VERSION "FM29 IBUS1 + IBUS2, V390.1 20230120, generated by sunnypilot/webhud/tools/gen_ibus.py"

NS_ :

BS_:

BU_: ADAS AMP FloatingButtons GW ICC MFSS PWC_L PWC_R RAC Rotator

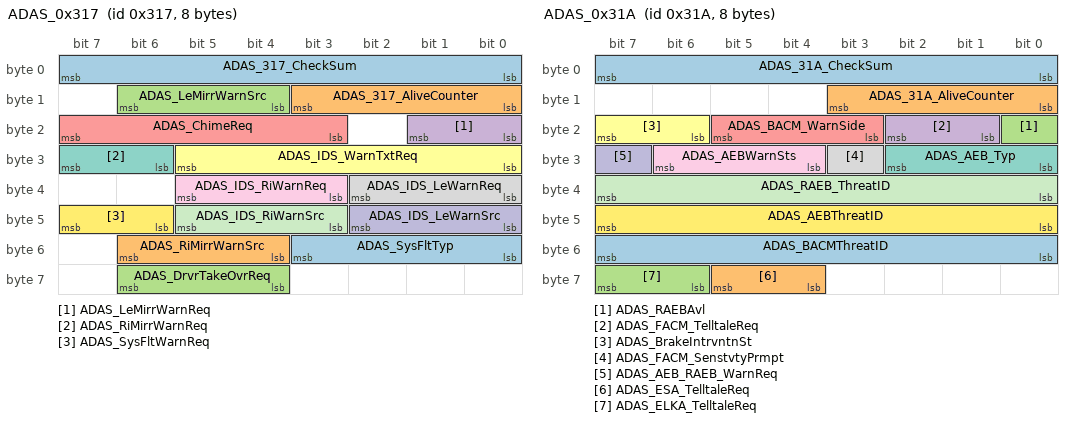
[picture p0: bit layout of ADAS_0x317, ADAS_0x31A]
BO_ 791 ADAS_0x317: 8 ADAS
 SG_ ADAS_317_CheckSum : 7|8@0+ (1,0) [0|255] "" ICC
 SG_ ADAS_317_AliveCounter : 11|4@0+ (1,0) [0|14] "" ICC
 SG_ ADAS_LeMirrWarnSrc : 14|3@0+ (1,0) [0|7] "" ICC
 SG_ ADAS_LeMirrWarnReq : 17|2@0+ (1,0) [0|3] "" ICC
 SG_ ADAS_ChimeReq : 23|5@0+ (1,0) [0|15] "" ICC
 SG_ ADAS_IDS_WarnTxtReq : 29|6@0+ (1,0) [0|63] "" ICC
 SG_ ADAS_RiMirrWarnReq : 31|2@0+ (1,0) [0|3] "" ICC
 SG_ ADAS_IDS_LeWarnReq : 34|3@0+ (1,0) [0|7] "" ICC
 SG_ ADAS_IDS_RiWarnReq : 37|3@0+ (1,0) [0|7] "" ICC
 SG_ ADAS_IDS_LeWarnSrc : 42|3@0+ (1,0) [0|7] "" ICC
 SG_ ADAS_IDS_RiWarnSrc : 45|3@0+ (1,0) [0|7] "" ICC
 SG_ ADAS_SysFltWarnReq : 47|2@0+ (1,0) [0|3] "" ICC
 SG_ ADAS_SysFltTyp : 51|4@0+ (1,0) [0|15] "" ICC
 SG_ ADAS_RiMirrWarnSrc : 54|3@0+ (1,0) [0|7] "" ICC
 SG_ ADAS_DrvrTakeOvrReq : 62|3@0+ (1,0) [0|7] "" ICC

BO_ 794 ADAS_0x31A: 8 ADAS
 SG_ ADAS_31A_CheckSum : 7|8@0+ (1,0) [0|255] "" ICC
 SG_ ADAS_31A_AliveCounter : 11|4@0+ (1,0) [0|14] "" ICC
 SG_ ADAS_RAEBAvl : 16|1@0+ (1,0) [0|1] "" ICC
 SG_ ADAS_FACM_TelltaleReq : 18|2@0+ (1,0) [0|3] "" ICC
 SG_ ADAS_BACM_WarnSide : 21|3@0+ (1,0) [0|7] "" ICC
 SG_ ADAS_BrakeIntrvntnSt : 23|2@0+ (1,0) [0|3] "" ICC
 SG_ ADAS_AEB_Typ : 26|3@0+ (1,0) [0|7] "" ICC
 SG_ ADAS_FACM_SenstvtyPrmpt : 27|1@0+ (1,0) [0|1] "" ICC
 SG_ ADAS_AEBWarnSts : 30|3@0+ (1,0) [0|7] "" ICC
 SG_ ADAS_AEB_RAEB_WarnReq : 31|1@0+ (1,0) [0|1] "" ICC
 SG_ ADAS_RAEB_ThreatID : 39|8@0+ (1,0) [0|255] "" ICC
 SG_ ADAS_AEBThreatID : 47|8@0+ (1,0) [0|255] "" ICC
 SG_ ADAS_BACMThreatID : 55|8@0+ (1,0) [0|255] "" ICC
 SG_ ADAS_ESA_TelltaleReq : 61|2@0+ (1,0) [0|3] "" ICC
 SG_ ADAS_ELKA_TelltaleReq : 63|2@0+ (1,0) [0|3] "" ICC

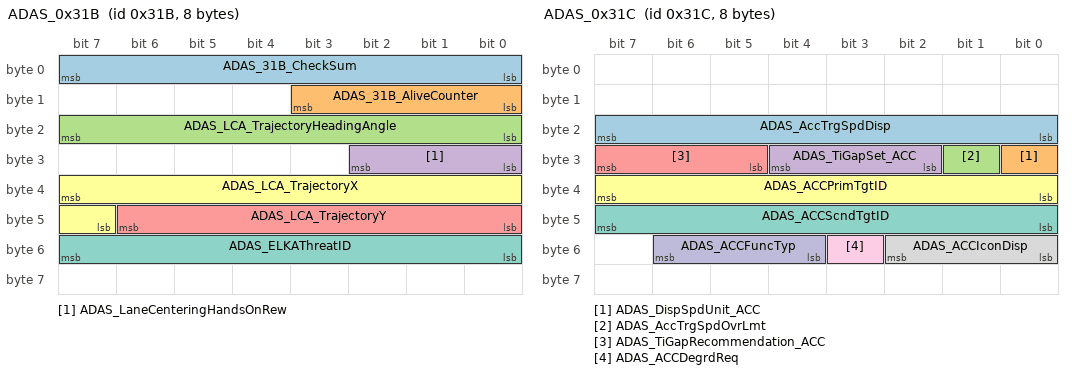
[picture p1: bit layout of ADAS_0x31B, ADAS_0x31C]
BO_ 795 ADAS_0x31B: 8 ADAS
 SG_ ADAS_31B_CheckSum : 7|8@0+ (1,0) [0|255] "" ICC
 SG_ ADAS_31B_AliveCounter : 11|4@0+ (1,0) [0|14] "" ICC
 SG_ ADAS_LCA_TrajectoryHeadingAngle : 23|8@0+ (1,-127) [-127|128] "" ICC
 SG_ ADAS_LaneCenteringHandsOnRew : 26|3@0+ (1,0) [0|7] "" ICC
 SG_ ADAS_LCA_TrajectoryY : 46|7@0+ (0.25,-63) [-63|-31.25] "" ICC
 SG_ ADAS_LCA_TrajectoryX : 39|9@0+ (1,0) [0|511] "" ICC
 SG_ ADAS_ELKAThreatID : 55|8@0+ (1,0) [0|255] "" ICC

BO_ 796 ADAS_0x31C: 8 ADAS
 SG_ ADAS_AccTrgSpdDisp : 23|8@0+ (1,0) [0|255] "" ICC
 SG_ ADAS_DispSpdUnit_ACC : 24|1@0+ (1,0) [0|1] "" ICC
 SG_ ADAS_AccTrgSpdOvrLmt : 25|1@0+ (1,0) [0|1] "" ICC
 SG_ ADAS_TiGapSet_ACC : 28|3@0+ (1,0) [0|7] "" ICC
 SG_ ADAS_TiGapRecommendation_ACC : 31|3@0+ (1,0) [0|7] "" ICC
 SG_ ADAS_ACCPrimTgtID : 39|8@0+ (1,0) [0|255] "" ICC
 SG_ ADAS_ACCScndTgtID : 47|8@0+ (1,0) [0|255] "" ICC
 SG_ ADAS_ACCIconDisp : 50|3@0+ (1,0) [0|7] "" ICC
 SG_ ADAS_ACCDegrdReq : 51|1@0+ (1,0) [0|1] "" ICC
 SG_ ADAS_ACCFuncTyp : 54|3@0+ (1,0) [0|7] "" ICC

BO_ 800 ICC_0x320: 8 ICC
 SG_ ICC_VehFlameoutTi : 7|16@0+ (1,0) [0|65535] "min" ICC
 SG_ ICC_VehFlameoutTiVld : 17|2@0+ (1,0) [0|3] "" ICC

BO_ 801 BCM_0x321: 8 GW
 SG_ BCM_AP_FL_LeFrntWinPosnInfo : 23|8@0+ (0.5,0) [0|100] "%" ICC
 SG_ BCM_AP_FL_RiFrntWinPosnInfo : 31|8@0+ (0.5,0) [0|100] "%" ICC
 SG_ BCM_AP_FL_LeReWinPosnInfo : 39|8@0+ (0.5,0) [0|100] "%" ICC
 SG_ BCM_AP_FL_RiReWinPosnInfo : 47|8@0+ (0.5,0) [0|100] "%" ICC
 SG_ BCM_ValueLightFrnt_RLS : 55|8@0+ (50,0) [0|12700] "w/m2" ICC
 SG_ BCM_LightReqReason_RLS : 60|5@0+ (1,0) [0|31] "" ICC

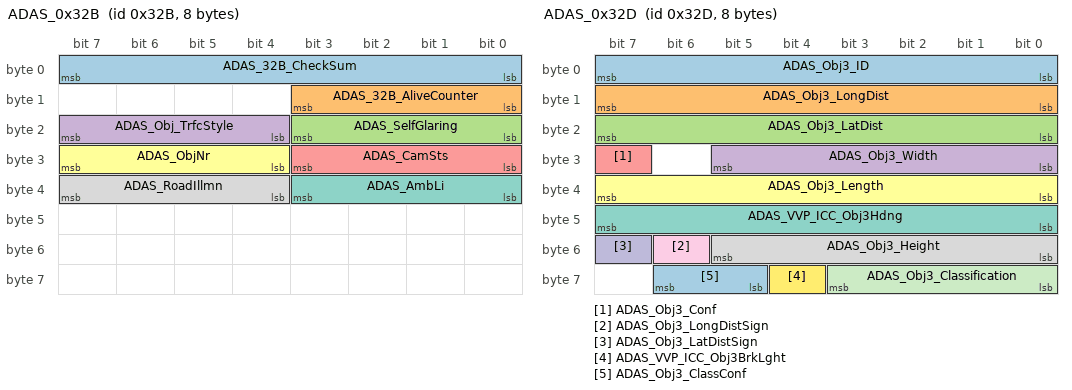
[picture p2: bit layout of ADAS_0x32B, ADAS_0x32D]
BO_ 811 ADAS_0x32B: 8 ADAS
 SG_ ADAS_32B_CheckSum : 7|8@0+ (1,0) [0|255] "" ICC
 SG_ ADAS_32B_AliveCounter : 11|4@0+ (1,0) [0|14] "" ICC
 SG_ ADAS_SelfGlaring : 19|4@0+ (1,0) [0|15] "" ICC
 SG_ ADAS_Obj_TrfcStyle : 23|4@0+ (1,0) [0|15] "" ICC
 SG_ ADAS_CamSts : 27|4@0+ (1,0) [0|15] "" ICC
 SG_ ADAS_ObjNr : 31|4@0+ (1,0) [0|15] "" ICC
 SG_ ADAS_AmbLi : 35|4@0+ (1,0) [0|15] "" ICC
 SG_ ADAS_RoadIllmn : 39|4@0+ (1,0) [0|15] "" ICC

BO_ 813 ADAS_0x32D: 8 ADAS
 SG_ ADAS_Obj3_ID : 7|8@0+ (1,0) [0|255] "" ICC
 SG_ ADAS_Obj3_LongDist : 15|8@0+ (0.2,0) [0|51] "m" ICC
 SG_ ADAS_Obj3_LatDist : 23|8@0+ (0.2,0) [0|51] "m" ICC
 SG_ ADAS_Obj3_Width : 29|6@0+ (0.1,0) [0|6.3] "m" ICC
 SG_ ADAS_Obj3_Conf : 31|1@0+ (1,0) [0|1] "" ICC
 SG_ ADAS_Obj3_Length : 39|8@0+ (0.2,0) [0|50] "m" ICC
 SG_ ADAS_VVP_ICC_Obj3Hdng : 47|8@0+ (1.5,0) [0|360] "deg" ICC
 SG_ ADAS_Obj3_Height : 53|6@0+ (0.1,0) [0|6.3] "m" ICC
 SG_ ADAS_Obj3_LongDistSign : 54|1@0+ (1,0) [0|1] "" ICC
 SG_ ADAS_Obj3_LatDistSign : 55|1@0+ (1,0) [0|1] "" ICC
 SG_ ADAS_Obj3_Classification : 59|4@0+ (1,0) [0|15] "" ICC
 SG_ ADAS_VVP_ICC_Obj3BrkLght : 60|1@0+ (1,0) [0|1] "" ICC
 SG_ ADAS_Obj3_ClassConf : 62|2@0+ (1,0) [0|3] "" ICC

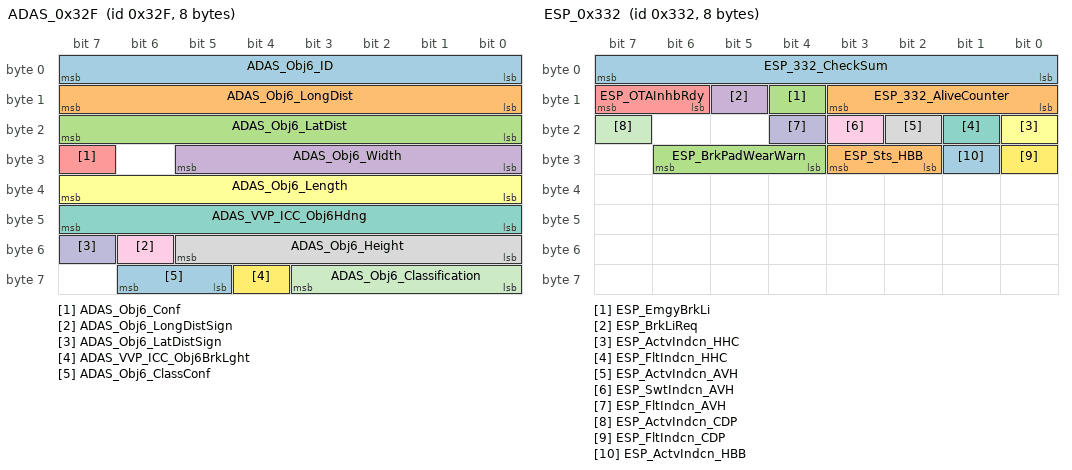
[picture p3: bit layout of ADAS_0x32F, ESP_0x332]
BO_ 815 ADAS_0x32F: 8 ADAS
 SG_ ADAS_Obj6_ID : 7|8@0+ (1,0) [0|255] "" ICC
 SG_ ADAS_Obj6_LongDist : 15|8@0+ (0.2,0) [0|51] "m" ICC
 SG_ ADAS_Obj6_LatDist : 23|8@0+ (0.2,0) [0|51] "m" ICC
 SG_ ADAS_Obj6_Width : 29|6@0+ (0.1,0) [0|6.3] "m" ICC
 SG_ ADAS_Obj6_Conf : 31|1@0+ (1,0) [0|1] "" ICC
 SG_ ADAS_Obj6_Length : 39|8@0+ (0.2,0) [0|50] "m" ICC
 SG_ ADAS_VVP_ICC_Obj6Hdng : 47|8@0+ (1.5,0) [0|360] "deg" ICC
 SG_ ADAS_Obj6_Height : 53|6@0+ (0.1,0) [0|6.3] "m" ICC
 SG_ ADAS_Obj6_LongDistSign : 54|1@0+ (1,0) [0|1] "" ICC
 SG_ ADAS_Obj6_LatDistSign : 55|1@0+ (1,0) [0|1] "" ICC
 SG_ ADAS_Obj6_Classification : 59|4@0+ (1,0) [0|15] "" ICC
 SG_ ADAS_VVP_ICC_Obj6BrkLght : 60|1@0+ (1,0) [0|1] "" ICC
 SG_ ADAS_Obj6_ClassConf : 62|2@0+ (1,0) [0|3] "" ICC

BO_ 818 ESP_0x332: 8 GW
 SG_ ESP_332_CheckSum : 7|8@0+ (1,0) [0|255] "" ICC
 SG_ ESP_332_AliveCounter : 11|4@0+ (1,0) [0|14] "" ICC
 SG_ ESP_EmgyBrkLi : 12|1@0+ (1,0) [0|1] "" ICC
 SG_ ESP_BrkLiReq : 13|1@0+ (1,0) [0|1] "" ICC
 SG_ ESP_OTAInhbRdy : 15|2@0+ (1,0) [0|3] "" ICC
 SG_ ESP_ActvIndcn_HHC : 16|1@0+ (1,0) [0|1] "" ICC
 SG_ ESP_FltIndcn_HHC : 17|1@0+ (1,0) [0|1] "" ICC
 SG_ ESP_ActvIndcn_AVH : 18|1@0+ (1,0) [0|1] "" ICC
 SG_ ESP_SwtIndcn_AVH : 19|1@0+ (1,0) [0|1] "" ICC
 SG_ ESP_FltIndcn_AVH : 20|1@0+ (1,0) [0|1] "" ICC
 SG_ ESP_ActvIndcn_CDP : 23|1@0+ (1,0) [0|1] "" ICC
 SG_ ESP_FltIndcn_CDP : 24|1@0+ (1,0) [0|1] "" ICC
 SG_ ESP_ActvIndcn_HBB : 25|1@0+ (1,0) [0|1] "" ICC
 SG_ ESP_Sts_HBB : 27|2@0+ (1,0) [0|3] "" ICC
 SG_ ESP_BrkPadWearWarn : 30|3@0+ (1,0) [0|7] "" ICC

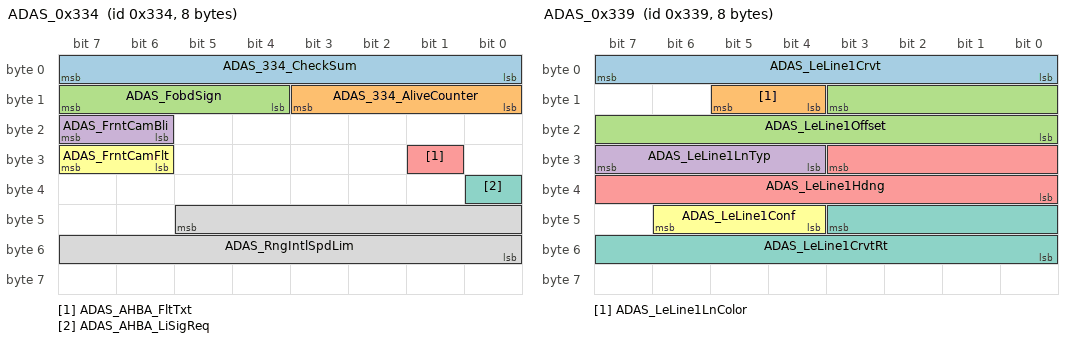
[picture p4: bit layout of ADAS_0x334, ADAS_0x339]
BO_ 820 ADAS_0x334: 8 ADAS
 SG_ ADAS_334_CheckSum : 7|8@0+ (1,0) [0|255] "" ICC
 SG_ ADAS_334_AliveCounter : 11|4@0+ (1,0) [0|14] "" ICC
 SG_ ADAS_FobdSign : 15|4@0+ (1,0) [0|15] "" ICC
 SG_ ADAS_FrntCamBli : 23|2@0+ (1,0) [0|3] "" ICC
 SG_ ADAS_AHBA_FltTxt : 25|1@0+ (1,0) [0|1] "" ICC
 SG_ ADAS_FrntCamFlt : 31|2@0+ (1,0) [0|3] "" ICC
 SG_ ADAS_AHBA_LiSigReq : 32|1@0+ (1,0) [0|1] "" ICC
 SG_ ADAS_RngIntlSpdLim : 45|14@0+ (10,0) [0|100000] "m" ICC

BO_ 825 ADAS_0x339: 8 ADAS
 SG_ ADAS_LeLine1Crvt : 7|8@0+ (50,-3150) [-3150|3200] "m" ICC
 SG_ ADAS_LeLine1LnColor : 13|2@0+ (1,0) [0|3] "" ICC
 SG_ ADAS_LeLine1Offset : 11|12@0+ (0.0125,0) [0|50] "m" ICC
 SG_ ADAS_LeLine1LnTyp : 31|4@0+ (1,0) [0|15] "" ICC
 SG_ ADAS_LeLine1Hdng : 27|12@0+ (0.05,0) [0|180] "deg" ICC
 SG_ ADAS_LeLine1Conf : 46|3@0+ (1,0) [0|7] "" ICC
 SG_ ADAS_LeLine1CrvtRt : 43|12@0+ (0.05,0) [0|180] "xx" ICC

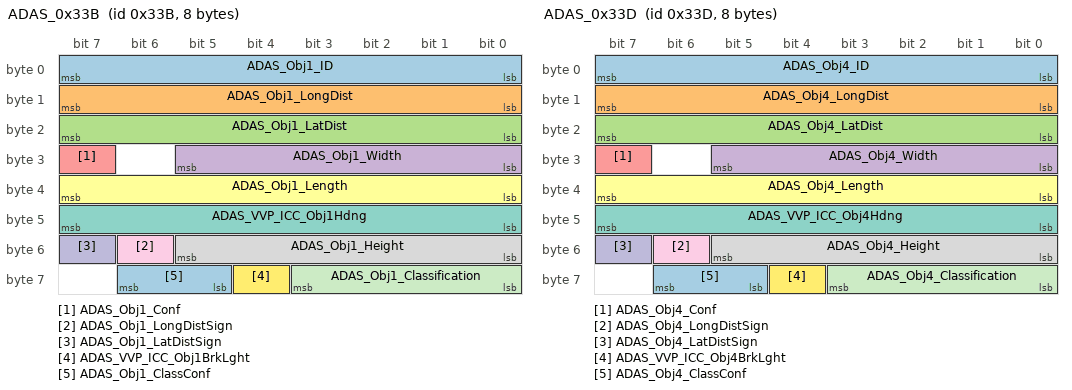
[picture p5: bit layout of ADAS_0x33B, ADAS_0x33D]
BO_ 827 ADAS_0x33B: 8 ADAS
 SG_ ADAS_Obj1_ID : 7|8@0+ (1,0) [0|255] "" ICC
 SG_ ADAS_Obj1_LongDist : 15|8@0+ (0.2,0) [0|51] "m" ICC
 SG_ ADAS_Obj1_LatDist : 23|8@0+ (0.2,0) [0|51] "m" ICC
 SG_ ADAS_Obj1_Width : 29|6@0+ (0.1,0) [0|6.3] "m" ICC
 SG_ ADAS_Obj1_Conf : 31|1@0+ (1,0) [0|1] "" ICC
 SG_ ADAS_Obj1_Length : 39|8@0+ (0.2,0) [0|50] "m" ICC
 SG_ ADAS_VVP_ICC_Obj1Hdng : 47|8@0+ (1.5,0) [0|360] "deg" ICC
 SG_ ADAS_Obj1_Height : 53|6@0+ (0.1,0) [0|6.3] "m" ICC
 SG_ ADAS_Obj1_LongDistSign : 54|1@0+ (1,0) [0|1] "" ICC
 SG_ ADAS_Obj1_LatDistSign : 55|1@0+ (1,0) [0|1] "" ICC
 SG_ ADAS_Obj1_Classification : 59|4@0+ (1,0) [0|15] "" ICC
 SG_ ADAS_VVP_ICC_Obj1BrkLght : 60|1@0+ (1,0) [0|1] "" ICC
 SG_ ADAS_Obj1_ClassConf : 62|2@0+ (1,0) [0|3] "" ICC

BO_ 829 ADAS_0x33D: 8 ADAS
 SG_ ADAS_Obj4_ID : 7|8@0+ (1,0) [0|255] "" ICC
 SG_ ADAS_Obj4_LongDist : 15|8@0+ (0.2,0) [0|51] "m" ICC
 SG_ ADAS_Obj4_LatDist : 23|8@0+ (0.2,0) [0|51] "m" ICC
 SG_ ADAS_Obj4_Width : 29|6@0+ (0.1,0) [0|6.3] "m" ICC
 SG_ ADAS_Obj4_Conf : 31|1@0+ (1,0) [0|1] "" ICC
 SG_ ADAS_Obj4_Length : 39|8@0+ (0.2,0) [0|50] "m" ICC
 SG_ ADAS_VVP_ICC_Obj4Hdng : 47|8@0+ (1.5,0) [0|360] "deg" ICC
 SG_ ADAS_Obj4_Height : 53|6@0+ (0.1,0) [0|6.3] "m" ICC
 SG_ ADAS_Obj4_LongDistSign : 54|1@0+ (1,0) [0|1] "" ICC
 SG_ ADAS_Obj4_LatDistSign : 55|1@0+ (1,0) [0|1] "" ICC
 SG_ ADAS_Obj4_Classification : 59|4@0+ (1,0) [0|15] "" ICC
 SG_ ADAS_VVP_ICC_Obj4BrkLght : 60|1@0+ (1,0) [0|1] "" ICC
 SG_ ADAS_Obj4_ClassConf : 62|2@0+ (1,0) [0|3] "" ICC

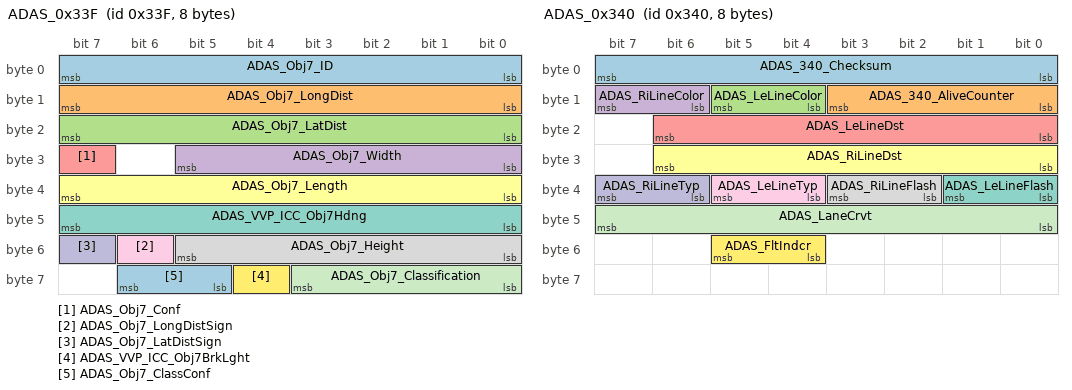
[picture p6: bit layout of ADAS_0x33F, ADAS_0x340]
BO_ 831 ADAS_0x33F: 8 ADAS
 SG_ ADAS_Obj7_ID : 7|8@0+ (1,0) [0|255] "" ICC
 SG_ ADAS_Obj7_LongDist : 15|8@0+ (0.2,0) [0|51] "m" ICC
 SG_ ADAS_Obj7_LatDist : 23|8@0+ (0.2,0) [0|51] "m" ICC
 SG_ ADAS_Obj7_Width : 29|6@0+ (0.1,0) [0|6.3] "m" ICC
 SG_ ADAS_Obj7_Conf : 31|1@0+ (1,0) [0|1] "" ICC
 SG_ ADAS_Obj7_Length : 39|8@0+ (0.2,0) [0|50] "m" ICC
 SG_ ADAS_VVP_ICC_Obj7Hdng : 47|8@0+ (1.5,0) [0|360] "deg" ICC
 SG_ ADAS_Obj7_Height : 53|6@0+ (0.1,0) [0|6.3] "m" ICC
 SG_ ADAS_Obj7_LongDistSign : 54|1@0+ (1,0) [0|1] "" ICC
 SG_ ADAS_Obj7_LatDistSign : 55|1@0+ (1,0) [0|1] "" ICC
 SG_ ADAS_Obj7_Classification : 59|4@0+ (1,0) [0|15] "" ICC
 SG_ ADAS_VVP_ICC_Obj7BrkLght : 60|1@0+ (1,0) [0|1] "" ICC
 SG_ ADAS_Obj7_ClassConf : 62|2@0+ (1,0) [0|3] "" ICC

BO_ 832 ADAS_0x340: 8 ADAS
 SG_ ADAS_340_Checksum : 7|8@0+ (1,0) [0|255] "" ICC
 SG_ ADAS_340_AliveCounter : 11|4@0+ (1,0) [0|14] "" ICC
 SG_ ADAS_LeLineColor : 13|2@0+ (1,0) [0|3] "" ICC
 SG_ ADAS_RiLineColor : 15|2@0+ (1,0) [0|3] "" ICC
 SG_ ADAS_LeLineDst : 22|7@0+ (0.1,-6.2) [-6.2|6.2] "m" ICC
 SG_ ADAS_RiLineDst : 30|7@0+ (0.1,-6.2) [-6.2|6.2] "m" ICC
 SG_ ADAS_LeLineFlash : 33|2@0+ (1,0) [0|3] "" ICC
 SG_ ADAS_RiLineFlash : 35|2@0+ (1,0) [0|3] "" ICC
 SG_ ADAS_LeLineTyp : 37|2@0+ (1,0) [0|3] "" ICC
 SG_ ADAS_RiLineTyp : 39|2@0+ (1,0) [0|3] "" ICC
 SG_ ADAS_LaneCrvt : 47|8@0+ (50,-3150) [-3150|3200] "m" ICC
 SG_ ADAS_FltIndcr : 53|2@0+ (1,0) [0|3] "" ICC

BO_ 834 ADAS_0x342: 8 ADAS
 SG_ ADAS_342_Checksum : 7|8@0+ (1,0) [0|255] "" ICC
 SG_ ADAS_342_AliveCounter : 11|4@0+ (1,0) [0|14] "" ICC
 SG_ ADAS_LatCtrl_LeTurnLampReq : 13|2@0+ (1,0) [0|3] "" ICC
 SG_ ADAS_LatCtrl_RiTurnLampReq : 15|2@0+ (1,0) [0|3] "" ICC
 SG_ ADAS_LatCtrl_HapticReq : 17|2@0+ (1,0) [0|3] "" ICC
 SG_ ADAS_LatCtrl_HzrdLampReq : 19|2@0+ (1,0) [0|3] "" ICC
 SG_ ADAS_VehMovDir : 21|2@0+ (1,0) [0|3] "" ICC
 SG_ ADAS_HOD_HandsOnWarnReq : 23|2@0+ (1,0) [0|1] "" ICC
 SG_ ADAS_DoorLockReq : 25|2@0+ (1,0) [0|3] "" ICC
 SG_ ADAS_AVASReq : 27|2@0+ (1,0) [0|3] "" ICC
 SG_ ADAS_RAPAvl : 28|1@0+ (1,0) [0|1] "" ICC
 SG_ ADAS_TPReplayAvl : 29|1@0+ (1,0) [0|1] "" ICC
 SG_ ADAS_TPReplaySuc : 30|1@0+ (1,0) [0|1] "" ICC
 SG_ ADAS_Sts_RAP : 34|3@0+ (1,0) [0|7] "" ICC
 SG_ ADAS_Sts_TP : 37|3@0+ (1,0) [0|7] "" ICC
 SG_ ADAS_ExtLightReq : 38|1@0+ (1,0) [0|1] "" ICC
 SG_ ADAS_HODSts : 42|3@0+ (1,0) [0|7] "" ICC

BO_ 836 ICC_0x344: 8 ICC
 SG_ ICC_NavMsgText1 : 7|64@0+ (1,0) [0|1.84467e+19] "" ICC

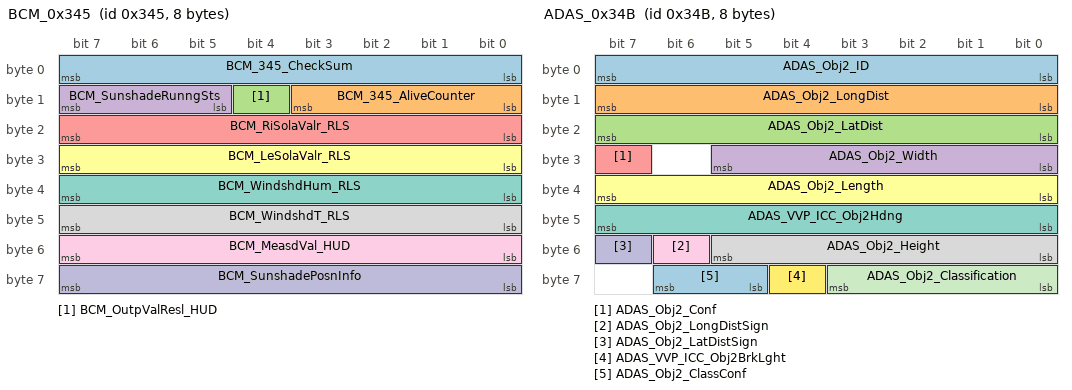
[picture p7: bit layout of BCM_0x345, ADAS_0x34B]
BO_ 837 BCM_0x345: 8 GW
 SG_ BCM_345_CheckSum : 7|8@0+ (1,0) [0|255] "" ICC
 SG_ BCM_345_AliveCounter : 11|4@0+ (1,0) [0|14] "" ICC
 SG_ BCM_OutpValResl_HUD : 12|1@0+ (1,0) [0|1] "" ICC
 SG_ BCM_SunshadeRunngSts : 15|3@0+ (1,0) [0|7] "" ICC
 SG_ BCM_RiSolaValr_RLS : 23|8@0+ (4.01575,0) [0|1024.02] "W/m2" ICC
 SG_ BCM_LeSolaValr_RLS : 31|8@0+ (4.01575,0) [0|1024.02] "W/m2" ICC
 SG_ BCM_WindshdHum_RLS : 39|8@0+ (0.5,0) [0|127.5] "%" ICC
 SG_ BCM_WindshdT_RLS : 47|8@0+ (0.5,-40) [-40|87.5] "Degree Celsius" ICC
 SG_ BCM_MeasdVal_HUD : 55|8@0+ (1,0) [0|255] "" ICC
 SG_ BCM_SunshadePosnInfo : 63|8@0+ (1,0) [0|100] "" ICC

BO_ 841 ICC_0x349: 8 ICC
 SG_ ICC_KaraokeMsgText1 : 7|64@0+ (1,0) [0|1.84467e+19] "" ICC

BO_ 843 ADAS_0x34B: 8 ADAS
 SG_ ADAS_Obj2_ID : 7|8@0+ (1,0) [0|255] "" ICC
 SG_ ADAS_Obj2_LongDist : 15|8@0+ (0.2,0) [0|51] "m" ICC
 SG_ ADAS_Obj2_LatDist : 23|8@0+ (0.2,0) [0|51] "m" ICC
 SG_ ADAS_Obj2_Width : 29|6@0+ (0.1,0) [0|6.3] "m" ICC
 SG_ ADAS_Obj2_Conf : 31|1@0+ (1,0) [0|1] "" ICC
 SG_ ADAS_Obj2_Length : 39|8@0+ (0.2,0) [0|50] "m" ICC
 SG_ ADAS_VVP_ICC_Obj2Hdng : 47|8@0+ (1.5,0) [0|360] "deg" ICC
 SG_ ADAS_Obj2_Height : 53|6@0+ (0.1,0) [0|6.3] "m" ICC
 SG_ ADAS_Obj2_LongDistSign : 54|1@0+ (1,0) [0|1] "" ICC
 SG_ ADAS_Obj2_LatDistSign : 55|1@0+ (1,0) [0|1] "" ICC
 SG_ ADAS_Obj2_Classification : 59|4@0+ (1,0) [0|15] "" ICC
 SG_ ADAS_VVP_ICC_Obj2BrkLght : 60|1@0+ (1,0) [0|1] "" ICC
 SG_ ADAS_Obj2_ClassConf : 62|2@0+ (1,0) [0|3] "" ICC

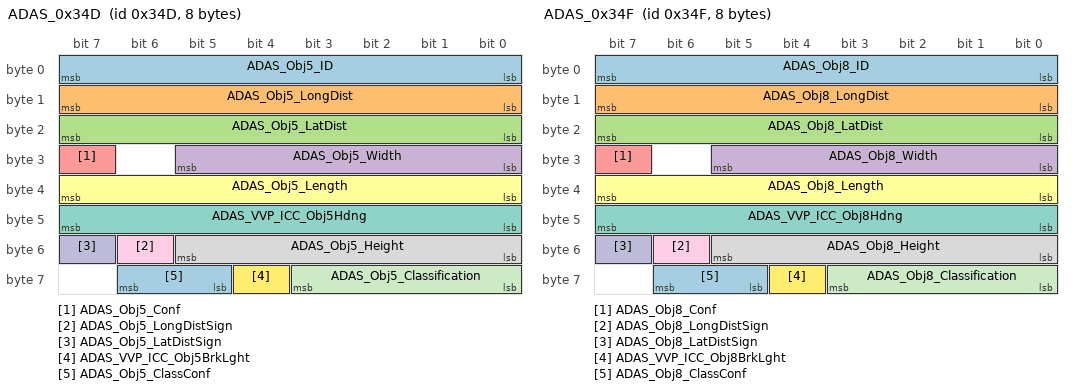
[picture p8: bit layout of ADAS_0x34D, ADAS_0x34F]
BO_ 845 ADAS_0x34D: 8 ADAS
 SG_ ADAS_Obj5_ID : 7|8@0+ (1,0) [0|255] "" ICC
 SG_ ADAS_Obj5_LongDist : 15|8@0+ (0.2,0) [0|51] "m" ICC
 SG_ ADAS_Obj5_LatDist : 23|8@0+ (0.2,0) [0|51] "m" ICC
 SG_ ADAS_Obj5_Width : 29|6@0+ (0.1,0) [0|6.3] "m" ICC
 SG_ ADAS_Obj5_Conf : 31|1@0+ (1,0) [0|1] "" ICC
 SG_ ADAS_Obj5_Length : 39|8@0+ (0.2,0) [0|50] "m" ICC
 SG_ ADAS_VVP_ICC_Obj5Hdng : 47|8@0+ (1.5,0) [0|360] "deg" ICC
 SG_ ADAS_Obj5_Height : 53|6@0+ (0.1,0) [0|6.3] "m" ICC
 SG_ ADAS_Obj5_LongDistSign : 54|1@0+ (1,0) [0|1] "" ICC
 SG_ ADAS_Obj5_LatDistSign : 55|1@0+ (1,0) [0|1] "" ICC
 SG_ ADAS_Obj5_Classification : 59|4@0+ (1,0) [0|15] "" ICC
 SG_ ADAS_VVP_ICC_Obj5BrkLght : 60|1@0+ (1,0) [0|1] "" ICC
 SG_ ADAS_Obj5_ClassConf : 62|2@0+ (1,0) [0|3] "" ICC

BO_ 847 ADAS_0x34F: 8 ADAS
 SG_ ADAS_Obj8_ID : 7|8@0+ (1,0) [0|255] "" ICC
 SG_ ADAS_Obj8_LongDist : 15|8@0+ (0.2,0) [0|51] "m" ICC
 SG_ ADAS_Obj8_LatDist : 23|8@0+ (0.2,0) [0|51] "m" ICC
 SG_ ADAS_Obj8_Width : 29|6@0+ (0.1,0) [0|6.3] "m" ICC
 SG_ ADAS_Obj8_Conf : 31|1@0+ (1,0) [0|1] "" ICC
 SG_ ADAS_Obj8_Length : 39|8@0+ (0.2,0) [0|50] "m" ICC
 SG_ ADAS_VVP_ICC_Obj8Hdng : 47|8@0+ (1.5,0) [0|360] "deg" ICC
 SG_ ADAS_Obj8_Height : 53|6@0+ (0.1,0) [0|6.3] "m" ICC
 SG_ ADAS_Obj8_LongDistSign : 54|1@0+ (1,0) [0|1] "" ICC
 SG_ ADAS_Obj8_LatDistSign : 55|1@0+ (1,0) [0|1] "" ICC
 SG_ ADAS_Obj8_Classification : 59|4@0+ (1,0) [0|15] "" ICC
 SG_ ADAS_VVP_ICC_Obj8BrkLght : 60|1@0+ (1,0) [0|1] "" ICC
 SG_ ADAS_Obj8_ClassConf : 62|2@0+ (1,0) [0|3] "" ICC

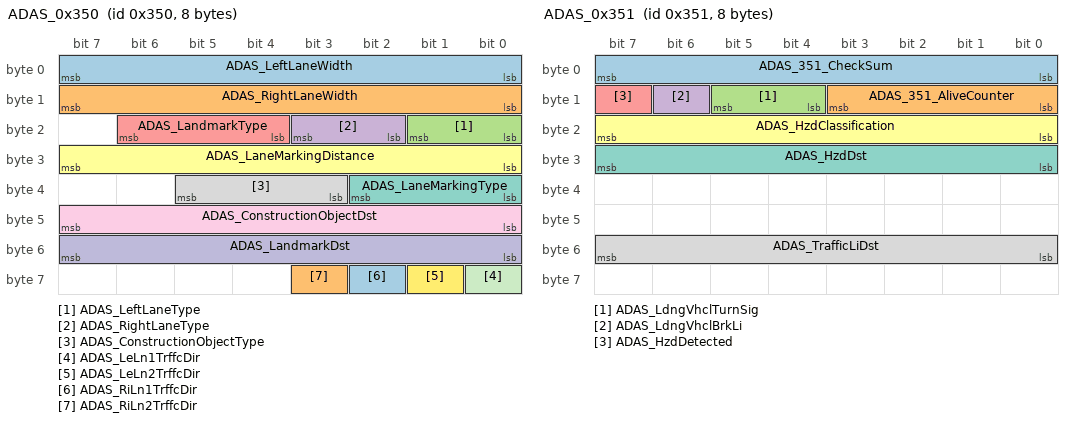
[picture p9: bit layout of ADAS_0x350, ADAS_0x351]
BO_ 848 ADAS_0x350: 8 ADAS
 SG_ ADAS_LeftLaneWidth : 7|8@0+ (0.1,0) [0|25.5] "m" ICC
 SG_ ADAS_RightLaneWidth : 15|8@0+ (0.1,0) [0|25.5] "m" ICC
 SG_ ADAS_LeftLaneType : 17|2@0+ (1,0) [0|3] "" ICC
 SG_ ADAS_RightLaneType : 19|2@0+ (1,0) [0|3] "" ICC
 SG_ ADAS_LandmarkType : 22|3@0+ (1,0) [0|7] "" ICC
 SG_ ADAS_LaneMarkingDistance : 31|8@0+ (1,0) [0|255] "m" ICC
 SG_ ADAS_LaneMarkingType : 34|3@0+ (1,0) [0|7] "" ICC
 SG_ ADAS_ConstructionObjectType : 37|3@0+ (1,0) [0|7] "" ICC
 SG_ ADAS_ConstructionObjectDst : 47|8@0+ (1,0) [0|255] "m" ICC
 SG_ ADAS_LandmarkDst : 55|8@0+ (1,0) [0|255] "m" ICC
 SG_ ADAS_LeLn1TrffcDir : 56|1@0+ (1,0) [0|1] "" ICC
 SG_ ADAS_LeLn2TrffcDir : 57|1@0+ (1,0) [0|1] "" ICC
 SG_ ADAS_RiLn1TrffcDir : 58|1@0+ (1,0) [0|1] "" ICC
 SG_ ADAS_RiLn2TrffcDir : 59|1@0+ (1,0) [0|1] "" ICC

BO_ 849 ADAS_0x351: 8 ADAS
 SG_ ADAS_351_CheckSum : 7|8@0+ (1,0) [0|255] "" ICC
 SG_ ADAS_351_AliveCounter : 11|4@0+ (1,0) [0|14] "" ICC
 SG_ ADAS_LdngVhclTurnSig : 13|2@0+ (1,0) [0|3] "" ICC
 SG_ ADAS_LdngVhclBrkLi : 14|1@0+ (1,0) [0|1] "" ICC
 SG_ ADAS_HzdDetected : 15|1@0+ (1,0) [0|1] "" ICC
 SG_ ADAS_HzdClassification : 23|8@0+ (1,0) [0|255] "" ICC
 SG_ ADAS_HzdDst : 31|8@0+ (1,0) [0|255] "m" ICC
 SG_ ADAS_TrafficLiDst : 55|8@0+ (1,0) [0|255] "m" ICC

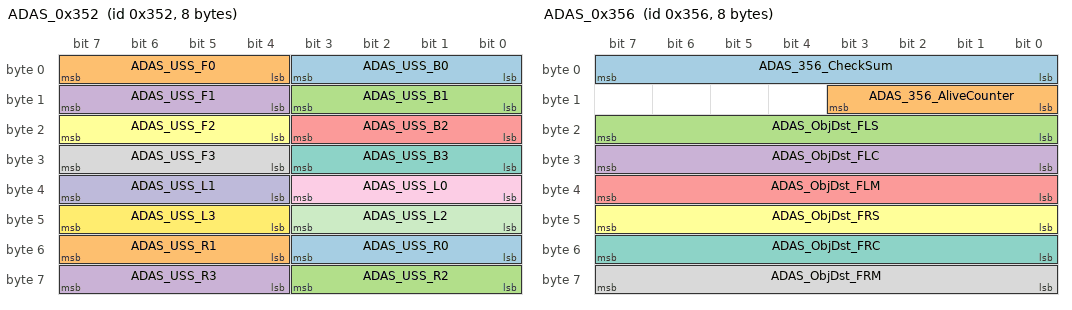
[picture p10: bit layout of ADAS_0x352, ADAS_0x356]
BO_ 850 ADAS_0x352: 8 ADAS
 SG_ ADAS_USS_B0 : 3|4@0+ (1,0) [0|15] "" ICC
 SG_ ADAS_USS_F0 : 7|4@0+ (1,0) [0|15] "" ICC
 SG_ ADAS_USS_B1 : 11|4@0+ (1,0) [0|15] "" ICC
 SG_ ADAS_USS_F1 : 15|4@0+ (1,0) [0|15] "" ICC
 SG_ ADAS_USS_B2 : 19|4@0+ (1,0) [0|15] "" ICC
 SG_ ADAS_USS_F2 : 23|4@0+ (1,0) [0|15] "" ICC
 SG_ ADAS_USS_B3 : 27|4@0+ (1,0) [0|15] "" ICC
 SG_ ADAS_USS_F3 : 31|4@0+ (1,0) [0|15] "" ICC
 SG_ ADAS_USS_L0 : 35|4@0+ (1,0) [0|15] "" ICC
 SG_ ADAS_USS_L1 : 39|4@0+ (1,0) [0|15] "" ICC
 SG_ ADAS_USS_L2 : 43|4@0+ (1,0) [0|15] "" ICC
 SG_ ADAS_USS_L3 : 47|4@0+ (1,0) [0|15] "" ICC
 SG_ ADAS_USS_R0 : 51|4@0+ (1,0) [0|15] "" ICC
 SG_ ADAS_USS_R1 : 55|4@0+ (1,0) [0|15] "" ICC
 SG_ ADAS_USS_R2 : 59|4@0+ (1,0) [0|15] "" ICC
 SG_ ADAS_USS_R3 : 63|4@0+ (1,0) [0|15] "" ICC

BO_ 851 ADAS_0x353: 8 ADAS
 SG_ ADAS_353_CheckSum : 7|8@0+ (1,0) [0|255] "" ICC
 SG_ ADAS_353_AliveCounter : 11|4@0+ (1,0) [0|14] "" ICC
 SG_ ADAS_VwPrtCamAngl : 23|4@0+ (1,0) [0|15] "" ICC
 SG_ ADAS_LdngVhclID : 31|8@0+ (1,0) [0|255] "" ICC

BO_ 854 ADAS_0x356: 8 ADAS
 SG_ ADAS_356_CheckSum : 7|8@0+ (1,0) [0|255] "" ICC
 SG_ ADAS_356_AliveCounter : 11|4@0+ (1,0) [0|14] "" ICC
 SG_ ADAS_ObjDst_FLS : 23|8@0+ (1,0) [0|255] "cm" ICC
 SG_ ADAS_ObjDst_FLC : 31|8@0+ (1,0) [0|255] "cm" ICC
 SG_ ADAS_ObjDst_FLM : 39|8@0+ (1,0) [0|255] "cm" ICC
 SG_ ADAS_ObjDst_FRS : 47|8@0+ (1,0) [0|255] "cm" ICC
 SG_ ADAS_ObjDst_FRC : 55|8@0+ (1,0) [0|255] "cm" ICC
 SG_ ADAS_ObjDst_FRM : 63|8@0+ (1,0) [0|255] "cm" ICC

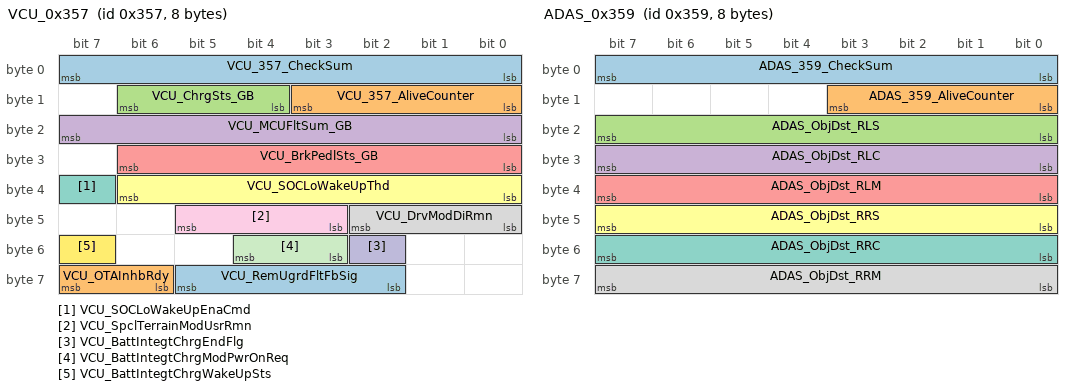
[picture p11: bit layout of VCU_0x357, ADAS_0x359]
BO_ 855 VCU_0x357: 8 GW
 SG_ VCU_357_CheckSum : 7|8@0+ (1,0) [0|255] "" ICC
 SG_ VCU_357_AliveCounter : 11|4@0+ (1,0) [0|14] "" ICC
 SG_ VCU_ChrgSts_GB : 14|3@0+ (1,0) [0|7] "" ICC
 SG_ VCU_MCUFltSum_GB : 23|8@0+ (1,0) [0|255] "" ICC
 SG_ VCU_BrkPedlSts_GB : 30|7@0+ (1,0) [0|127] "" ICC
 SG_ VCU_SOCLoWakeUpThd : 38|7@0+ (1,0) [0|100] "%" ICC
 SG_ VCU_SOCLoWakeUpEnaCmd : 39|1@0+ (1,0) [0|1] "" ICC
 SG_ VCU_DrvModDiRmn : 42|3@0+ (1,0) [0|7] "" ICC
 SG_ VCU_SpclTerrainModUsrRmn : 45|3@0+ (1,0) [0|7] "" ICC
 SG_ VCU_BattIntegtChrgEndFlg : 50|1@0+ (1,0) [0|1] "" ICC
 SG_ VCU_BattIntegtChrgModPwrOnReq : 52|2@0+ (1,0) [0|3] "" ICC
 SG_ VCU_BattIntegtChrgWakeUpSts : 55|1@0+ (1,0) [0|1] "" ICC
 SG_ VCU_RemUgrdFltFbSig : 61|4@0+ (1,0) [0|15] "" ICC
 SG_ VCU_OTAInhbRdy : 63|2@0+ (1,0) [0|3] "" ICC

BO_ 857 ADAS_0x359: 8 ADAS
 SG_ ADAS_359_CheckSum : 7|8@0+ (1,0) [0|255] "" ICC
 SG_ ADAS_359_AliveCounter : 11|4@0+ (1,0) [0|14] "" ICC
 SG_ ADAS_ObjDst_RLS : 23|8@0+ (1,0) [0|255] "cm" ICC
 SG_ ADAS_ObjDst_RLC : 31|8@0+ (1,0) [0|255] "cm" ICC
 SG_ ADAS_ObjDst_RLM : 39|8@0+ (1,0) [0|255] "cm" ICC
 SG_ ADAS_ObjDst_RRS : 47|8@0+ (1,0) [0|255] "cm" ICC
 SG_ ADAS_ObjDst_RRC : 55|8@0+ (1,0) [0|255] "cm" ICC
 SG_ ADAS_ObjDst_RRM : 63|8@0+ (1,0) [0|255] "cm" ICC

BO_ 859 ICC_0x35B: 8 ICC
 SG_ ICC_ViewReq : 15|4@0+ (1,0) [0|15] "" ICC
 SG_ ICC_ShowSts : 16|1@0+ (1,0) [0|1] "" ICC
 SG_ ICC_SVS_AutoVwBttnReq : 17|1@0+ (1,0) [0|1] "" ICC
 SG_ ICC_SVS_CamVwCnclReq : 18|1@0+ (1,0) [0|1] "" ICC
 SG_ ICC_AutomaticViewReq : 19|1@0+ (1,0) [0|1] "" ICC
 SG_ ICC_360FreeFloatingReq : 20|1@0+ (1,0) [0|1] "" ICC
 SG_ ICC_GraphicOverlayReq : 21|1@0+ (1,0) [0|1] "" ICC
 SG_ ICC_OperationType : 23|2@0+ (1,0) [0|3] "" ICC
 SG_ ICC_ZOOM_Start : 24|1@0+ (1,0) [0|1] "" ICC
 SG_ ICC_ZOOM_End : 25|1@0+ (1,0) [0|1] "" ICC
 SG_ ICC_ZOOM_ScalingFactor : 30|5@0+ (1,0) [0|31] "" ICC
 SG_ ICC_EnbLnChgAsst : 31|1@0+ (1,0) [0|1] "" ICC
 SG_ ICC_BSDSetting : 33|2@0+ (1,0) [0|3] "" ICC
 SG_ ICC_DOW_Setting : 35|2@0+ (1,0) [0|3] "" ICC
 SG_ ICC_DCAASetting : 37|2@0+ (1,0) [0|3] "" ICC
 SG_ ICC_APA_Setting : 39|2@0+ (1,0) [0|3] "" ICC
 SG_ ICC_APAParkSelect : 43|4@0+ (1,0) [0|15] "" ICC
 SG_ ICC_APAActivation : 44|1@0+ (1,0) [0|1] "" ICC
 SG_ ICC_APAParkInDirSetting : 45|1@0+ (1,0) [0|1] "" ICC
 SG_ ICC_APAParkOutDirSetting : 46|1@0+ (1,0) [0|1] "" ICC
 SG_ ICC_ParkAsstChmAlrt : 47|1@0+ (1,0) [0|1] "" ICC
 SG_ ICC_WSPPA_Setting : 49|2@0+ (1,0) [0|3] "" ICC
 SG_ ICC_AHBA_Setting : 50|1@0+ (1,0) [0|1] "" ICC
 SG_ ICC_APAParkOutAct : 52|2@0+ (1,0) [0|3] "" ICC
 SG_ ICC_SteerWhlVibrSet : 53|1@0+ (1,0) [0|1] "" ICC
 SG_ ICC_WarnTypeSetting : 55|2@0+ (1,0) [0|3] "" ICC
 SG_ ICC_LKA_SettingWrnTyp : 57|2@0+ (1,0) [0|3] "" ICC
 SG_ ICC_RAP_Setting : 59|2@0+ (1,0) [0|3] "" ICC
 SG_ ICC_TP_Setting : 61|2@0+ (1,0) [0|3] "" ICC
 SG_ ICC_BSD_Sensitivity : 63|2@0+ (1,0) [0|3] "" ICC

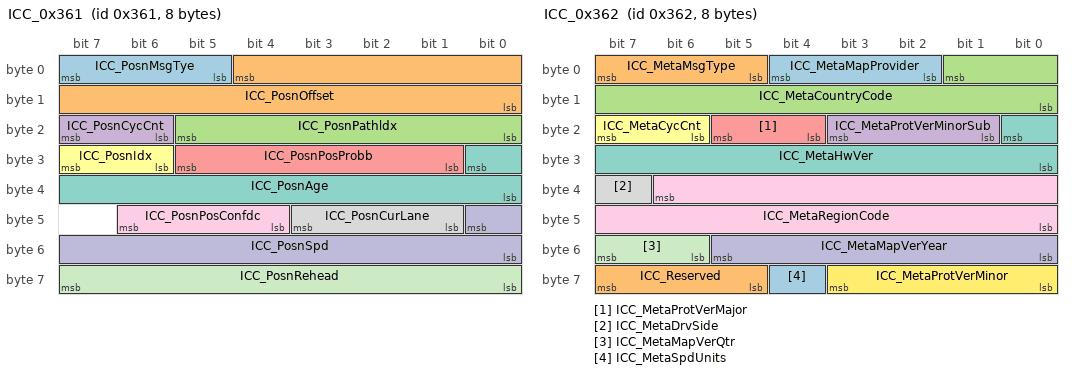
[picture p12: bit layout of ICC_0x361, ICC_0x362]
BO_ 865 ICC_0x361: 8 ICC
 SG_ ICC_PosnMsgTye : 7|3@0+ (1,0) [0|7] "" ICC
 SG_ ICC_PosnOffset : 4|13@0+ (1,0) [0|8190] "m" ICC
 SG_ ICC_PosnPathldx : 21|6@0+ (1,0) [8|63] "" ICC
 SG_ ICC_PosnCycCnt : 23|2@0+ (1,0) [0|3] "" ICC
 SG_ ICC_PosnPosProbb : 29|5@0+ (3.333,0) [0|100] "%" ICC
 SG_ ICC_PosnIdx : 31|2@0+ (1,0) [0|3] "" ICC
 SG_ ICC_PosnAge : 24|9@0+ (5,0) [0|2545] "ms" ICC
 SG_ ICC_PosnCurLane : 43|3@0+ (1,0) [0|7] "" ICC
 SG_ ICC_PosnPosConfdc : 46|3@0+ (1,0) [0|7] "" ICC
 SG_ ICC_PosnSpd : 40|9@0+ (0.2,-12.8) [-12.8|89.2] "m/s" ICC
 SG_ ICC_PosnRehead : 63|8@0+ (1.417,0) [0|358.583] "degrees" ICC

BO_ 866 ICC_0x362: 8 ICC
 SG_ ICC_MetaMapProvider : 4|3@0+ (1,0) [0|7] "m" ICC
 SG_ ICC_MetaMsgType : 7|3@0+ (1,0) [0|7] "" ICC
 SG_ ICC_MetaCountryCode : 1|10@0+ (1,0) [0|1023] "" ICC
 SG_ ICC_MetaProtVerMinorSub : 19|3@0+ (1,0) [0|7] "" ICC
 SG_ ICC_MetaProtVerMajor : 21|2@0+ (1,0) [0|3] "" ICC
 SG_ ICC_MetaCycCnt : 23|2@0+ (1,0) [0|3] "" ICC
 SG_ ICC_MetaHwVer : 16|9@0+ (1,0) [0|511] "" ICC
 SG_ ICC_MetaDrvSide : 39|1@0+ (1,0) [0|1] "" ICC
 SG_ ICC_MetaRegionCode : 38|15@0+ (1,0) [0|32767] "" ICC
 SG_ ICC_MetaMapVerYear : 53|6@0+ (1,2000) [2000|2063] "" ICC
 SG_ ICC_MetaMapVerQtr : 55|2@0+ (1,1) [1|3] "" ICC
 SG_ ICC_MetaProtVerMinor : 59|4@0+ (1,0) [0|15] "" ICC
 SG_ ICC_MetaSpdUnits : 60|1@0+ (1,0) [0|1] "" ICC
 SG_ ICC_Reserved : 63|3@0+ (1,0) [0|7] "" ICC

BO_ 867 VCU_0x363: 8 GW
 SG_ VCU_ACDchaStrtFailReason : 10|3@0+ (1,0) [0|7] "" ICC
 SG_ VCU_AllwRemHeatgSts : 14|3@0+ (1,0) [0|7] "" ICC
 SG_ VCU_FbRemHeatgOperSts : 15|1@0+ (1,0) [0|1] "" ICC
 SG_ VCU_ChrgEndSOCCrtCtrlFlg : 17|2@0+ (1,0) [0|3] "" ICC
 SG_ VCU_Lvl2ProtStrtFlg : 18|1@0+ (1,0) [0|1] "" ICC
 SG_ VCU_TotOverVoltLvl2ProtFlg : 19|1@0+ (1,0) [0|1] "" ICC
 SG_ VCU_UnderVoltFltLvl2ProtFlg : 20|1@0+ (1,0) [0|1] "" ICC
 SG_ VCU_OverTFltLvl2ProtFlg : 21|1@0+ (1,0) [0|1] "" ICC
 SG_ VCU_OverVoltFltLvl2ProtFlg : 22|1@0+ (1,0) [0|1] "" ICC
 SG_ VCU_CellIntShoFltLvl2ProtFlg : 23|1@0+ (1,0) [0|1] "" ICC
 SG_ VCU_InsulFltLvl2ProtFlg : 24|1@0+ (1,0) [0|1] "" ICC
 SG_ VCU_VehCfgExchgFlg : 25|1@0+ (1,0) [0|1] "" ICC
 SG_ VCU_ReadEEFailFlg : 26|1@0+ (1,0) [0|1] "" ICC
 SG_ VCU_WrEEFailFlg : 27|1@0+ (1,0) [0|1] "" ICC
 SG_ VCU_FirstUseEEFlg : 28|1@0+ (1,0) [0|1] "" ICC
 SG_ VCU_SwUpdataFlg : 29|1@0+ (1,0) [0|1] "" ICC
 SG_ VCU_NewOldEESwtFlg : 30|1@0+ (1,0) [0|1] "" ICC
 SG_ VCU_FSCFillEndFlg : 31|1@0+ (1,0) [0|1] "" ICC
 SG_ VCU_MaxAlrmLvl : 33|2@0+ (1,0) [0|3] "" ICC
 SG_ VCU_UsrStopChrgReqSts : 35|2@0+ (1,0) [0|3] "" ICC
 SG_ VCU_DchaIndcrLampCtrlCmd : 36|1@0+ (1,0) [0|1] "" ICC
 SG_ VCU_VehExtDchaSts : 39|3@0+ (1,0) [0|7] "" ICC
 SG_ VCU_S1SwtCmd : 41|2@0+ (1,0) [0|3] "" ICC
 SG_ VCU_DchaFltStsIndcn : 42|1@0+ (1,0) [0|1] "" ICC
 SG_ VCU_DchaUsrSetThd : 43|1@0+ (1,0) [0|1] "" ICC
 SG_ VCU_RemHeatgDmd : 45|2@0+ (1,0) [0|3] "" ICC
 SG_ VCU_PwrBattHeatgTyp : 47|2@0+ (1,0) [0|3] "" ICC
 SG_ VCU_RemPwrBattPreheatgDmdTi : 55|8@0+ (1,0) [0|255] "min" ICC
 SG_ VCU_ChrgInsulFctOpenSts : 56|1@0+ (1,0) [0|1] "" ICC
 SG_ VCU_ChrgEquipPwrNotEngh : 59|2@0+ (1,0) [0|3] "" ICC
 SG_ VCU_ACChrgStrtFailReason : 62|3@0+ (1,0) [0|7] "" ICC

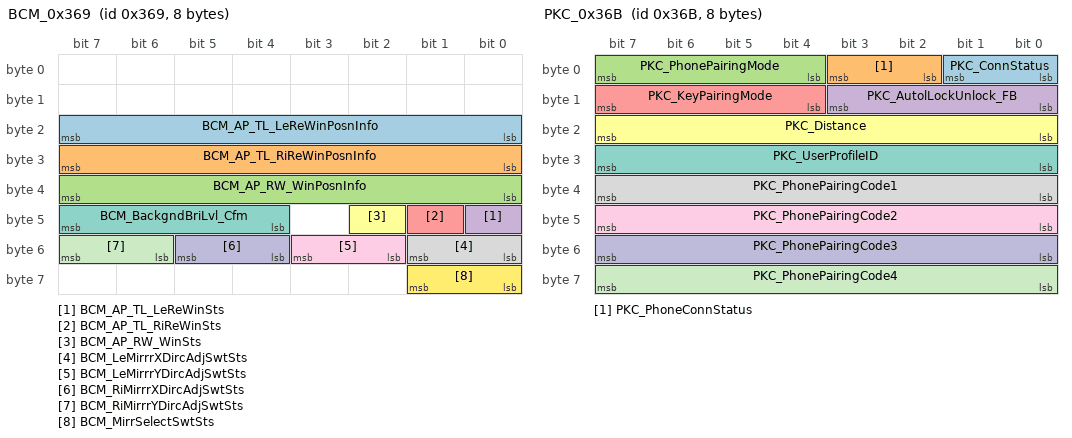
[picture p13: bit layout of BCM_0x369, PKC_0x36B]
BO_ 873 BCM_0x369: 8 GW
 SG_ BCM_AP_TL_LeReWinPosnInfo : 23|8@0+ (0.5,0) [0|100] "%" ICC
 SG_ BCM_AP_TL_RiReWinPosnInfo : 31|8@0+ (0.5,0) [0|100] "%" ICC
 SG_ BCM_AP_RW_WinPosnInfo : 39|8@0+ (0.5,0) [0|100] "%" ICC
 SG_ BCM_AP_TL_LeReWinSts : 40|1@0+ (1,0) [0|1] "" ICC
 SG_ BCM_AP_TL_RiReWinSts : 41|1@0+ (1,0) [0|1] "" ICC
 SG_ BCM_AP_RW_WinSts : 42|1@0+ (1,0) [0|1] "" ICC
 SG_ BCM_BackgndBriLvl_Cfm : 47|4@0+ (1,0) [0|15] "" ICC
 SG_ BCM_LeMirrrXDircAdjSwtSts : 49|2@0+ (1,0) [0|3] "" ICC
 SG_ BCM_LeMirrrYDircAdjSwtSts : 51|2@0+ (1,0) [0|3] "" ICC
 SG_ BCM_RiMirrrXDircAdjSwtSts : 53|2@0+ (1,0) [0|3] "" ICC
 SG_ BCM_RiMirrrYDircAdjSwtSts : 55|2@0+ (1,0) [0|3] "" ICC
 SG_ BCM_MirrSelectSwtSts : 57|2@0+ (1,0) [0|3] "" ICC

BO_ 874 PKC_0x36A: 8 GW
 SG_ PKC_KeySerialNumber_0 : 7|8@0+ (1,0) [0|255] "" ICC
 SG_ PKC_KeySerialNumber_1 : 15|8@0+ (1,0) [0|255] "" ICC
 SG_ PKC_KeySerialNumber_2 : 23|8@0+ (1,0) [0|255] "" ICC
 SG_ PKC_KeySerialNumber_3 : 31|8@0+ (1,0) [0|255] "" ICC
 SG_ PKC_KeySerialNumber_4 : 39|8@0+ (1,0) [0|255] "" ICC
 SG_ PKC_KeySerialNumber_5 : 47|8@0+ (1,0) [0|255] "" ICC
 SG_ PKC_KeySerialNumber_6 : 55|8@0+ (1,0) [0|255] "" ICC
 SG_ PKC_KeySerialNumber_7 : 63|8@0+ (1,0) [0|255] "" ICC

BO_ 875 PKC_0x36B: 8 GW
 SG_ PKC_ConnStatus : 1|2@0+ (1,0) [0|3] "" ICC
 SG_ PKC_PhoneConnStatus : 3|2@0+ (1,0) [0|3] "" ICC
 SG_ PKC_PhonePairingMode : 7|4@0+ (1,0) [0|15] "" ICC
 SG_ PKC_AutolLockUnlock_FB : 11|4@0+ (1,0) [0|15] "" ICC
 SG_ PKC_KeyPairingMode : 15|4@0+ (1,0) [0|15] "" ICC
 SG_ PKC_Distance : 23|8@0+ (1,0) [0|255] "" ICC
 SG_ PKC_UserProfileID : 31|8@0+ (1,0) [0|255] "" ICC
 SG_ PKC_PhonePairingCode1 : 39|8@0+ (1,0) [0|255] "" ICC
 SG_ PKC_PhonePairingCode2 : 47|8@0+ (1,0) [0|255] "" ICC
 SG_ PKC_PhonePairingCode3 : 55|8@0+ (1,0) [0|255] "" ICC
 SG_ PKC_PhonePairingCode4 : 63|8@0+ (1,0) [0|255] "" ICC

BO_ 876 PKC_0x36C: 8 GW
 SG_ PKC_PhoneAdvName1 : 7|64@0+ (1,0) [0|65535] "" ICC

BO_ 877 PKC_0x36D: 8 GW
 SG_ PKC_NFCKeyID : 7|8@0+ (1,0) [0|255] "" ICC
 SG_ PKC_NFCTagStatus : 9|2@0+ (1,0) [0|3] "" ICC
 SG_ PKC_NFCTagAuthStatus : 13|4@0+ (1,0) [0|15] "" ICC
 SG_ PKC_NFCReaderExtStatus : 19|4@0+ (1,0) [0|15] "" ICC
 SG_ PKC_NFCReaderIntStatus : 23|4@0+ (1,0) [0|15] "" ICC

BO_ 878 PKC_0x36E: 8 GW
 SG_ PKC_NFCSerialNumber_0 : 7|8@0+ (1,0) [0|255] "" ICC
 SG_ PKC_NFCSerialNumber_1 : 15|8@0+ (1,0) [0|255] "" ICC
 SG_ PKC_NFCSerialNumber_2 : 23|8@0+ (1,0) [0|255] "" ICC
 SG_ PKC_NFCSerialNumber_3 : 31|8@0+ (1,0) [0|255] "" ICC
 SG_ PKC_NFCSerialNumber_4 : 39|8@0+ (1,0) [0|255] "" ICC
 SG_ PKC_NFCSerialNumber_5 : 47|8@0+ (1,0) [0|255] "" ICC
 SG_ PKC_NFCSerialNumber_6 : 55|8@0+ (1,0) [0|255] "" ICC
 SG_ PKC_NFCSerialNumber_7 : 63|8@0+ (1,0) [0|255] "" ICC

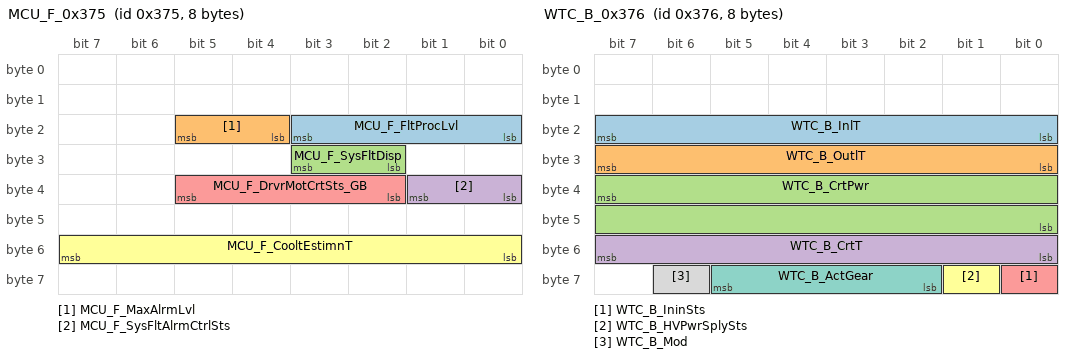
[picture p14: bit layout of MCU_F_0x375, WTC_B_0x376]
BO_ 885 MCU_F_0x375: 8 GW
 SG_ MCU_F_FltProcLvl : 19|4@0+ (1,0) [0|15] "" ICC
 SG_ MCU_F_MaxAlrmLvl : 21|2@0+ (1,0) [0|3] "" ICC
 SG_ MCU_F_SysFltDisp : 27|2@0+ (1,0) [0|3] "" ICC
 SG_ MCU_F_SysFltAlrmCtrlSts : 33|2@0+ (1,0) [0|3] "" ICC
 SG_ MCU_F_DrvrMotCrtSts_GB : 37|4@0+ (1,0) [0|15] "" ICC
 SG_ MCU_F_CooltEstimnT : 55|8@0+ (1,-48) [-48|200] "Degree Celsius" ICC

BO_ 886 WTC_B_0x376: 8 GW
 SG_ WTC_B_InlT : 23|8@0+ (1,-48) [-48|207] "Degree Celsius" ICC
 SG_ WTC_B_OutlT : 31|8@0+ (1,-48) [-48|207] "Degree Celsius" ICC
 SG_ WTC_B_CrtPwr : 39|16@0+ (1,0) [0|10000] "" ICC
 SG_ WTC_B_CrtT : 55|8@0+ (1,-48) [-48|207] "Degree Celsius" ICC
 SG_ WTC_B_IninSts : 56|1@0+ (1,0) [0|1] "" ICC
 SG_ WTC_B_HVPwrSplySts : 57|1@0+ (1,0) [0|1] "" ICC
 SG_ WTC_B_ActGear : 61|4@0+ (1,0) [0|15] "" ICC
 SG_ WTC_B_Mod : 62|1@0+ (1,0) [0|1] "" ICC

BO_ 887 MCU_R_0x377: 8 GW
 SG_ MCU_R_FltProcLvl : 19|4@0+ (1,0) [0|15] "" ICC
 SG_ MCU_R_MaxAlrmLvl : 21|2@0+ (1,0) [0|3] "" ICC
 SG_ MCU_R_SysFltDisp : 27|2@0+ (1,0) [0|3] "" ICC
 SG_ MCU_R_SysFltAlrmCtrlSts : 33|2@0+ (1,0) [0|3] "" ICC
 SG_ MCU_R_DrvrMotCrtSts_GB : 37|4@0+ (1,0) [0|15] "" ICC
 SG_ MCU_R_CooltEstimnT : 55|8@0+ (1,-48) [-48|200] "Degree Celsius" ICC

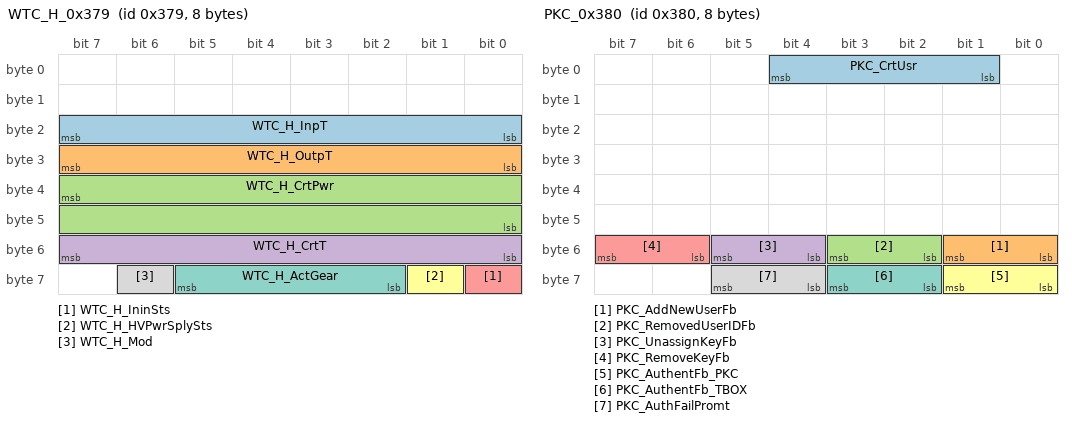
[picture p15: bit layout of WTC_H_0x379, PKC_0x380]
BO_ 889 WTC_H_0x379: 8 GW
 SG_ WTC_H_InpT : 23|8@0+ (1,-48) [-48|207] "Degree Celsius" ICC
 SG_ WTC_H_OutpT : 31|8@0+ (1,-48) [-48|207] "Degree Celsius" ICC
 SG_ WTC_H_CrtPwr : 39|16@0+ (1,0) [0|10000] "" ICC
 SG_ WTC_H_CrtT : 55|8@0+ (1,-48) [-48|207] "Degree Celsius" ICC
 SG_ WTC_H_IninSts : 56|1@0+ (1,0) [0|1] "" ICC
 SG_ WTC_H_HVPwrSplySts : 57|1@0+ (1,0) [0|1] "" ICC
 SG_ WTC_H_ActGear : 61|4@0+ (1,0) [0|15] "" ICC
 SG_ WTC_H_Mod : 62|1@0+ (1,0) [0|1] "" ICC

BO_ 896 PKC_0x380: 8 GW
 SG_ PKC_CrtUsr : 4|4@0+ (1,0) [0|15] "" ICC
 SG_ PKC_AddNewUserFb : 49|2@0+ (1,0) [0|3] "" ICC
 SG_ PKC_RemovedUserIDFb : 51|2@0+ (1,0) [0|3] "" ICC
 SG_ PKC_UnassignKeyFb : 53|2@0+ (1,0) [0|3] "" ICC
 SG_ PKC_RemoveKeyFb : 55|2@0+ (1,0) [0|3] "" ICC
 SG_ PKC_AuthentFb_PKC : 57|2@0+ (1,0) [0|3] "" ICC
 SG_ PKC_AuthentFb_TBOX : 59|2@0+ (1,0) [0|3] "" ICC
 SG_ PKC_AuthFailPromt : 61|2@0+ (1,0) [0|3] "" ICC

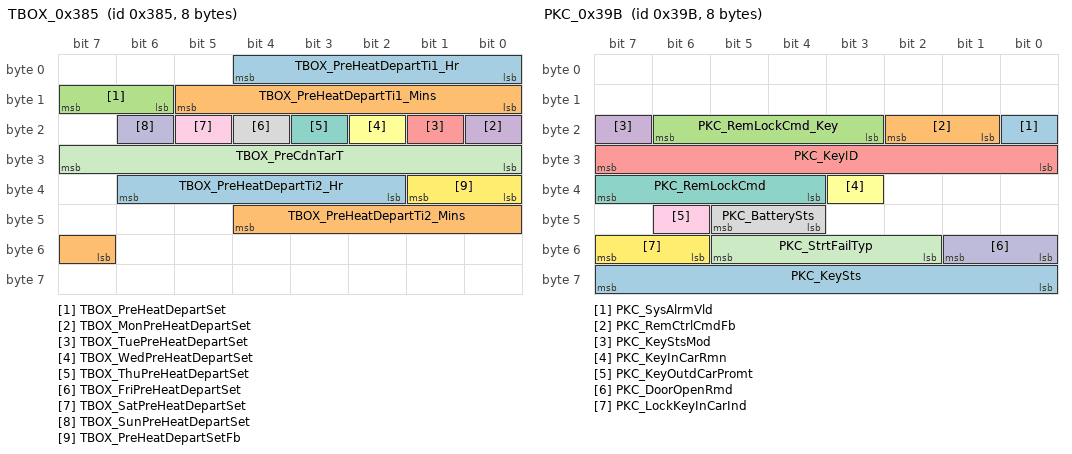
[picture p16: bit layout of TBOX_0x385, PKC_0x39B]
BO_ 901 TBOX_0x385: 8 GW
 SG_ TBOX_PreHeatDepartTi1_Hr : 4|5@0+ (1,0) [0|23] "" ICC
 SG_ TBOX_PreHeatDepartTi1_Mins : 13|6@0+ (1,0) [0|59] "" ICC
 SG_ TBOX_PreHeatDepartSet : 15|2@0+ (1,0) [0|3] "" ICC
 SG_ TBOX_MonPreHeatDepartSet : 16|1@0+ (1,0) [0|1] "" ICC
 SG_ TBOX_TuePreHeatDepartSet : 17|1@0+ (1,0) [0|1] "" ICC
 SG_ TBOX_WedPreHeatDepartSet : 18|1@0+ (1,0) [0|1] "" ICC
 SG_ TBOX_ThuPreHeatDepartSet : 19|1@0+ (1,0) [0|1] "" ICC
 SG_ TBOX_FriPreHeatDepartSet : 20|1@0+ (1,0) [0|1] "" ICC
 SG_ TBOX_SatPreHeatDepartSet : 21|1@0+ (1,0) [0|1] "" ICC
 SG_ TBOX_SunPreHeatDepartSet : 22|1@0+ (1,0) [0|1] "" ICC
 SG_ TBOX_PreCdnTarT : 31|8@0+ (0.5,0) [-48|255] "Degree Celsius" ICC
 SG_ TBOX_PreHeatDepartSetFb : 33|2@0+ (1,0) [0|3] "" ICC
 SG_ TBOX_PreHeatDepartTi2_Hr : 38|5@0+ (1,0) [0|23] "" ICC
 SG_ TBOX_PreHeatDepartTi2_Mins : 44|6@0+ (1,0) [0|59] "" ICC

BO_ 923 PKC_0x39B: 8 GW
 SG_ PKC_SysAlrmVld : 16|1@0+ (1,0) [0|1] "" ICC
 SG_ PKC_RemCtrlCmdFb : 18|2@0+ (1,0) [0|3] "" ICC
 SG_ PKC_RemLockCmd_Key : 22|4@0+ (1,0) [0|15] "" ICC
 SG_ PKC_KeyStsMod : 23|1@0+ (1,0) [0|1] "" ICC
 SG_ PKC_KeyID : 31|8@0+ (1,0) [0|255] "" ICC
 SG_ PKC_KeyInCarRmn : 35|1@0+ (1,0) [0|1] "" ICC
 SG_ PKC_RemLockCmd : 39|4@0+ (1,0) [0|15] "" ICC
 SG_ PKC_BatterySts : 45|2@0+ (1,0) [0|3] "" ICC
 SG_ PKC_KeyOutdCarPromt : 46|1@0+ (1,0) [0|1] "" ICC
 SG_ PKC_DoorOpenRmd : 49|2@0+ (1,0) [0|3] "" ICC
 SG_ PKC_StrtFailTyp : 53|4@0+ (1,0) [0|15] "" ICC
 SG_ PKC_LockKeyInCarInd : 55|2@0+ (1,0) [0|3] "" ICC
 SG_ PKC_KeySts : 63|8@0+ (1,0) [0|255] "" ICC

BO_ 983 PKC_0x3D7: 8 GW
 SG_ PKC_PhoneAdvName2 : 7|64@0+ (1,0) [0|65535] "" ICC

BO_ 984 PKC_0x3D8: 8 GW
 SG_ PKC_PhoneAdvName3 : 7|64@0+ (1,0) [0|65535] "" ICC

BO_ 985 PKC_0x3D9: 8 GW
 SG_ PKC_PhoneAdvName4 : 7|64@0+ (1,0) [0|65535] "" ICC

BO_ 986 PKC_0x3DA: 8 GW
 SG_ PKC_PhoneAdvName5 : 7|64@0+ (1,0) [0|65535] "" ICC

BO_ 987 PKC_0x3DB: 8 GW
 SG_ PKC_PhoneAdvName6 : 7|64@0+ (1,0) [0|65535] "" ICC

BO_ 988 PKC_0x3DC: 8 GW
 SG_ PKC_PhoneAdvName7 : 7|64@0+ (1,0) [0|65535] "" ICC

BO_ 989 PKC_0x3DD: 8 GW
 SG_ PKC_PhoneAdvName8 : 7|64@0+ (1,0) [0|65535] "" ICC

BO_ 1136 EPS_0x470: 8 GW
 SG_ EPS_IninSts : 0|1@0+ (1,0) [0|1] "" ICC
 SG_ EPS_CrtSts : 1|1@0+ (1,0) [0|1] "" ICC
 SG_ EPS_FltIndcn : 2|1@0+ (1,0) [0|1] "" ICC
 SG_ EPS_SteerWhlBackStsFb : 4|2@0+ (1,0) [0|3] "" ICC
 SG_ EPS_AsscRate : 15|8@0+ (1,0) [0|100] "%" ICC
 SG_ EPS_AsscMotCrtPwr : 23|8@0+ (5,0) [0|1200] "W" ICC
 SG_ EPS_TqSnsrSigErr : 34|1@0+ (1,0) [0|1] "" ICC
 SG_ EPS_SteerAgSnsrFlt : 37|1@0+ (1,0) [0|1] "" ICC
 SG_ EPS_TSnsrFlt : 39|1@0+ (1,0) [0|1] "" ICC
 SG_ EPS_ComLostFlt_ESP : 40|1@0+ (1,0) [0|1] "" ICC
 SG_ EPS_SpdDataErr : 41|1@0+ (1,0) [0|1] "" ICC
 SG_ EPS_HwFlt : 43|1@0+ (1,0) [0|1] "" ICC
 SG_ EPS_RlyFlt : 44|1@0+ (1,0) [0|1] "" ICC
 SG_ EPS_MotPosnSnsrFlt : 45|1@0+ (1,0) [0|1] "" ICC
 SG_ EPS_SteerAgSnsrNotCalFlt : 46|1@0+ (1,0) [0|1] "" ICC
 SG_ EPS_MotCrtFlt : 47|1@0+ (1,0) [0|1] "" ICC
 SG_ EPS_AsscMotCrt : 55|16@0+ (0.01,-150) [-150|150] "A" ICC

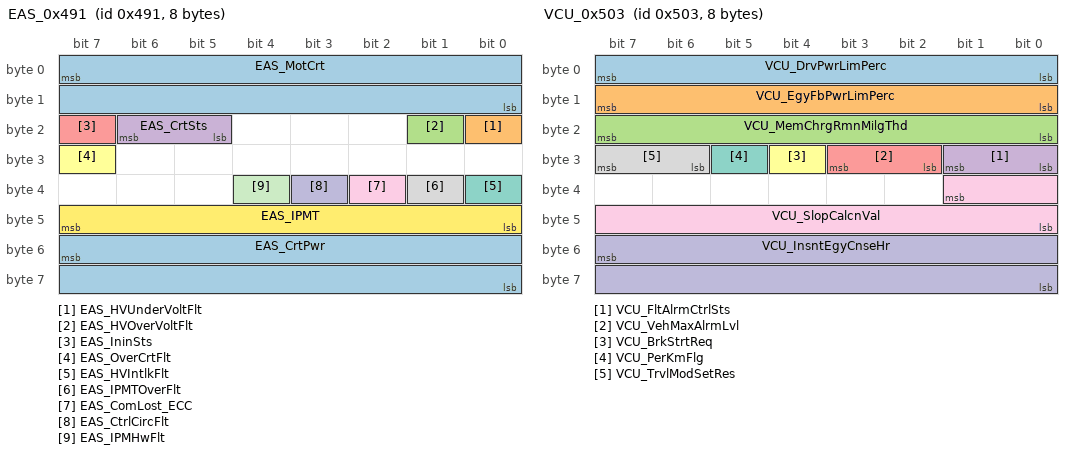
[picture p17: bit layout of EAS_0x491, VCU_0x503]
BO_ 1169 EAS_0x491: 8 GW
 SG_ EAS_MotCrt : 7|16@0+ (0.02,0) [0|1310.7] "A" ICC
 SG_ EAS_HVUnderVoltFlt : 16|1@0+ (1,0) [0|1] "" ICC
 SG_ EAS_HVOverVoltFlt : 17|1@0+ (1,0) [0|1] "" ICC
 SG_ EAS_CrtSts : 22|2@0+ (1,0) [0|3] "" ICC
 SG_ EAS_IninSts : 23|1@0+ (1,0) [0|1] "" ICC
 SG_ EAS_OverCrtFlt : 31|1@0+ (1,0) [0|1] "" ICC
 SG_ EAS_HVIntlkFlt : 32|1@0+ (1,0) [0|1] "" ICC
 SG_ EAS_IPMTOverFlt : 33|1@0+ (1,0) [0|1] "" ICC
 SG_ EAS_ComLost_ECC : 34|1@0+ (1,0) [0|1] "" ICC
 SG_ EAS_CtrlCircFlt : 35|1@0+ (1,0) [0|1] "" ICC
 SG_ EAS_IPMHwFlt : 36|1@0+ (1,0) [0|1] "" ICC
 SG_ EAS_IPMT : 47|8@0+ (1,-48) [-48|207] "Degree Celsius" ICC
 SG_ EAS_CrtPwr : 55|16@0+ (0.2,0) [0|13107] "W" ICC

BO_ 1283 VCU_0x503: 8 GW
 SG_ VCU_DrvPwrLimPerc : 7|8@0+ (0.8,-100) [-100|100] "%" ICC
 SG_ VCU_EgyFbPwrLimPerc : 15|8@0+ (0.8,-100) [-100|100] "%" ICC
 SG_ VCU_MemChrgRmnMilgThd : 23|8@0+ (1,0) [0|255] "km" ICC
 SG_ VCU_FltAlrmCtrlSts : 25|2@0+ (1,0) [0|3] "" ICC
 SG_ VCU_VehMaxAlrmLvl : 27|2@0+ (1,0) [0|3] "" ICC
 SG_ VCU_BrkStrtReq : 28|1@0+ (1,0) [0|1] "" ICC
 SG_ VCU_PerKmFlg : 29|1@0+ (1,0) [0|1] "" ICC
 SG_ VCU_TrvlModSetRes : 31|2@0+ (1,0) [0|3] "" ICC
 SG_ VCU_SlopCalcnVal : 33|10@0+ (0.2713,-100) [-100|100] "" ICC
 SG_ VCU_InsntEgyCnseHr : 55|16@0+ (0.01,-100) [-100|100] "kWh/h" ICC

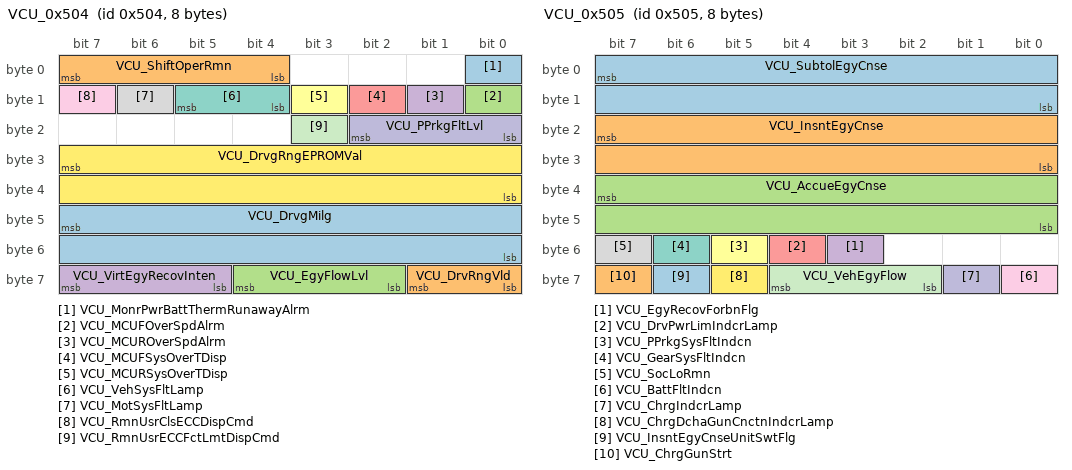
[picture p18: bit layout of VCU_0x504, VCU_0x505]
BO_ 1284 VCU_0x504: 8 GW
 SG_ VCU_MonrPwrBattThermRunawayAlrm : 0|1@0+ (1,0) [0|1] "" ICC
 SG_ VCU_ShiftOperRmn : 7|4@0+ (1,0) [0|15] "" ICC
 SG_ VCU_MCUFOverSpdAlrm : 8|1@0+ (1,0) [0|1] "" ICC
 SG_ VCU_MCUROverSpdAlrm : 9|1@0+ (1,0) [0|1] "" ICC
 SG_ VCU_MCUFSysOverTDisp : 10|1@0+ (1,0) [0|1] "" ICC
 SG_ VCU_MCURSysOverTDisp : 11|1@0+ (1,0) [0|1] "" ICC
 SG_ VCU_VehSysFltLamp : 13|2@0+ (1,0) [0|3] "" ICC
 SG_ VCU_MotSysFltLamp : 14|1@0+ (1,0) [0|1] "" ICC
 SG_ VCU_RmnUsrClsECCDispCmd : 15|1@0+ (1,0) [0|1] "" ICC
 SG_ VCU_PPrkgFltLvl : 18|3@0+ (1,0) [0|7] "" ICC
 SG_ VCU_RmnUsrECCFctLmtDispCmd : 19|1@0+ (1,0) [0|1] "" ICC
 SG_ VCU_DrvgRngEPROMVal : 31|16@0+ (0.1,0) [0|6553.5] "km" ICC
 SG_ VCU_DrvgMilg : 47|16@0+ (0.1,0) [0|6553.5] "km" ICC
 SG_ VCU_DrvRngVld : 57|2@0+ (1,0) [0|3] "" ICC
 SG_ VCU_EgyFlowLvl : 60|3@0+ (1,-3) [-3|3] "" ICC
 SG_ VCU_VirtEgyRecovInten : 63|3@0+ (1,0) [0|7] "" ICC

BO_ 1285 VCU_0x505: 8 GW
 SG_ VCU_SubtolEgyCnse : 7|16@0+ (0.01,0) [0|655.35] "kWh/100km" ICC
 SG_ VCU_InsntEgyCnse : 23|16@0+ (0.01,-100) [-100|100] "kWh/100km" ICC
 SG_ VCU_AccueEgyCnse : 39|16@0+ (0.01,0) [0|655.35] "kWh/100km" ICC
 SG_ VCU_EgyRecovForbnFlg : 51|1@0+ (1,0) [0|1] "" ICC
 SG_ VCU_DrvPwrLimIndcrLamp : 52|1@0+ (1,0) [0|1] "" ICC
 SG_ VCU_PPrkgSysFltIndcn : 53|1@0+ (1,0) [0|1] "" ICC
 SG_ VCU_GearSysFltIndcn : 54|1@0+ (1,0) [0|1] "" ICC
 SG_ VCU_SocLoRmn : 55|1@0+ (1,0) [0|1] "" ICC
 SG_ VCU_BattFltIndcn : 56|1@0+ (1,0) [0|1] "" ICC
 SG_ VCU_ChrgIndcrLamp : 57|1@0+ (1,0) [0|1] "" ICC
 SG_ VCU_VehEgyFlow : 60|3@0+ (1,0) [0|7] "" ICC
 SG_ VCU_ChrgDchaGunCnctnIndcrLamp : 61|1@0+ (1,0) [0|1] "" ICC
 SG_ VCU_InsntEgyCnseUnitSwtFlg : 62|1@0+ (1,0) [0|1] "" ICC
 SG_ VCU_ChrgGunStrt : 63|1@0+ (1,0) [0|1] "" ICC

BO_ 1292 VCU_0x50C: 8 GW
 SG_ VCU_DrvMotOutpPwrPerc : 7|8@0+ (0.8,-100) [-100|100] "" ICC
 SG_ VCU_APS2Volt : 15|8@0+ (0.02,0) [0|5] "V" ICC
 SG_ VCU_APS1Volt : 23|8@0+ (0.02,0) [0|5] "V" ICC
 SG_ VCU_SlipRate : 31|12@0+ (0.5,-1000) [-1000|1000] "" ICC
 SG_ VCU_DrvTqLimSts : 35|9@0+ (1,0) [0|511] "" ICC
 SG_ VCU_EgyRecovTqLimSts : 41|10@0+ (1,0) [0|1023] "" ICC

BO_ 1297 VCU_0x511: 8 GW
 SG_ VCU_BMSLVWakeUpSts : 0|1@0+ (1,0) [0|1] "" ICC
 SG_ VCU_ONWakeUpSig : 1|1@0+ (1,0) [0|1] "" ICC
 SG_ VCU_FCWakeUpSig : 2|1@0+ (1,0) [0|1] "" ICC
 SG_ VCU_SCWakeUpSig : 3|1@0+ (1,0) [0|1] "" ICC
 SG_ VCU_RemWakeUpSig : 4|1@0+ (1,0) [0|1] "" ICC
 SG_ VCU_NetWakeUpSig : 5|1@0+ (1,0) [0|1] "" ICC
 SG_ VCU_LVWakeUpSts_PDU : 6|1@0+ (1,0) [0|1] "" ICC
 SG_ VCU_VehEOLFctFlg : 7|1@0+ (1,0) [0|1] "" ICC
 SG_ VCU_LVWakeUpSts_MCU : 8|1@0+ (1,0) [0|1] "" ICC
 SG_ VCU_PwrAntithefAllwtRdyFlg : 9|1@0+ (1,0) [0|1] "" ICC
 SG_ VCU_LVWakeUpSts_CCU : 10|1@0+ (1,0) [0|1] "" ICC
 SG_ VCU_RemECCEndCmd : 11|1@0+ (1,0) [0|1] "" ICC
 SG_ VCU_EvChrgElectcLockCtrlCmd : 13|2@0+ (1,0) [0|3] "" ICC
 SG_ VCU_RemPwrBattHeatgEndCmd : 14|1@0+ (1,0) [0|1] "" ICC
 SG_ VCU_RemChrgEndCmd : 15|1@0+ (1,0) [0|1] "" ICC
 SG_ VCU_V2L_TrAvl : 16|1@0+ (1,0) [0|1] "" ICC
 SG_ VCU_RemBattHeatgFailReason : 19|3@0+ (1,0) [0|7] "" ICC
 SG_ VCU_RemECCEndReason : 22|3@0+ (1,0) [0|7] "" ICC
 SG_ VCU_V2L_ChrgPortAvl : 23|1@0+ (1,0) [0|1] "" ICC
 SG_ VCU_RemChrgEndReason : 26|3@0+ (1,0) [0|7] "" ICC
 SG_ VCU_SchedChrgnStsFb : 28|2@0+ (1,0) [0|3] "" ICC
 SG_ VCU_V2V_Avl : 29|1@0+ (1,0) [0|1] "" ICC
 SG_ VCU_V2H_Avl : 30|1@0+ (1,0) [0|1] "" ICC
 SG_ VCU_V2G_Avl : 31|1@0+ (1,0) [0|1] "" ICC
 SG_ VCU_VehMod : 39|4@0+ (1,0) [0|15] "" ICC
 SG_ VCU_VehCrtChrgEndSOC : 46|7@0+ (1,0) [0|100] "%" ICC
 SG_ VCU_CalSwVers : 52|5@0+ (1,0) [0|31] "" ICC
 SG_ VCU_RemPwrBattPreheatgEndFlg : 53|1@0+ (1,0) [0|1] "" ICC
 SG_ VCU_VehOperMod : 60|5@0+ (1,0) [0|31] "" ICC
 SG_ VCU_VehRemRefrshModReq : 62|2@0+ (1,0) [0|3] "" ICC
 SG_ VCU_RemDTCPwrOnReq : 63|1@0+ (1,0) [0|1] "" ICC

BO_ 1312 DCDC_0x520: 8 GW
 SG_ DCDC_0x520_CheckSum : 7|8@0+ (1,0) [0|255] "" ICC
 SG_ DCDC_0x520_AliveCounter : 11|4@0+ (1,0) [0|14] "" ICC
 SG_ DCDC_OutpCrt : 23|16@0+ (0.01,0) [0|300] "A" ICC
 SG_ DCDC_InpVolt : 39|16@0+ (0.02,0) [0|1310.7] "V" ICC
 SG_ DCDC_InpCrt : 55|8@0+ (0.1,0) [0|25.5] "A" ICC
 SG_ DCDC_OutpVolt : 63|8@0+ (0.1,0) [0|25.5] "V" ICC

BO_ 1317 TBOX_0x525: 8 GW
 SG_ TBOX_525_CheckSum : 7|8@0+ (1,0) [0|255] "" ICC
 SG_ TBOX_525_AliveCounter : 11|4@0+ (1,0) [0|14] "" ICC
 SG_ TBOX_GPSHei : 23|17@0+ (0.1,-500) [-500|8000] "m" ICC

BO_ 1318 TBOX_0x526: 8 GW
 SG_ TBOX_GPSLongi : 7|32@0+ (1e-06,-180) [-180|180] "deg" ICC
 SG_ TBOX_GPSLati : 39|32@0+ (1e-06,-90) [-90|90] "deg" ICC

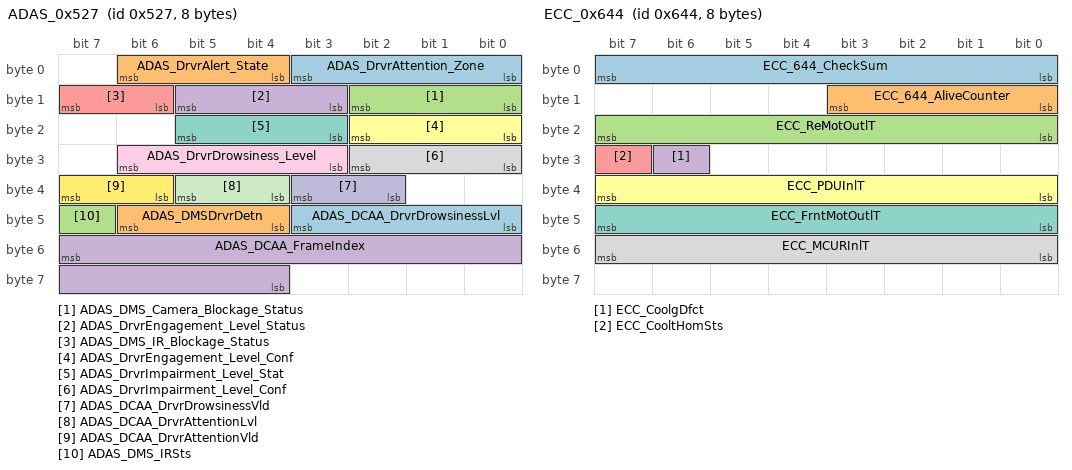
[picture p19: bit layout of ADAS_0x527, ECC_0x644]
BO_ 1319 ADAS_0x527: 8 ADAS
 SG_ ADAS_DrvrAttention_Zone : 3|4@0+ (1,0) [0|15] "" ICC
 SG_ ADAS_DrvrAlert_State : 6|3@0+ (1,0) [0|7] "" ICC
 SG_ ADAS_DMS_Camera_Blockage_Status : 10|3@0+ (1,0) [0|7] "" ICC
 SG_ ADAS_DrvrEngagement_Level_Status : 13|3@0+ (1,0) [0|7] "" ICC
 SG_ ADAS_DMS_IR_Blockage_Status : 15|2@0+ (1,0) [0|3] "" ICC
 SG_ ADAS_DrvrEngagement_Level_Conf : 18|3@0+ (1,0) [0|7] "" ICC
 SG_ ADAS_DrvrImpairment_Level_Stat : 21|3@0+ (1,0) [0|7] "" ICC
 SG_ ADAS_DrvrImpairment_Level_Conf : 26|3@0+ (1,0) [0|7] "" ICC
 SG_ ADAS_DrvrDrowsiness_Level : 30|4@0+ (1,0) [0|15] "" ICC
 SG_ ADAS_DCAA_DrvrDrowsinessVld : 35|2@0+ (1,0) [0|3] "" ICC
 SG_ ADAS_DCAA_DrvrAttentionLvl : 37|2@0+ (1,0) [0|3] "" ICC
 SG_ ADAS_DCAA_DrvrAttentionVld : 39|2@0+ (1,0) [0|3] "" ICC
 SG_ ADAS_DCAA_DrvrDrowsinessLvl : 43|4@0+ (1,0) [0|15] "" ICC
 SG_ ADAS_DMSDrvrDetn : 46|3@0+ (1,0) [0|7] "" ICC
 SG_ ADAS_DMS_IRSts : 47|1@0+ (1,0) [0|1] "" ICC
 SG_ ADAS_DCAA_FrameIndex : 55|12@0+ (1,0) [0|4095] "" ICC

BO_ 1322 ICC_0x52A: 8 ICC
 SG_ ICC_0x52A_CheckSum : 7|8@0+ (1,0) [0|255] "" ICC
 SG_ ICC_0x52A_AliveCounter : 11|4@0+ (1,0) [0|14] "" ICC
 SG_ ICC_FACM_DynmcSenstvty : 12|1@0+ (1,0) [0|1] "" ICC
 SG_ ICC_UsrProfTiGapSet : 15|3@0+ (1,0) [0|7] "" ICC
 SG_ ICC_LKA_Setting : 17|2@0+ (1,0) [0|3] "" ICC
 SG_ ICC_FACM_Setting : 19|2@0+ (1,0) [0|3] "" ICC
 SG_ ICC_AEB_Sensitivity : 21|2@0+ (1,0) [0|3] "" ICC
 SG_ ICC_BACM_Setting : 23|2@0+ (1,0) [0|3] "" ICC
 SG_ ICC_BACM_Sensitivity : 25|2@0+ (1,0) [0|3] "" ICC
 SG_ ICC_AEB_JerkSetReq : 27|2@0+ (1,0) [0|3] "" ICC
 SG_ ICC_ActvStyGlblSetting : 28|1@0+ (1,0) [0|1] "" ICC
 SG_ ICC_TSR_Setting : 29|1@0+ (1,0) [0|1] "" ICC
 SG_ ICC_ESA_Setting : 30|1@0+ (1,0) [0|1] "" ICC
 SG_ ICC_ELKASteeringInterventionSet : 31|1@0+ (1,0) [0|1] "" ICC
 SG_ ICC_LaneTrajectorySetting : 32|1@0+ (1,0) [0|1] "" ICC
 SG_ ICC_ACCSwt : 34|2@0+ (1,0) [0|3] "" ICC
 SG_ ICC_ACCAutoSpdSts : 35|1@0+ (1,0) [0|1] "" ICC
 SG_ ICC_ACCSpdStepSize : 36|1@0+ (1,0) [0|1] "" ICC
 SG_ ICC_ACCFuncTyp : 39|3@0+ (1,0) [0|7] "" ICC
 SG_ ICC_ACCSpdLimOffs : 45|6@0+ (0.5,0) [0|31.5] "" ICC
 SG_ ICC_ACCSpdLimOffsTyp : 47|2@0+ (1,0) [0|3] "" ICC
 SG_ ICC_ACCTerrainSetting : 48|1@0+ (1,0) [0|1] "" ICC
 SG_ ICC_ACCTiGapCfm : 51|2@0+ (1,0) [0|3] "" ICC
 SG_ ICC_ISASetting : 54|3@0+ (1,0) [0|7] "" ICC
 SG_ ICC_FCTA_Sensitivity : 57|2@0+ (1,0) [0|3] "" ICC
 SG_ ICC_ISAWarnStopReq : 58|1@0+ (1,0) [0|1] "" ICC
 SG_ ICC_TLR_Setting : 61|3@0+ (1,0) [0|7] "" ICC
 SG_ ICC_FCTA_Setting : 63|2@0+ (1,0) [0|3] "" ICC

BO_ 1337 BCM_0x539: 8 GW
 SG_ BCM_539_CheckSum : 7|8@0+ (1,0) [0|255] "" ICC
 SG_ BCM_539_AliveCounter : 11|4@0+ (1,0) [0|14] "" ICC
 SG_ BCM_LePosnLampFlt : 16|1@0+ (1,0) [0|1] "" ICC
 SG_ BCM_RiPosnLampFlt : 17|1@0+ (1,0) [0|1] "" ICC
 SG_ BCM_LeLoBeamFlt : 18|1@0+ (1,0) [0|1] "" ICC
 SG_ BCM_RiLoBeamFlt : 19|1@0+ (1,0) [0|1] "" ICC
 SG_ BCM_LeHiBeamFlt : 20|1@0+ (1,0) [0|1] "" ICC
 SG_ BCM_RiHiBeamFlt : 21|1@0+ (1,0) [0|1] "" ICC
 SG_ BCM_LeDRLFlt : 22|1@0+ (1,0) [0|1] "" ICC
 SG_ BCM_RiDRLFlt : 23|1@0+ (1,0) [0|1] "" ICC
 SG_ BCM_LeFrntFogLampFlt : 24|1@0+ (1,0) [0|1] "" ICC
 SG_ BCM_RiFrntFogLampFlt : 25|1@0+ (1,0) [0|1] "" ICC
 SG_ BCM_ReFogLampFlt : 26|1@0+ (1,0) [0|1] "" ICC
 SG_ BCM_LoBrkLampFlt : 28|1@0+ (1,0) [0|1] "" ICC
 SG_ BCM_HiBrkLampFlt : 29|1@0+ (1,0) [0|1] "" ICC
 SG_ BCM_RvsLampFlt : 30|1@0+ (1,0) [0|1] "" ICC
 SG_ BCM_LeTurnLampFlt : 32|1@0+ (1,0) [0|1] "" ICC
 SG_ BCM_RiTurnLampFlt : 33|1@0+ (1,0) [0|1] "" ICC
 SG_ BCM_LicPlateLampFlt : 34|1@0+ (1,0) [0|1] "" ICC
 SG_ BCM_ElWiperMotorFlt : 36|2@0+ (1,0) [0|3] "" ICC
 SG_ BCM_No_key_found_warning : 38|2@0+ (1,0) [0|1] "" ICC

BO_ 1408 VCU_0x580: 8 GW
 SG_ VCU_ActChrgTotAh : 7|16@0+ (0.01,0) [0|655.35] "Ah" ICC
 SG_ VCU_ActDchgTotAh : 23|16@0+ (0.01,0) [0|655.35] "Ah" ICC
 SG_ VCU_DCChrgRmngTi : 39|16@0+ (1,0) [0|65535] "min" ICC
 SG_ VCU_PwrBattAvlEgy : 55|16@0+ (0.01,0) [0|655.35] "kWh" ICC

BO_ 1410 ECC_0x582: 8 GW
 SG_ ECC_InsdT : 7|8@0+ (0.5,-48) [-48|79.5] "Degree Celsius" ICC
 SG_ ECC_RemPwrCnsEstim : 15|8@0+ (0.05,0) [0|12.75] "kWh" ICC
 SG_ ECC_RemTSetSts : 23|8@0+ (1,0) [0|255] "" ICC
 SG_ ECC_RemDefrstSts : 24|1@0+ (1,0) [0|1] "" ICC
 SG_ ECC_BattFldLvlSnsrLamp : 26|2@0+ (1,0) [0|3] "" ICC
 SG_ ECC_ResvOperTi : 39|8@0+ (1,0) [0|255] "min" ICC
 SG_ ECC_ParticleConc : 49|10@0+ (1,0) [0|999] "ug/m3" ICC

BO_ 1419 VCU_0x58B: 8 GW
 SG_ VCU_HVEgyCnsMovg : 7|15@0+ (1,-9999) [-9999|9999] "Wh/km" ICC
 SG_ VCU_HVEgyCnsStandstill : 23|15@0+ (1,-2000) [-2000|20000] "Wh" ICC
 SG_ VCU_HVEgyCnsAverage : 39|15@0+ (1,-9999) [-9999|9999] "Wh/km" ICC
 SG_ VCU_HVCustSOC : 55|7@0+ (1,0) [0|100] "%" ICC

BO_ 1422 VCU_0x58E: 8 GW
 SG_ VCU_EgyCnsHist01 : 7|15@0+ (1,-9999) [-9999|9999] "Wh/km" ICC
 SG_ VCU_EgyCnsHist02 : 23|15@0+ (1,-9999) [-9999|9999] "Wh/km" ICC
 SG_ VCU_EgyCnsHist03 : 39|15@0+ (1,-9999) [-9999|9999] "Wh/km" ICC
 SG_ VCU_EgyCnsHist04 : 55|15@0+ (1,-9999) [-9999|9999] "Wh/km" ICC

BO_ 1425 VCU_0x591: 8 GW
 SG_ VCU_EgyCnsHist05 : 7|15@0+ (1,-9999) [-9999|9999] "Wh/km" ICC
 SG_ VCU_EgyCnsHist06 : 23|15@0+ (1,-9999) [-9999|9999] "Wh/km" ICC
 SG_ VCU_EgyCnsHist07 : 39|15@0+ (1,-9999) [-9999|9999] "Wh/km" ICC
 SG_ VCU_EgyCnsHist08 : 55|15@0+ (1,-9999) [-9999|9999] "Wh/km" ICC

BO_ 1432 VCU_0x598: 8 GW
 SG_ VCU_EgyCnsHist09 : 7|15@0+ (1,-9999) [-9999|9999] "Wh/km" ICC
 SG_ VCU_EgyCnsHist10 : 23|15@0+ (1,-9999) [-9999|9999] "Wh/km" ICC

BO_ 1436 VCU_0x59C: 8 GW
 SG_ VCU_LowMilg_Warn : 25|2@0+ (1,0) [0|3] "" ICC
 SG_ VCU_LowMilgRemAlrm : 27|2@0+ (1,0) [0|3] "" ICC
 SG_ VCU_MilgChrg_add : 23|10@0+ (1,0) [0|1000] "km" ICC
 SG_ VCU_MilgChrgRate_add : 39|15@0+ (0.1,0) [0|2000] "km/h" ICC

BO_ 1444 VCU_0x5A4: 8 GW
 SG_ VCU_HVEM_PwrCoorrPrio : 13|2@0+ (1,0) [0|3] "" ICC
 SG_ VCU_ChrgPwrLim : 23|7@0+ (1,0) [0|100] "%" ICC
 SG_ VCU_P_ECC_unfiltered : 31|8@0+ (0.1,0) [0|15] "KW" ICC
 SG_ VCU_P_Prop_filt : 33|26@0+ (0.1,-450) [-450|450] "KW" ICC

BO_ 1554 ICC_0x612: 8 ICC
 SG_ ICC_NavGuidanceInfo : 7|8@0+ (1,0) [0|255] "" ICC
 SG_ ICC_NavDstInfo : 11|20@0+ (1,0) [0|1.04858e+06] "" ICC

BO_ 1555 ICC_0x613: 8 ICC
 SG_ ICC_ResvTrvlStrtSet : 31|2@0+ (1,0) [0|3] "" ICC

BO_ 1556 ICC_0x614: 8 ICC
 SG_ ICC_ResvACChrgStrtTi_Hr : 4|5@0+ (1,0) [0|23] "" ICC
 SG_ ICC_ResvACChrgStrtTi_Mins : 13|6@0+ (1,0) [0|59] "" ICC
 SG_ ICC_ResvACChrgStrtSet : 15|2@0+ (1,0) [0|3] "" ICC
 SG_ ICC_MonResvACChrgRepStrtSet : 16|1@0+ (1,0) [0|1] "" ICC
 SG_ ICC_TueResvACChrgRepStrtSet : 17|1@0+ (1,0) [0|1] "" ICC
 SG_ ICC_WedResvACChrgRepStrtSet : 18|1@0+ (1,0) [0|1] "" ICC
 SG_ ICC_ThuResvACChrgRepStrtSet : 19|1@0+ (1,0) [0|1] "" ICC
 SG_ ICC_FriResvACChrgRepStrtSet : 20|1@0+ (1,0) [0|1] "" ICC
 SG_ ICC_SatResvACChrgRepStrtSet : 21|1@0+ (1,0) [0|1] "" ICC
 SG_ ICC_SunResvACChrgRepStrtSet : 22|1@0+ (1,0) [0|1] "" ICC
 SG_ ICC_ResvACChrgEndTi_Hr : 28|5@0+ (1,0) [0|23] "" ICC
 SG_ ICC_ResvACChrgEndTi_Mins : 37|6@0+ (1,0) [0|59] "" ICC
 SG_ ICC_ResvACChrgEndSet : 39|2@0+ (1,0) [0|3] "" ICC
 SG_ ICC_MonResvACChrgRepEndSet : 40|1@0+ (1,0) [0|1] "" ICC
 SG_ ICC_TueResvACChrgRepEndSet : 41|1@0+ (1,0) [0|1] "" ICC
 SG_ ICC_WedResvACChrgRepEndSet : 42|1@0+ (1,0) [0|1] "" ICC
 SG_ ICC_ThuResvACChrgRepEndSet : 43|1@0+ (1,0) [0|1] "" ICC
 SG_ ICC_FriResvACChrgRepEndSet : 44|1@0+ (1,0) [0|1] "" ICC
 SG_ ICC_SatResvACChrgRepEndSet : 45|1@0+ (1,0) [0|1] "" ICC
 SG_ ICC_SunResvACChrgRepEndSet : 46|1@0+ (1,0) [0|1] "" ICC

BO_ 1581 TBOX_0x62D: 8 GW
 SG_ TBOX_ICC_FlashPct : 8|7@0+ (1,0) [0|100] "%" ICC
 SG_ TBOX_ResvTrvlStrtSts : 31|2@0+ (1,0) [0|3] "" ICC

BO_ 1582 TBOX_0x62E: 8 GW
 SG_ TBOX_ResvACChrgStrtTi_Hr : 4|5@0+ (1,0) [0|23] "" ICC
 SG_ TBOX_ResvACChrgStrtTi_Mins : 13|6@0+ (1,0) [0|59] "" ICC
 SG_ TBOX_MonResvACChrgRepStrtSet : 16|1@0+ (1,0) [0|1] "" ICC
 SG_ TBOX_TueResvACChrgRepStrtSet : 17|1@0+ (1,0) [0|1] "" ICC
 SG_ TBOX_WedResvACChrgRepStrtSet : 18|1@0+ (1,0) [0|1] "" ICC
 SG_ TBOX_ThuResvACChrgRepStrtSet : 19|1@0+ (1,0) [0|1] "" ICC
 SG_ TBOX_FriResvACChrgRepStrtSet : 20|1@0+ (1,0) [0|1] "" ICC
 SG_ TBOX_SatResvACChrgRepStrtSet : 21|1@0+ (1,0) [0|1] "" ICC
 SG_ TBOX_SunResvACChrgRepStrtSet : 22|1@0+ (1,0) [0|1] "" ICC
 SG_ TBOX_ResvACChrgEndTi_Hr : 28|5@0+ (1,0) [0|23] "" ICC
 SG_ TBOX_ResvACChrgEndTi_Mins : 37|6@0+ (1,0) [0|59] "" ICC
 SG_ TBOX_ResvACChrgEndSet : 39|2@0+ (1,0) [0|3] "" ICC
 SG_ TBOX_MonResvACChrgRepEndSet : 40|1@0+ (1,0) [0|1] "" ICC
 SG_ TBOX_TueResvACChrgRepEndSet : 41|1@0+ (1,0) [0|1] "" ICC
 SG_ TBOX_WedResvACChrgRepEndSet : 42|1@0+ (1,0) [0|1] "" ICC
 SG_ TBOX_ThuResvACChrgRepEndSet : 43|1@0+ (1,0) [0|1] "" ICC
 SG_ TBOX_FriResvACChrgRepEndSet : 44|1@0+ (1,0) [0|1] "" ICC
 SG_ TBOX_SatResvACChrgRepEndSet : 45|1@0+ (1,0) [0|1] "" ICC
 SG_ TBOX_SunResvACChrgRepEndSet : 46|1@0+ (1,0) [0|1] "" ICC

BO_ 1584 VCU_0x630: 8 GW
 SG_ VCU_CellTotVolt : 7|16@0+ (0.02,0) [0|1310.7] "V" ICC
 SG_ VCU_CellMinVolt : 23|16@0+ (0.0001,0) [0|6.5535] "V" ICC
 SG_ VCU_CellMaxVolt : 39|16@0+ (0.0001,0) [0|6.5535] "V" ICC
 SG_ VCU_ACRmngChrgTi : 55|16@0+ (1,0) [0|65535] "min" ICC

BO_ 1588 VCU_0x634: 8 GW
 SG_ VCU_ACChrgShttrSts : 16|1@0+ (1,0) [0|1] "" ICC
 SG_ VCU_DCChrgShttrSts : 17|1@0+ (1,0) [0|1] "" ICC
 SG_ VCU_SCPwrSplyEquipFactry : 20|3@0+ (1,0) [0|7] "" ICC
 SG_ VCU_ACChrgCrtUpprLmt : 30|7@0+ (1,0) [0|100] "" ICC

BO_ 1601 BCM_0x641: 8 GW
 SG_ BCM_MilgDataVld_ODO : 8|1@0+ (1,0) [0|1] "" ICC
 SG_ BCM_MilgRstCntr_ODO : 10|2@0+ (1,0) [0|3] "" ICC
 SG_ BCM_TotMilg_ODO : 23|32@0+ (0.01,0) [0|2e+06] "km" ICC
 SG_ BCM_MilgOffs_ODO : 55|8@0+ (1,0) [0|255] "km" ICC

BO_ 1604 ECC_0x644: 8 GW
 SG_ ECC_644_CheckSum : 7|8@0+ (1,0) [0|255] "" ICC
 SG_ ECC_644_AliveCounter : 11|4@0+ (1,0) [0|14] "" ICC
 SG_ ECC_ReMotOutlT : 23|8@0+ (1,-48) [-48|207] "Degree Celsius" ICC
 SG_ ECC_CoolgDfct : 30|1@0+ (1,0) [0|1] "" ICC
 SG_ ECC_CooltHomSts : 31|1@0+ (1,0) [0|1] "" ICC
 SG_ ECC_PDUInlT : 39|8@0+ (1,-48) [-48|207] "Degree Celsius" ICC
 SG_ ECC_FrntMotOutlT : 47|8@0+ (1,-48) [-48|207] "Degree Celsius" ICC
 SG_ ECC_MCURInlT : 55|8@0+ (1,-48) [-48|207] "Degree Celsius" ICC

BO_ 1605 ECC_0x645: 8 GW
 SG_ ECC_DefrstAirOutlTSnsrFlt : 16|1@0+ (1,0) [0|1] "" ICC
 SG_ ECC_ComLost_EAS : 17|1@0+ (1,0) [0|1] "" ICC
 SG_ ECC_OutdTSnsrFlt : 18|1@0+ (1,0) [0|1] "" ICC
 SG_ ECC_InsdTSnsrFlt : 19|1@0+ (1,0) [0|1] "" ICC
 SG_ ECC_EvaprTSnsrFlt : 20|1@0+ (1,0) [0|1] "" ICC
 SG_ ECC_IntExtCircMotFlt : 21|1@0+ (1,0) [0|1] "" ICC
 SG_ ECC_LeModThrMotFlt : 22|1@0+ (1,0) [0|1] "" ICC
 SG_ ECC_RiModThrMotFlt : 23|1@0+ (1,0) [0|1] "" ICC
 SG_ ECC_CtrlrFlt : 24|1@0+ (1,0) [0|1] "" ICC
 SG_ ECC_PDUInlTSnsrFlt : 25|1@0+ (1,0) [0|1] "" ICC
 SG_ ECC_FrntMotOutlTSnsrFlt : 26|1@0+ (1,0) [0|1] "" ICC
 SG_ ECC_ReMotOutlTSnsrFlt : 27|1@0+ (1,0) [0|1] "" ICC
 SG_ ECC_ComLost_CDS : 28|1@0+ (1,0) [0|1] "" ICC
 SG_ ECC_ComLost_WTC_H : 30|1@0+ (1,0) [0|1] "" ICC
 SG_ ECC_ComLost_WTC_B : 31|1@0+ (1,0) [0|1] "" ICC
 SG_ ECC_HPTSnsrFlt : 34|1@0+ (1,0) [0|1] "" ICC
 SG_ ECC_LPTSnsrFlt : 35|1@0+ (1,0) [0|1] "" ICC
 SG_ ECC_BlowFaceLeAirOutlTSnsrFlt : 36|1@0+ (1,0) [0|1] "" ICC
 SG_ ECC_BlowFaceRiAirOutlTSnsrFlt : 37|1@0+ (1,0) [0|1] "" ICC
 SG_ ECC_ReBlowFaceFootMotFlt : 38|1@0+ (1,0) [0|1] "" ICC
 SG_ ECC_HPSnsrFlt : 39|1@0+ (1,0) [0|1] "" ICC
 SG_ ECC_LPSnsrFlt : 40|1@0+ (1,0) [0|1] "" ICC
 SG_ ECC_HeatPmpHeatgEXVFlt : 41|1@0+ (1,0) [0|1] "" ICC
 SG_ ECC_BattCoolgEXVFlt : 42|1@0+ (1,0) [0|1] "" ICC
 SG_ ECC_BlowFootLeAirOutlTSnsrFlt : 43|1@0+ (1,0) [0|1] "" ICC
 SG_ ECC_BlowFootRiAirOutlTSnsrFlt : 44|1@0+ (1,0) [0|1] "" ICC
 SG_ ECC_LeHybThrMotFlt : 45|1@0+ (1,0) [0|1] "" ICC
 SG_ ECC_RiHybThrMotFlt : 46|1@0+ (1,0) [0|1] "" ICC
 SG_ ECC_MCURInlTSnsrFlt : 47|1@0+ (1,0) [0|1] "" ICC
 SG_ ECC_ComLost_EWP_FD : 48|1@0+ (1,0) [0|1] "" ICC
 SG_ ECC_ComLost_EWP_RD : 49|1@0+ (1,0) [0|1] "" ICC
 SG_ ECC_ComLost_EWP_H : 50|1@0+ (1,0) [0|1] "" ICC
 SG_ ECC_ComLost_EWP_B : 51|1@0+ (1,0) [0|1] "" ICC
 SG_ ECC_ComLost_EXV_B : 52|1@0+ (1,0) [0|1] "" ICC
 SG_ ECC_ComLost_EXV_H : 53|1@0+ (1,0) [0|1] "" ICC
 SG_ ECC_ComLost_CFM : 54|1@0+ (1,0) [0|1] "" ICC
 SG_ ECC_ComLost_AGS : 55|1@0+ (1,0) [0|1] "" ICC
 SG_ ECC_ComLost_CVM : 57|1@0+ (1,0) [0|1] "" ICC
 SG_ ECC_ComLost_MDV : 58|1@0+ (1,0) [0|1] "" ICC

BO_ 1650 ICC_0x672: 8 ICC
 SG_ ICC_SwVersS : 15|8@0+ (1,0) [0|255] "" ICC
 SG_ ICC_PartVers : 23|32@0+ (1,0) [0|4.29497e+09] "" ICC
 SG_ ICC_HwVers : 55|8@0+ (1,0) [0|255] "" ICC
 SG_ ICC_SwVersM : 63|8@0+ (1,0) [0|255] "" ICC

BO_ 1698 VCU_0x6A2: 8 GW
 SG_ VCU_SCChrgCnt : 7|16@0+ (1,0) [0|65535] "" ICC
 SG_ VCU_VehHVPwrOffTi : 23|24@0+ (1,0) [0|1.67772e+07] "min" ICC
 SG_ VCU_FCChrgCnt : 55|16@0+ (1,0) [0|65535] "" ICC

BO_ 1765 VCU_0x6E5: 8 GW
 SG_ VCU_VINCod1 : 7|64@0+ (1,0) [0|1.67772e+07] "" ICC

BO_ 1766 VCU_0x6E6: 8 GW
 SG_ VCU_VINCod2 : 7|64@0+ (1,0) [0|1.67772e+07] "" ICC

BO_ 1767 VCU_0x6E7: 8 GW
 SG_ VCU_VINCod3 : 7|64@0+ (1,0) [0|1.67772e+07] "" ICC

CM_ SG_ 791 ADAS_317_CheckSum "ADAS_0x317_message checksum ( E2E data ID:0xCD)";
CM_ SG_ 791 ADAS_317_AliveCounter "ADAS_317_Message counter";
CM_ SG_ 791 ADAS_LeMirrWarnSrc "Left mirror warning source (or reason). Signal used as information only";
CM_ SG_ 791 ADAS_LeMirrWarnReq "Left Mirror warning request";
CM_ SG_ 791 ADAS_ChimeReq "This signal controls the chime type for ADAS features.";
CM_ SG_ 791 ADAS_IDS_WarnTxtReq "ADAS warning text on IDS";
CM_ SG_ 791 ADAS_RiMirrWarnReq "Right mirror warning request";
CM_ SG_ 791 ADAS_IDS_LeWarnReq "Left warning on IDS (instrument cluster) request";
CM_ SG_ 791 ADAS_IDS_RiWarnReq "Right warning on IDS (instrument cluster) request";
CM_ SG_ 791 ADAS_IDS_LeWarnSrc "Left warning on IDS (instrument cluster) source. Signal used as information only";
CM_ SG_ 791 ADAS_IDS_RiWarnSrc "Right warning on IDS (instrument cluster) source. Signal used as information only";
CM_ SG_ 791 ADAS_SysFltWarnReq "ADAS fault telltale icon (on the cluster) warning request.";
CM_ SG_ 791 ADAS_SysFltTyp "This signal indicates ADAS fault types to be displayed on CID or cluster or both.";
CM_ SG_ 791 ADAS_RiMirrWarnSrc "Right mirror warning source (or reason). Signal used as information only";
CM_ SG_ 791 ADAS_DrvrTakeOvrReq "This signal indicates to the driver that takepover is necessary. Different stage are used.";
CM_ BO_ 791 "IBUS2, cyclic every 50 ms, sent by GW";
CM_ SG_ 794 ADAS_31A_CheckSum "ADAS_31A_Message Verification (E2E data ID: 0x37)";
CM_ SG_ 794 ADAS_31A_AliveCounter "ESP 31A_Message counterESP_31A_AliveCounter";
CM_ SG_ 794 ADAS_RAEBAvl "Indicates tha the Rear AEB is ready (available)";
CM_ SG_ 794 ADAS_FACM_TelltaleReq "FACM telltale request";
CM_ SG_ 794 ADAS_BACM_WarnSide "BACM warning side";
CM_ SG_ 794 ADAS_BrakeIntrvntnSt "Brake Assist status ADAS_BrkAssistSts";
CM_ SG_ 794 ADAS_AEB_Typ "AEB type for ICC";
CM_ SG_ 794 ADAS_AEBWarnSts "AEB warning status";
CM_ SG_ 794 ADAS_AEB_RAEB_WarnReq "Rear AEB warning request";
CM_ SG_ 794 ADAS_RAEB_ThreatID "Rear AEB Object ID of the threat";
CM_ SG_ 794 ADAS_AEBThreatID "AEB Threat ID";
CM_ SG_ 794 ADAS_BACMThreatID "BACM threat identifier";
CM_ SG_ 794 ADAS_ESA_TelltaleReq "ESA IDS(Instrument Cluster) Telltale request";
CM_ SG_ 794 ADAS_ELKA_TelltaleReq "ELKA LKA IDS(Instrument Cluster) Telltale request";
CM_ BO_ 794 "IBUS2, cyclic every 50 ms, sent by GW";
CM_ SG_ 795 ADAS_31B_CheckSum "ADAS_31B_Message Verification ( E2E data ID: 0x5A)";
CM_ SG_ 795 ADAS_31B_AliveCounter "ESP 31A_Message counterESP_31B_AliveCounter";
CM_ SG_ 795 ADAS_LCA_TrajectoryHeadingAngle "Lane change Trajectory end point Heading";
CM_ SG_ 795 ADAS_LaneCenteringHandsOnRew "Lane Centering Hands on request";
CM_ SG_ 795 ADAS_LCA_TrajectoryY "Lane change Trajectory end point Y, negative is m to the left, positive is m to the right";
CM_ SG_ 795 ADAS_LCA_TrajectoryX "Lane Change Trajectory of the ego vehicle";
CM_ SG_ 795 ADAS_ELKAThreatID "ELKA threat identifier";
CM_ BO_ 795 "IBUS2, cyclic every 50 ms, sent by GW";
CM_ SG_ 796 ADAS_AccTrgSpdDisp "Automatic Cruise Control (ACC) target speed display";
CM_ SG_ 796 ADAS_DispSpdUnit_ACC "Automatic Cruise Control (ACC) display unit";
CM_ SG_ 796 ADAS_AccTrgSpdOvrLmt "Automatic Cruise Control (ACC) target speed over limit";
CM_ SG_ 796 ADAS_TiGapSet_ACC "Automatic Cruise Control (ACC) time gap setting";
CM_ SG_ 796 ADAS_TiGapRecommendation_ACC "Automatic Cruise Control (ACC) recommendation for driver to change time gap at hight speed for safer following distance";
CM_ SG_ 796 ADAS_ACCPrimTgtID "Automatic Cruise Control (ACC) primary target identifier";
CM_ SG_ 796 ADAS_ACCScndTgtID "Automatic Cruise Control (ACC) secondary target identifier";
CM_ SG_ 796 ADAS_ACCIconDisp "ACC icon color";
CM_ SG_ 796 ADAS_ACCDegrdReq "Automatic Cruise Control (ACC) degradation to Cruise Control (CC) request";
CM_ SG_ 796 ADAS_ACCFuncTyp "Automatic Cruise Control (ACC) function type";
CM_ BO_ 796 "IBUS2, cyclic every 50 ms, sent by GW";
CM_ SG_ 800 ICC_VehFlameoutTi "Flameout time of vehicleQualifier of the signal.";
CM_ SG_ 800 ICC_VehFlameoutTiVld "Effective bit of vehicle flameout timeengine Off time of vehicle.";
CM_ BO_ 800 "IBUS2, cyclic every 50 ms, sent by ICC";
CM_ SG_ 801 BCM_AP_FL_LeFrntWinPosnInfo "Information about left front window opening";
CM_ SG_ 801 BCM_AP_FL_RiFrntWinPosnInfo "Right front window opening information";
CM_ SG_ 801 BCM_AP_FL_LeReWinPosnInfo "Left rear window opening information";
CM_ SG_ 801 BCM_AP_FL_RiReWinPosnInfo "Right rear window opening information";
CM_ SG_ 801 BCM_ValueLightFrnt_RLS "Front sensor measurement valueOutput value of forward light detection value";
CM_ SG_ 801 BCM_LightReqReason_RLS "Rain light sensor turn on light request reasonLight switch reason";
CM_ BO_ 801 "IBUS2, cyclic every 50 ms, sent by GW";
CM_ SG_ 811 ADAS_32B_CheckSum "ADAS_32B_CheckSum (E2E data ID: 0x5B)";
CM_ SG_ 811 ADAS_32B_AliveCounter "ADAS_32B_AliveCounter";
CM_ SG_ 811 ADAS_SelfGlaring "Self-glaring probability";
CM_ SG_ 811 ADAS_Obj_TrfcStyle "Traffic type";
CM_ SG_ 811 ADAS_CamSts "Camera state";
CM_ SG_ 811 ADAS_ObjNr "Detection target number";
CM_ SG_ 811 ADAS_AmbLi "Ambient brightness";
CM_ SG_ 811 ADAS_RoadIllmn "Street lamp detection";
CM_ BO_ 811 "IBUS2, cyclic every 40 ms, sent by GW";
CM_ SG_ 813 ADAS_Obj3_ID "Object identifier. If ID is 0x0 no object is detected";
CM_ SG_ 813 ADAS_Obj3_LongDist "Object Longitudinal distance";
CM_ SG_ 813 ADAS_Obj3_LatDist "Object Latitudinal distance";
CM_ SG_ 813 ADAS_Obj3_Width "Object Width";
CM_ SG_ 813 ADAS_Obj3_Conf "Object Confidence level";
CM_ SG_ 813 ADAS_Obj3_Length "Object length";
CM_ SG_ 813 ADAS_VVP_ICC_Obj3Hdng "Object 3 Heading Angle";
CM_ SG_ 813 ADAS_Obj3_Height "Object height";
CM_ SG_ 813 ADAS_Obj3_LongDistSign "Object longitudinal Distance Signal";
CM_ SG_ 813 ADAS_Obj3_LatDistSign "Object Latitudinal Distance Signal";
CM_ SG_ 813 ADAS_Obj3_Classification "Object Calssification";
CM_ SG_ 813 ADAS_VVP_ICC_Obj3BrkLght "Object 3 brake light on / off";
CM_ SG_ 813 ADAS_Obj3_ClassConf "Object Classification Confidence";
CM_ BO_ 813 "IBUS2, cyclic every 40 ms, sent by GW";
CM_ SG_ 815 ADAS_Obj6_ID "Object identifier. If ID is 0x0 no object is detected";
CM_ SG_ 815 ADAS_Obj6_LongDist "Object Longitudinal distance";
CM_ SG_ 815 ADAS_Obj6_LatDist "Object Latitudinal distance";
CM_ SG_ 815 ADAS_Obj6_Width "Object Width";
CM_ SG_ 815 ADAS_Obj6_Conf "Object Confidence level";
CM_ SG_ 815 ADAS_Obj6_Length "Object length";
CM_ SG_ 815 ADAS_VVP_ICC_Obj6Hdng "Object 6 Heading Angle";
CM_ SG_ 815 ADAS_Obj6_Height "Object height";
CM_ SG_ 815 ADAS_Obj6_LongDistSign "Object longitudinal Distance Signal";
CM_ SG_ 815 ADAS_Obj6_LatDistSign "Object Latitudinal Distance Signal";
CM_ SG_ 815 ADAS_Obj6_Classification "Object Calssification";
CM_ SG_ 815 ADAS_VVP_ICC_Obj6BrkLght "Object 6 brake light on / off";
CM_ SG_ 815 ADAS_Obj6_ClassConf "Object Classification Confidence";
CM_ BO_ 815 "IBUS2, cyclic every 40 ms, sent by GW";
CM_ SG_ 818 ESP_332_CheckSum "ESP 33232_Message Checksum ( E2E data ID: 0x8C)";
CM_ SG_ 818 ESP_332_AliveCounter "ESP 33232_Message counterESP_332_AliveCounter";
CM_ SG_ 818 ESP_EmgyBrkLi "Emergency braking requires double flashing lights (for ESS function)Emergency brake light on.";
CM_ SG_ 818 ESP_BrkLiReq "Brake lamp request requires to illuminate brake light.";
CM_ SG_ 818 ESP_OTAInhbRdy "ESP OTA inhibit ready status";
CM_ SG_ 818 ESP_ActvIndcn_HHC "Indicate if HHC is activated indicate HHC active signal.";
CM_ SG_ 818 ESP_FltIndcn_HHC "HHC fault indication indicating HHC is available or not.";
CM_ SG_ 818 ESP_ActvIndcn_AVH "Indicate if AVH is activated indicates AVH in active or not.";
CM_ SG_ 818 ESP_SwtIndcn_AVH "AVH ON indication AVH switch on without fault=standby. indicates AVH in standby mode or not.";
CM_ SG_ 818 ESP_FltIndcn_AVH "AVH fault indication indicating AVH is available or not.";
CM_ SG_ 818 ESP_ActvIndcn_CDP "Indicate if CDP is activated indicates CDP control active.";
CM_ SG_ 818 ESP_FltIndcn_CDP "CDP fault indication.indicating CDP is available or not.";
CM_ SG_ 818 ESP_ActvIndcn_HBB "HBB operation instructionThis signal indicates if HBB is active or not.";
CM_ SG_ 818 ESP_Sts_HBB "HBB state indicating the statues of HBB.";
CM_ SG_ 818 ESP_BrkPadWearWarn "brake pad wear warning";
CM_ BO_ 818 "IBUS2, cyclic every 50 ms, sent by GW";
CM_ SG_ 820 ADAS_334_CheckSum "ADAS_334_CheckSum (E2E data ID: 0x30)";
CM_ SG_ 820 ADAS_334_AliveCounter "ADAS_1C0_AliveCounter";
CM_ SG_ 820 ADAS_FobdSign "Prohibited traffic signs";
CM_ SG_ 820 ADAS_FrntCamBli "Front camera blocking";
CM_ SG_ 820 ADAS_AHBA_FltTxt "Intelligent high beam function failure";
CM_ SG_ 820 ADAS_FrntCamFlt "Front camera fault (not handled by ICC temporarily)";
CM_ SG_ 820 ADAS_AHBA_LiSigReq "HMA lamplight signal requestAdaptive high/low beam switching";
CM_ SG_ 820 ADAS_RngIntlSpdLim "Distance from the speed limit end of the section (reserved)";
CM_ BO_ 820 "IBUS2, cyclic every 50 ms, sent by GW";
CM_ SG_ 825 ADAS_LeLine1Crvt "Real left lane 1 curvature (observed)";
CM_ SG_ 825 ADAS_LeLine1LnColor "Real left lane line 1 color (observation)";
CM_ SG_ 825 ADAS_LeLine1Offset "offset of the left lane line 1";
CM_ SG_ 825 ADAS_LeLine1LnTyp "True left lane line 1 type (observed)";
CM_ SG_ 825 ADAS_LeLine1Hdng "Heading of the left lane line 1";
CM_ SG_ 825 ADAS_LeLine1Conf "Left lane line 1 confidence";
CM_ SG_ 825 ADAS_LeLine1CrvtRt "Rate of curvature of the left lane line 1";
CM_ BO_ 825 "IBUS2, cyclic every 50 ms, sent by GW";
CM_ SG_ 827 ADAS_Obj1_ID "Object identifier. If ID is 0x0 no object is detected";
CM_ SG_ 827 ADAS_Obj1_LongDist "Object Longitudinal distance";
CM_ SG_ 827 ADAS_Obj1_LatDist "Object Latitudinal distance";
CM_ SG_ 827 ADAS_Obj1_Width "Object Width";
CM_ SG_ 827 ADAS_Obj1_Conf "Object Confidence level";
CM_ SG_ 827 ADAS_Obj1_Length "Object length";
CM_ SG_ 827 ADAS_VVP_ICC_Obj1Hdng "Object 1 Heading Angle";
CM_ SG_ 827 ADAS_Obj1_Height "Object height";
CM_ SG_ 827 ADAS_Obj1_LongDistSign "Object longitudinal Distance Signal";
CM_ SG_ 827 ADAS_Obj1_LatDistSign "Object Latitudinal Distance Signal";
CM_ SG_ 827 ADAS_Obj1_Classification "Object Calssification";
CM_ SG_ 827 ADAS_VVP_ICC_Obj1BrkLght "Object 1 brake light on / off";
CM_ SG_ 827 ADAS_Obj1_ClassConf "Object Classification Confidence";
CM_ BO_ 827 "IBUS2, cyclic every 40 ms, sent by GW";
CM_ SG_ 829 ADAS_Obj4_ID "Object identifier. If ID is 0x0 no object is detected";
CM_ SG_ 829 ADAS_Obj4_LongDist "Object Longitudinal distance";
CM_ SG_ 829 ADAS_Obj4_LatDist "Object Latitudinal distance";
CM_ SG_ 829 ADAS_Obj4_Width "Object Width";
CM_ SG_ 829 ADAS_Obj4_Conf "Object Confidence level";
CM_ SG_ 829 ADAS_Obj4_Length "Object length";
CM_ SG_ 829 ADAS_VVP_ICC_Obj4Hdng "Object 4 Heading Angle";
CM_ SG_ 829 ADAS_Obj4_Height "Object height";
CM_ SG_ 829 ADAS_Obj4_LongDistSign "Object longitudinal Distance Signal";
CM_ SG_ 829 ADAS_Obj4_LatDistSign "Object Latitudinal Distance Signal";
CM_ SG_ 829 ADAS_Obj4_Classification "Object Calssification";
CM_ SG_ 829 ADAS_VVP_ICC_Obj4BrkLght "Object 4 brake light on / off";
CM_ SG_ 829 ADAS_Obj4_ClassConf "Object Classification Confidence";
CM_ BO_ 829 "IBUS2, cyclic every 40 ms, sent by GW";
CM_ SG_ 831 ADAS_Obj7_ID "Object identifier. If ID is 0x0 no object is detected";
CM_ SG_ 831 ADAS_Obj7_LongDist "Object Longitudinal distance";
CM_ SG_ 831 ADAS_Obj7_LatDist "Object Latitudinal distance";
CM_ SG_ 831 ADAS_Obj7_Width "Object Width";
CM_ SG_ 831 ADAS_Obj7_Conf "Object Confidence level";
CM_ SG_ 831 ADAS_Obj7_Length "Object length";
CM_ SG_ 831 ADAS_VVP_ICC_Obj7Hdng "Object 7 Heading Angle";
CM_ SG_ 831 ADAS_Obj7_Height "Object height";
CM_ SG_ 831 ADAS_Obj7_LongDistSign "Object longitudinal Distance Signal";
CM_ SG_ 831 ADAS_Obj7_LatDistSign "Object Latitudinal Distance Signal";
CM_ SG_ 831 ADAS_Obj7_Classification "Object Calssification";
CM_ SG_ 831 ADAS_VVP_ICC_Obj7BrkLght "Object 7 brake light on / off";
CM_ SG_ 831 ADAS_Obj7_ClassConf "Object Classification Confidence";
CM_ BO_ 831 "IBUS2, cyclic every 40 ms, sent by GW";
CM_ SG_ 832 ADAS_340_Checksum "ADAS_340_Message checksum ( E2E data ID: 0x32)";
CM_ SG_ 832 ADAS_340_AliveCounter "ADAS340_Message CounterADAS_340_AliveCounter";
CM_ SG_ 832 ADAS_LeLineColor "Left lane line colorThe color of the left line.";
CM_ SG_ 832 ADAS_RiLineColor "Right lane line colorThe color of the Right line.";
CM_ SG_ 832 ADAS_LeLineDst "Distance from the ego vehicle to the left lane lineindicate the y distance between the leftline and the ego car center.";
CM_ SG_ 832 ADAS_RiLineDst "Distance from the ego vehicle to the right lane lineindicate the y distance between the Rightline and the ego car center.";
CM_ SG_ 832 ADAS_LeLineFlash "Flashing of left lane line";
CM_ SG_ 832 ADAS_RiLineFlash "Right lane flashing";
CM_ SG_ 832 ADAS_LeLineTyp "Left lane line typeThe type of the left line.";
CM_ SG_ 832 ADAS_RiLineTyp "Right lane line typeThe type of the Right line.";
CM_ SG_ 832 ADAS_LaneCrvt "Lane curvatureThe radium of the ego cars lane.";
CM_ SG_ 832 ADAS_FltIndcr "ADAS fault lamp indication (MRR/ADAS receive fault, hardware occlusion and fault of all functions, send this signal)";
CM_ BO_ 832 "IBUS2, cyclic every 50 ms, sent by GW";
CM_ SG_ 834 ADAS_342_Checksum "ADAS_342_Message checksum ( E2E data ID: 0x35)";
CM_ SG_ 834 ADAS_342_AliveCounter "ADAS342_Message CounterADAS_342_AliveCounter";
CM_ SG_ 834 ADAS_LatCtrl_LeTurnLampReq "Left turn lamp request";
CM_ SG_ 834 ADAS_LatCtrl_RiTurnLampReq "Right turn lamp request";
CM_ SG_ 834 ADAS_LatCtrl_HapticReq "Haptic request (EPS vibration)";
CM_ SG_ 834 ADAS_LatCtrl_HzrdLampReq "Hazard light activation";
CM_ SG_ 834 ADAS_VehMovDir "vehicle movment information so user is able to see the vehicle activities on the smartphone while using Remote Automated Parking function";
CM_ SG_ 834 ADAS_HOD_HandsOnWarnReq "Hands On Detection (HOD) hands on warning request (request driver to put hands on steering wheel)";
CM_ SG_ 834 ADAS_RAPAvl "RPA feature available status flag to PKC";
CM_ SG_ 834 ADAS_Sts_RAP "Remote Park Assist (RPA) feature status to PKC";
CM_ SG_ 834 ADAS_ExtLightReq "ADAS DC can request exterior light activation";
CM_ SG_ 834 ADAS_HODSts "Hands On Detection (HOD)";
CM_ BO_ 834 "IBUS2, CE every 50 ms, sent by GW";
CM_ SG_ 836 ICC_NavMsgText1 "Navigation information text";
CM_ BO_ 836 "IBUS2, cyclic every 50 ms, sent by ICC";
CM_ SG_ 837 BCM_345_CheckSum "BCM_345_Message checksum ( 0xD9)BCM_345_CheckSum";
CM_ SG_ 837 BCM_345_AliveCounter "BCM345_Packet counterBCM_345_AliveCounter";
CM_ SG_ 837 BCM_OutpValResl_HUD "HUD output value resolution";
CM_ SG_ 837 BCM_SunshadeRunngSts "Sunshade running status";
CM_ SG_ 837 BCM_RiSolaValr_RLS "Solar radiation intensity at the right side";
CM_ SG_ 837 BCM_LeSolaValr_RLS "Left solar radiation intensity";
CM_ SG_ 837 BCM_WindshdHum_RLS "Glass humidity";
CM_ SG_ 837 BCM_WindshdT_RLS "Glass temperature";
CM_ SG_ 837 BCM_MeasdVal_HUD "HUD function measurement value";
CM_ SG_ 837 BCM_SunshadePosnInfo "Sunshade opening information";
CM_ BO_ 837 "IBUS2, cyclic every 50 ms, sent by GW";
CM_ SG_ 841 ICC_KaraokeMsgText1 "Karaoke information text";
CM_ BO_ 841 "IBUS2, cyclic every 50 ms, sent by ICC";
CM_ SG_ 843 ADAS_Obj2_ID "Object identifier. If ID is 0x0 no object is detected";
CM_ SG_ 843 ADAS_Obj2_LongDist "Object Longitudinal distance";
CM_ SG_ 843 ADAS_Obj2_LatDist "Object Latitudinal distance";
CM_ SG_ 843 ADAS_Obj2_Width "Object Width";
CM_ SG_ 843 ADAS_Obj2_Conf "Object Confidence level";
CM_ SG_ 843 ADAS_Obj2_Length "Object length";
CM_ SG_ 843 ADAS_VVP_ICC_Obj2Hdng "Object 2 Heading Angle";
CM_ SG_ 843 ADAS_Obj2_Height "Object height";
CM_ SG_ 843 ADAS_Obj2_LongDistSign "Object longitudinal Distance Signal";
CM_ SG_ 843 ADAS_Obj2_LatDistSign "Object Latitudinal Distance Signal";
CM_ SG_ 843 ADAS_Obj2_Classification "Object Calssification";
CM_ SG_ 843 ADAS_VVP_ICC_Obj2BrkLght "Object 2 brake light on / off";
CM_ SG_ 843 ADAS_Obj2_ClassConf "Object Classification Confidence";
CM_ BO_ 843 "IBUS2, cyclic every 40 ms, sent by GW";
CM_ SG_ 845 ADAS_Obj5_ID "Object identifier. If ID is 0x0 no object is detected";
CM_ SG_ 845 ADAS_Obj5_LongDist "Object Longitudinal distance";
CM_ SG_ 845 ADAS_Obj5_LatDist "Object Latitudinal distance";
CM_ SG_ 845 ADAS_Obj5_Width "Object Width";
CM_ SG_ 845 ADAS_Obj5_Conf "Object Confidence level";
CM_ SG_ 845 ADAS_Obj5_Length "Object length";
CM_ SG_ 845 ADAS_VVP_ICC_Obj5Hdng "Object 5 Heading Angle";
CM_ SG_ 845 ADAS_Obj5_Height "Object height";
CM_ SG_ 845 ADAS_Obj5_LongDistSign "Object longitudinal Distance Signal";
CM_ SG_ 845 ADAS_Obj5_LatDistSign "Object Latitudinal Distance Signal";
CM_ SG_ 845 ADAS_Obj5_Classification "Object Calssification";
CM_ SG_ 845 ADAS_VVP_ICC_Obj5BrkLght "Object 5 brake light on / off";
CM_ SG_ 845 ADAS_Obj5_ClassConf "Object Classification Confidence";
CM_ BO_ 845 "IBUS2, cyclic every 40 ms, sent by GW";
CM_ SG_ 847 ADAS_Obj8_ID "Object identifier. If ID is 0x0 no object is detected";
CM_ SG_ 847 ADAS_Obj8_LongDist "Object Longitudinal distance";
CM_ SG_ 847 ADAS_Obj8_LatDist "Object Latitudinal distance";
CM_ SG_ 847 ADAS_Obj8_Width "Object Width";
CM_ SG_ 847 ADAS_Obj8_Conf "Object Confidence level";
CM_ SG_ 847 ADAS_Obj8_Length "Object length";
CM_ SG_ 847 ADAS_VVP_ICC_Obj8Hdng "Object 8 Heading Angle";
CM_ SG_ 847 ADAS_Obj8_Height "Object height";
CM_ SG_ 847 ADAS_Obj8_LongDistSign "Object longitudinal Distance Signal";
CM_ SG_ 847 ADAS_Obj8_LatDistSign "Object Latitudinal Distance Signal";
CM_ SG_ 847 ADAS_Obj8_Classification "Object Calssification";
CM_ SG_ 847 ADAS_VVP_ICC_Obj8BrkLght "Object 8 brake light on / off";
CM_ SG_ 847 ADAS_Obj8_ClassConf "Object Classification Confidence";
CM_ BO_ 847 "IBUS2, cyclic every 40 ms, sent by GW";
CM_ SG_ 848 ADAS_LeftLaneWidth "Estimated width of the lane to the left of the ego vehicle lane";
CM_ SG_ 848 ADAS_RightLaneWidth "Estimated width of the lane to the right of the ego vehicle lane";
CM_ SG_ 848 ADAS_LeftLaneType "Type of lane to the left of the ego vehicle lane, classifications to be defined";
CM_ SG_ 848 ADAS_RightLaneType "Type of lane to the right of the ego vehicle lane, classifications to be defined";
CM_ SG_ 848 ADAS_LandmarkType "Type of Landmark detected";
CM_ SG_ 848 ADAS_LaneMarkingDistance "Distance to the most significant lane markings";
CM_ SG_ 848 ADAS_LaneMarkingType "Type of lane marking, in order of significance";
CM_ SG_ 848 ADAS_ConstructionObjectType "Construction object type";
CM_ SG_ 848 ADAS_ConstructionObjectDst "Distance to construction object";
CM_ SG_ 848 ADAS_LandmarkDst "Distance to Landmark";
CM_ BO_ 848 "IBUS2, cyclic every 100 ms, sent by GW";
CM_ SG_ 849 ADAS_351_CheckSum "ADAS_351_Message Verification (E2E data ID: 0x38)";
CM_ SG_ 849 ADAS_351_AliveCounter "ESP 31A_Message counterESP_31A_AliveCounter";
CM_ SG_ 849 ADAS_LdngVhclTurnSig "turn signals for preceeding vehicle";
CM_ SG_ 849 ADAS_LdngVhclBrkLi "brake lights for preceeding vehicle";
CM_ SG_ 849 ADAS_HzdDetected "Whether or not a hazard is detected";
CM_ SG_ 849 ADAS_HzdClassification "Hazard Classification, Magan and Fisker should collaborate on defining hazard classifications";
CM_ SG_ 849 ADAS_HzdDst "Hazard distance from Ego Vehicle";
CM_ SG_ 849 ADAS_TrafficLiDst "Distance to the most critical traffic light";
CM_ BO_ 849 "IBUS2, cyclic every 100 ms, sent by GW";
CM_ SG_ 850 ADAS_USS_B0 "USS Rear sector 0";
CM_ SG_ 850 ADAS_USS_F0 "USS Front sector 0";
CM_ SG_ 850 ADAS_USS_B1 "USS Rear sector 1";
CM_ SG_ 850 ADAS_USS_F1 "USS Front sector 1";
CM_ SG_ 850 ADAS_USS_B2 "USS Rear sector 2";
CM_ SG_ 850 ADAS_USS_F2 "USS Front sector 2";
CM_ SG_ 850 ADAS_USS_B3 "USS Rear sector 3";
CM_ SG_ 850 ADAS_USS_F3 "USS Front sector 3";
CM_ SG_ 850 ADAS_USS_L0 "USS Left sector 0";
CM_ SG_ 850 ADAS_USS_L1 "USS Left sector 1";
CM_ SG_ 850 ADAS_USS_L2 "USS Left sector 2";
CM_ SG_ 850 ADAS_USS_L3 "USS Left sector 3";
CM_ SG_ 850 ADAS_USS_R0 "USS Right sector 0";
CM_ SG_ 850 ADAS_USS_R1 "USS Right sector 1";
CM_ SG_ 850 ADAS_USS_R2 "USS Right sector 2";
CM_ SG_ 850 ADAS_USS_R3 "USS Right sector 3";
CM_ BO_ 850 "IBUS2, cyclic every 100 ms, sent by GW";
CM_ SG_ 851 ADAS_353_CheckSum "ADAS_353_Message Verification ( E2E data ID: 0x46 )";
CM_ SG_ 851 ADAS_353_AliveCounter "ADAS 353_Message counter";
CM_ SG_ 851 ADAS_VwPrtCamAngl "Virtual view camera angle";
CM_ SG_ 851 ADAS_LdngVhclID "Object ID of vehicle in front of ego vehicle (0 if no vehicle present within 50m)";
CM_ BO_ 851 "IBUS2, cyclic every 100 ms, sent by GW";
CM_ SG_ 854 ADAS_356_CheckSum "APA_356_Message Check (0x87)APA_356_CheckSum";
CM_ SG_ 854 ADAS_356_AliveCounter "APA_356APA_356_AliveCounter";
CM_ SG_ 854 ADAS_ObjDst_FLS "Front left obstacle distancePark Assistant Rear Left Side Object Distance.";
CM_ SG_ 854 ADAS_ObjDst_FLC "Obstacle distance of front left cornerPark Assistant Front Left Corne Object Distance.";
CM_ SG_ 854 ADAS_ObjDst_FLM "Front left middle obstacle distancePark Assistant Front Left Middle Object Distance.";
CM_ SG_ 854 ADAS_ObjDst_FRS "Distance between front right obstaclePark Assistant Front Right Side Object Distance.";
CM_ SG_ 854 ADAS_ObjDst_FRC "Obstacle distance of front right cornerPark Assistant Front Right Corner Object Distance.";
CM_ SG_ 854 ADAS_ObjDst_FRM "Front right middle obstacle distancePark Assistant Front Right Middle Object Distance.";
CM_ BO_ 854 "IBUS2, cyclic every 100 ms, sent by GW";
CM_ SG_ 855 VCU_357_CheckSum "VCU_357_Message checksum ( E2E data ID: 0xB3)";
CM_ SG_ 855 VCU_357_AliveCounter "VCU_357_Message counterVCU_357_AliveCounter";
CM_ SG_ 855 VCU_ChrgSts_GB "Charging state (national standard)";
CM_ SG_ 855 VCU_MCUFltSum_GB "Total number N2 of driving motor faults (national standard)";
CM_ SG_ 855 VCU_BrkPedlSts_GB "Brake pedal state (national standard)";
CM_ SG_ 855 VCU_SOCLoWakeUpThd "Low power wake-up threshold";
CM_ SG_ 855 VCU_SOCLoWakeUpEnaCmd "Power low wake-up enable command";
CM_ SG_ 855 VCU_DrvModDiRmn "Disable the instrument reminder in driving mode";
CM_ SG_ 855 VCU_SpclTerrainModUsrRmn "All-terrain mode user reminder";
CM_ SG_ 855 VCU_BattIntegtChrgEndFlg "Battery Intelligent end-of-charge flag position";
CM_ SG_ 855 VCU_BattIntegtChrgModPwrOnReq "Battery smart charging mode power-on demand";
CM_ SG_ 855 VCU_BattIntegtChrgWakeUpSts "Battery intelligent charging wake-up state";
CM_ SG_ 855 VCU_RemUgrdFltFbSig "Remote Upgrade Fault Feedback Signal";
CM_ SG_ 855 VCU_OTAInhbRdy "OTA pre-condition and Inhibiting of all OTA relevant ECUs";
CM_ BO_ 855 "IBUS2, cyclic every 100 ms, sent by GW";
CM_ SG_ 857 ADAS_359_CheckSum "APA_359_CheckSum (0x99)";
CM_ SG_ 857 ADAS_359_AliveCounter "APA_359_AliveCounter";
CM_ SG_ 857 ADAS_ObjDst_RLS "Rear left obstacle distancePark Assistant Rear Left Side Object Distance.";
CM_ SG_ 857 ADAS_ObjDst_RLC "Rear left corner obstacle distancePark Assistant Rear Left Corner Object Distance.";
CM_ SG_ 857 ADAS_ObjDst_RLM "Rear left middle obstacle distancePark Assistant Rear Left Middle Object Distance.";
CM_ SG_ 857 ADAS_ObjDst_RRS "Rear right obstacle distancePark Assistant Rear Right Side Object Distance.";
CM_ SG_ 857 ADAS_ObjDst_RRC "Obstacle distance of right rear cornerPark Assistant Rear Right Corner Object Distance.";
CM_ SG_ 857 ADAS_ObjDst_RRM "Rear right middle obstacle distancePark Assistant Rear Right Middle Object Distance.";
CM_ BO_ 857 "IBUS2, cyclic every 100 ms, sent by GW";
CM_ SG_ 859 ICC_ViewReq "Request from ICC to activates Surround View";
CM_ SG_ 859 ICC_SVS_AutoVwBttnReq "This signal incidates if the user selects automatic camera view";
CM_ SG_ 859 ICC_SVS_CamVwCnclReq "This signal incidates if the user presses the button to exit camera view.";
CM_ SG_ 859 ICC_AutomaticViewReq "To enable or disabled the automatic view from ICC setting menu";
CM_ SG_ 859 ICC_360FreeFloatingReq "To enable or disabled the automatic view from ICC setting menu";
CM_ SG_ 859 ICC_GraphicOverlayReq "To enable or disable viewing of graphic overlays presented in the LVDS viewport";
CM_ SG_ 859 ICC_OperationType "This signal conveys different types of user operations";
CM_ SG_ 859 ICC_ZOOM_Start "Zoom operations start status";
CM_ SG_ 859 ICC_ZOOM_End "Zoom operation end status";
CM_ SG_ 859 ICC_ZOOM_ScalingFactor "Floating point value between 0-32 to represent the amount of zoom";
CM_ SG_ 859 ICC_EnbLnChgAsst "Signal request for LCA activation in user settings";
CM_ SG_ 859 ICC_BSDSetting "Blind Spot Detection (BSD) user option setting";
CM_ SG_ 859 ICC_DOW_Setting "Door Open Warning (DOW) user options setting";
CM_ SG_ 859 ICC_DCAASetting "Driver Condition and Attention Assist (DCAA) user option setting";
CM_ SG_ 859 ICC_APA_Setting "Feature on/off setting";
CM_ SG_ 859 ICC_APAParkSelect "Status of slot selection by user through HMI";
CM_ SG_ 859 ICC_APAActivation "User can activte by pressing P button or voice. Pressing P button again cancels it.";
CM_ SG_ 859 ICC_APAParkInDirSetting "Parking in preference by user - vertical parking";
CM_ SG_ 859 ICC_APAParkOutDirSetting "Parking out preference by user - vertical parking";
CM_ SG_ 859 ICC_ParkAsstChmAlrt "Parking assist / APA audio aler preference by user";
CM_ SG_ 859 ICC_WSPPA_Setting "Wheel scratch protection preference by user";
CM_ SG_ 859 ICC_APAParkOutAct "Signal indicating the Park Out maneuver is started";
CM_ SG_ 859 ICC_SteerWhlVibrSet "signal for steering wheel vibration selection on CID for LKA";
CM_ SG_ 859 ICC_LKA_SettingWrnTyp "ICC setting signal for lane support";
CM_ SG_ 859 ICC_RAP_Setting "ICC setting to enable or disable the Remote Automated Parking (RAP). If enabled driver can control the RAP outside the vehicle (Feature in Standby).";
CM_ SG_ 859 ICC_TP_Setting "ICC setting to enable or disable the Trained Parking (TP). If enabled driver can control the TP outside the vehicle (Feature in Standby)";
CM_ SG_ 859 ICC_BSD_Sensitivity "Senstivity Setting for Blind Spot detection";
CM_ BO_ 859 "IBUS2, CE every 200 ms, sent by ICC";
CM_ SG_ 865 ICC_PosnMsgTye "Identify the message as Position Message";
CM_ SG_ 865 ICC_PosnOffset "Position of the vehicle from the starting point of the pathOffset of current position from the current path’s start point modulo 8191. Value 8191 is invalid.";
CM_ SG_ 865 ICC_PosnPathldx "Current Path index numberIndex of current path:If this number differs from the one transmitted in the previous POSITION message with Position Index = 0, the vehicle has left the original path; Indices 0-7 have special meaning:see sheet2 for details";
CM_ SG_ 865 ICC_PosnCycCnt "Loop counter of Position Message: Reconstructor can use this value to detect missing messagesCyclic counter of this message type:Reconstructor can use this value to detect missing messages";
CM_ SG_ 865 ICC_PosnPosProbb "Resolution should be 100/30 %";
CM_ SG_ 865 ICC_PosnCurLane "Current lane";
CM_ SG_ 865 ICC_PosnPosConfdc "Position confidence levelPosition confidence:this field contains Av2HP implementation specific values. Use 0 for highest confidence, 6 for lowest confidence. Value 7 means N/A";
CM_ SG_ 865 ICC_PosnSpd "Estimated speed of vehicle along Path";
CM_ SG_ 865 ICC_PosnRehead "Front direction relative to path Resolution should be 360/254 degrees";
CM_ BO_ 865 "IBUS2, cyclic every 100 ms, sent by ICC";
CM_ SG_ 866 ICC_MetaMapProvider "Map providers of the current area (map tile, area, country...).";
CM_ SG_ 866 ICC_MetaMsgType "Identify the message bit";
CM_ SG_ 866 ICC_MetaCountryCode "Country codeISO 3166-1 Release 2007-03 country code of current position;0 stands for unknown. Valid values are those specified by ISO 3166-1 numeric [14].";
CM_ SG_ 866 ICC_MetaProtVerMinorSub "Secondary agreement sub-versionContains Minor protocol sub-version.";
CM_ SG_ 866 ICC_MetaProtVerMajor "Main agreement versionContains Major protocol version.";
CM_ SG_ 866 ICC_MetaCycCnt "This message type loop counter: The reconstructor can use this value to detect missing messagesCyclic counter of this message type:Reconstructor can use this value to detect missing messages.";
CM_ SG_ 866 ICC_MetaHwVer "Hardware and/or software version of generator";
CM_ SG_ 866 ICC_MetaDrvSide "Driving direction";
CM_ SG_ 866 ICC_MetaRegionCode "Area code0 stands for unknown, value 32767 means N/AAll other values are based on ISO 3166-2 [15] with the code mapping scheme.";
CM_ SG_ 866 ICC_MetaMapVerYear "Map version (year)Please note if the whole map may be partitioned into parts that can be released on different times or even by different providers. In that case, value of this field may vary between messages. 63 stands for N/A";
CM_ SG_ 866 ICC_MetaMapVerQtr "Map version (quarter)Please note if the whole map may be partitioned into parts that can be released on different times or even by different providers. In that case, value if this field may vary between messages.";
CM_ SG_ 866 ICC_MetaProtVerMinor "Minor agreement version";
CM_ SG_ 866 ICC_MetaSpdUnits "Speed limit unit";
CM_ SG_ 866 ICC_Reserved "Reserved space";
CM_ BO_ 866 "IBUS2, cyclic every 100 ms, sent by ICC";
CM_ SG_ 867 VCU_ACDchaStrtFailReason "Reasons for AC discharge failure or current drop";
CM_ SG_ 867 VCU_AllwRemHeatgSts "VCU allows remote heating status";
CM_ SG_ 867 VCU_FbRemHeatgOperSts "VCU feedback of remote heating working status";
CM_ SG_ 867 VCU_ChrgEndSOCCrtCtrlFlg "SOC correction current control mark at charging end";
CM_ SG_ 867 VCU_Lvl2ProtStrtFlg "Secondary protection start flag bit";
CM_ SG_ 867 VCU_TotOverVoltLvl2ProtFlg "Total voltage overvoltage secondary protection flag bit";
CM_ SG_ 867 VCU_UnderVoltFltLvl2ProtFlg "Undervoltage fault secondary protection flag bit";
CM_ SG_ 867 VCU_OverTFltLvl2ProtFlg "Overtemperature fault secondary protection flag bit";
CM_ SG_ 867 VCU_OverVoltFltLvl2ProtFlg "Overvoltage fault secondary protection flag bit";
CM_ SG_ 867 VCU_CellIntShoFltLvl2ProtFlg "Secondary protection symbol in single cell internal short circuit fault";
CM_ SG_ 867 VCU_InsulFltLvl2ProtFlg "Insulation fault secondary protection flag bit";
CM_ SG_ 867 VCU_VehCfgExchgFlg "VCU models are equipped with interchangeable marks";
CM_ SG_ 867 VCU_ReadEEFailFlg "VCU reading EE failure flag bit";
CM_ SG_ 867 VCU_WrEEFailFlg "VCU write EE failure flag bit";
CM_ SG_ 867 VCU_FirstUseEEFlg "EE flag is used for the first time in VCU";
CM_ SG_ 867 VCU_SwUpdataFlg "VCU software upgrade flag bit";
CM_ SG_ 867 VCU_NewOldEESwtFlg "VCU new and old EE switching flag bit";
CM_ SG_ 867 VCU_FSCFillEndFlg "Fast and slow charging and normal filling end flag position";
CM_ SG_ 867 VCU_MaxAlrmLvl "VCU maximum alarm level";
CM_ SG_ 867 VCU_UsrStopChrgReqSts "User termination charging request state";
CM_ SG_ 867 VCU_DchaIndcrLampCtrlCmd "Discharge indicator control command";
CM_ SG_ 867 VCU_VehExtDchaSts "External discharge state of vehicle";
CM_ SG_ 867 VCU_S1SwtCmd "S1 switch command";
CM_ SG_ 867 VCU_DchaFltStsIndcn "AC discharge system fault";
CM_ SG_ 867 VCU_DchaUsrSetThd "Whether the discharge reaches the user set threshold";
CM_ SG_ 867 VCU_RemHeatgDmd "VCU remote heating demand";
CM_ SG_ 867 VCU_PwrBattHeatgTyp "Traction battery heating method";
CM_ SG_ 867 VCU_RemPwrBattPreheatgDmdTi "Time required for preheating of remote traction battery";
CM_ SG_ 867 VCU_ChrgInsulFctOpenSts "Charging insulation function on state";
CM_ SG_ 867 VCU_ChrgEquipPwrNotEngh "Insufficient charging equipment power";
CM_ SG_ 867 VCU_ACChrgStrtFailReason "AC charging cannot be turned on or current charging is reduced";
CM_ BO_ 867 "IBUS2, cyclic every 100 ms, sent by GW";
CM_ SG_ 873 BCM_AP_TL_LeReWinPosnInfo "Information about the 3th left rear window opening";
CM_ SG_ 873 BCM_AP_TL_RiReWinPosnInfo "Information about the 3th right rear window opening";
CM_ SG_ 873 BCM_AP_RW_WinPosnInfo "Information about rear windowshield window opening";
CM_ SG_ 873 BCM_AP_TL_LeReWinSts "Opening and closing state of the 3th left rear window";
CM_ SG_ 873 BCM_AP_TL_RiReWinSts "Opening and closing state of the 3th right window";
CM_ SG_ 873 BCM_AP_RW_WinSts "Opening and closing state of left rear window";
CM_ SG_ 873 BCM_BackgndBriLvl_Cfm "Confirmation of brightness level from BCM to ICC";
CM_ SG_ 873 BCM_LeMirrrXDircAdjSwtSts "Left mirror X direction adjust switch state";
CM_ SG_ 873 BCM_LeMirrrYDircAdjSwtSts "Left mirror Y direction adjust switch state";
CM_ SG_ 873 BCM_RiMirrrXDircAdjSwtSts "Right mirror X direction adjust switch state";
CM_ SG_ 873 BCM_RiMirrrYDircAdjSwtSts "Right mirror Y direction adjust switch state";
CM_ SG_ 873 BCM_MirrSelectSwtSts "Mirror select switch status";
CM_ BO_ 873 "IBUS2, cyclic every 100 ms, sent by GW";
CM_ SG_ 874 PKC_KeySerialNumber_0 "Serial Number Byte 0 (LSB)";
CM_ SG_ 874 PKC_KeySerialNumber_1 "Serial Number Byte 1";
CM_ SG_ 874 PKC_KeySerialNumber_2 "Serial Number Byte 2";
CM_ SG_ 874 PKC_KeySerialNumber_3 "Serial Number Byte 3";
CM_ SG_ 874 PKC_KeySerialNumber_4 "Serial Number Byte 4";
CM_ SG_ 874 PKC_KeySerialNumber_5 "Serial Number Byte 5";
CM_ SG_ 874 PKC_KeySerialNumber_6 "Serial Number Byte 6";
CM_ SG_ 874 PKC_KeySerialNumber_7 "Serial Number Byte 7 (MSB)";
CM_ BO_ 874 "IBUS2, NoMsgSendType, sent by GW";
CM_ SG_ 875 PKC_PhoneConnStatus "known device - previously authenticated and paired deviceunknown device - device which hasn't been previously authenticated and paired";
CM_ SG_ 875 PKC_PhonePairingMode "PKC currently in Phone Pairing Mode";
CM_ SG_ 875 PKC_AutolLockUnlock_FB "Feedback of Auto lock/unlock enable status";
CM_ SG_ 875 PKC_KeyPairingMode "PKC currently in Keyfob Pairing Mode";
CM_ SG_ 875 PKC_Distance "Distance measurement in meters (if UWB is avaiable), if UWB is not avaiable, distance measurement value is set to 255, meaning unkown";
CM_ SG_ 875 PKC_UserProfileID "Linked User ID";
CM_ SG_ 875 PKC_PhonePairingCode1 "Code use during BLE Pairing of mobile phones";
CM_ SG_ 875 PKC_PhonePairingCode2 "Code use during BLE Pairing of mobile phones";
CM_ SG_ 875 PKC_PhonePairingCode3 "Code use during BLE Pairing of mobile phones";
CM_ SG_ 875 PKC_PhonePairingCode4 "Code use during BLE Pairing of mobile phones";
CM_ BO_ 875 "IBUS2, cyclic every 100 ms, sent by GW";
CM_ SG_ 876 PKC_PhoneAdvName1 "BLE Advertising name";
CM_ BO_ 876 "IBUS2, NoMsgSendType, sent by GW";
CM_ SG_ 877 PKC_NFCKeyID "Authenticated with KeyID number xx";
CM_ SG_ 877 PKC_NFCReaderExtStatus "1 - Under Voltage | 2 - Over Voltage | 3 - Memory Integrity Failure | 4 - RF Failure | 5 - RF Interference ---- Exterior NFC Reader";
CM_ SG_ 877 PKC_NFCReaderIntStatus "1 - Under Voltage | 2 - Over Voltage | 3 - Memory Integrity Failure | 4 - RF Failure | 5 - RF Interference ---- Interior NFC Reader";
CM_ BO_ 877 "IBUS2, NoMsgSendType, sent by GW";
CM_ SG_ 878 PKC_NFCSerialNumber_0 "Serial Number Byte 0 (LSB)";
CM_ SG_ 878 PKC_NFCSerialNumber_1 "Serial Number Byte 1";
CM_ SG_ 878 PKC_NFCSerialNumber_2 "Serial Number Byte 2";
CM_ SG_ 878 PKC_NFCSerialNumber_3 "Serial Number Byte 3";
CM_ SG_ 878 PKC_NFCSerialNumber_4 "Serial Number Byte 4";
CM_ SG_ 878 PKC_NFCSerialNumber_5 "Serial Number Byte 5";
CM_ SG_ 878 PKC_NFCSerialNumber_6 "Serial Number Byte 6";
CM_ SG_ 878 PKC_NFCSerialNumber_7 "Serial Number Byte 7 (MSB)";
CM_ BO_ 878 "IBUS2, NoMsgSendType, sent by GW";
CM_ SG_ 885 MCU_F_FltProcLvl "Pre-MCU fault handling levelMCUFLaultLevel.";
CM_ SG_ 885 MCU_F_MaxAlrmLvl "Highest alarm level of front MCUMCUFMaxAlrmLvl.";
CM_ SG_ 885 MCU_F_SysFltDisp "Front MCU system fault lampMCUFMotorSystemFaultDisplay.";
CM_ SG_ 885 MCU_F_SysFltAlrmCtrlSts "Control state of front MCU system fault alarm soundMCUFMotorSystemFaultAlarmControlState.";
CM_ SG_ 885 MCU_F_DrvrMotCrtSts_GB "Current state of drive motor 1 (national standard)";
CM_ SG_ 885 MCU_F_CooltEstimnT "Front MCU coolant estimated temperature";
CM_ BO_ 885 "IBUS2, cyclic every 100 ms, sent by GW";
CM_ SG_ 886 WTC_B_InlT "WTC_B inlet temperature";
CM_ SG_ 886 WTC_B_OutlT "WTC_B outlet temperature";
CM_ SG_ 886 WTC_B_CrtPwr "WTC_B current power";
CM_ SG_ 886 WTC_B_CrtT "WTC_B Current operating temperature";
CM_ SG_ 886 WTC_B_IninSts "WTC_B initialization state";
CM_ SG_ 886 WTC_B_HVPwrSplySts "WTC_B high voltage power supply state";
CM_ SG_ 886 WTC_B_ActGear "WTC_B Actual gear";
CM_ SG_ 886 WTC_B_Mod "WTC_B current operating mode";
CM_ BO_ 886 "IBUS2, cyclic every 100 ms, sent by GW";
CM_ SG_ 887 MCU_R_FltProcLvl "Rear MCU fault handling levelMCURLaultLevel.";
CM_ SG_ 887 MCU_R_MaxAlrmLvl "Highest alarm level of rear MCUMCURMaxAlrmLvl.";
CM_ SG_ 887 MCU_R_SysFltDisp "Rear MCU system fault lampMCURMotorSystemFaultDisplay.";
CM_ SG_ 887 MCU_R_SysFltAlrmCtrlSts "Rear MCU system fault alarm sound control stateMCURMotorSystemFaultAlarmControlState.";
CM_ SG_ 887 MCU_R_DrvrMotCrtSts_GB "Current state of drive motor 2 (national standard)";
CM_ SG_ 887 MCU_R_CooltEstimnT "Rear MCU coolant estimated temperature";
CM_ BO_ 887 "IBUS2, cyclic every 100 ms, sent by GW";
CM_ SG_ 889 WTC_H_InpT "WTC_H inlet temperature";
CM_ SG_ 889 WTC_H_OutpT "WTC_H outlet temperature";
CM_ SG_ 889 WTC_H_CrtPwr "WTC_H current power";
CM_ SG_ 889 WTC_H_CrtT "WTC_H Current operating temperature";
CM_ SG_ 889 WTC_H_IninSts "WTC_H initialization state";
CM_ SG_ 889 WTC_H_HVPwrSplySts "WTC_H high voltage power supply state";
CM_ SG_ 889 WTC_H_ActGear "WTC_H Actual gear";
CM_ SG_ 889 WTC_H_Mod "WTC_H current operating mode";
CM_ BO_ 889 "IBUS2, cyclic every 100 ms, sent by GW";
CM_ SG_ 896 PKC_CrtUsr "Current user";
CM_ SG_ 896 PKC_AddNewUserFb "Confirmation a user was added";
CM_ SG_ 896 PKC_RemovedUserIDFb "Confirmation a user was deleted";
CM_ SG_ 896 PKC_UnassignKeyFb "Confirmation a key unassign";
CM_ SG_ 896 PKC_RemoveKeyFb "Confirmation a key was removed";
CM_ SG_ 896 PKC_AuthentFb_PKC "PKC certification result";
CM_ SG_ 896 PKC_AuthentFb_TBOX "TBOxcertification result";
CM_ SG_ 896 PKC_AuthFailPromt "VCU authentication failure prompt";
CM_ BO_ 896 "IBUS2, cyclic every 100 ms, sent by GW";
CM_ SG_ 901 TBOX_PreHeatDepartTi1_Hr "Time for preheating_Hour";
CM_ SG_ 901 TBOX_PreHeatDepartTi1_Mins "Time for preheating_Minutes";
CM_ SG_ 901 TBOX_PreHeatDepartSet "Preheating depart set";
CM_ SG_ 901 TBOX_MonPreHeatDepartSet "Preheating depart set_Monday";
CM_ SG_ 901 TBOX_TuePreHeatDepartSet "Preheating depart set_Tuesday";
CM_ SG_ 901 TBOX_WedPreHeatDepartSet "Preheating depart set_Wednesday";
CM_ SG_ 901 TBOX_ThuPreHeatDepartSet "Preheating depart set_Thursday";
CM_ SG_ 901 TBOX_FriPreHeatDepartSet "Preheating depart set_Friday";
CM_ SG_ 901 TBOX_SatPreHeatDepartSet "Preheating depart set_Saturday";
CM_ SG_ 901 TBOX_SunPreHeatDepartSet "Preheating depart set_Sunday";
CM_ SG_ 901 TBOX_PreCdnTarT "the pre-conditioning time of a specific tagret temperature";
CM_ SG_ 901 TBOX_PreHeatDepartSetFb "feedback signal for PreHeating time schedule";
CM_ SG_ 901 TBOX_PreHeatDepartTi2_Hr "Time for preheating_Hour";
CM_ SG_ 901 TBOX_PreHeatDepartTi2_Mins "Time for preheating_Minutes";
CM_ BO_ 901 "IBUS2, cyclic every 100 ms, sent by GW";
CM_ SG_ 923 PKC_SysAlrmVld "Effective value of system warning";
CM_ SG_ 923 PKC_RemLockCmd_Key "Remote locking command";
CM_ SG_ 923 PKC_KeyStsMod "Key state mode";
CM_ SG_ 923 PKC_KeyID "Authenticated with KeyID number xx";
CM_ SG_ 923 PKC_KeyInCarRmn "Reminder of key falling in vehicle";
CM_ SG_ 923 PKC_RemLockCmd "Remote locking command";
CM_ SG_ 923 PKC_BatterySts "Key low battery prompt";
CM_ SG_ 923 PKC_KeyOutdCarPromt "Key not in vehicle reminder";
CM_ SG_ 923 PKC_DoorOpenRmd "Signal indicates that a locking request has been received when any door (except tailgate) is open.";
CM_ SG_ 923 PKC_StrtFailTyp "PEPS startup failure type";
CM_ SG_ 923 PKC_LockKeyInCarInd "Signal indicates that a locking request from outside the car was received while another key was left inside the car.";
CM_ SG_ 923 PKC_KeySts "Key state";
CM_ BO_ 923 "IBUS2, CE every 100 ms, sent by GW";
CM_ SG_ 983 PKC_PhoneAdvName2 "BLE Advertising name";
CM_ BO_ 983 "IBUS2, NoMsgSendType, sent by GW";
CM_ SG_ 984 PKC_PhoneAdvName3 "BLE Advertising name";
CM_ BO_ 984 "IBUS2, NoMsgSendType, sent by GW";
CM_ SG_ 985 PKC_PhoneAdvName4 "BLE Advertising name";
CM_ BO_ 985 "IBUS2, NoMsgSendType, sent by GW";
CM_ SG_ 986 PKC_PhoneAdvName5 "BLE Advertising name";
CM_ BO_ 986 "IBUS2, NoMsgSendType, sent by GW";
CM_ SG_ 987 PKC_PhoneAdvName6 "BLE Advertising name";
CM_ BO_ 987 "IBUS2, NoMsgSendType, sent by GW";
CM_ SG_ 988 PKC_PhoneAdvName7 "BLE Advertising name";
CM_ BO_ 988 "IBUS2, NoMsgSendType, sent by GW";
CM_ SG_ 989 PKC_PhoneAdvName8 "BLE Advertising name";
CM_ BO_ 989 "IBUS2, NoMsgSendType, sent by GW";
CM_ SG_ 1136 EPS_IninSts "EPS initialization state EPS Initiaf States Options.";
CM_ SG_ 1136 EPS_CrtSts "EPS current state EPS Current States.";
CM_ SG_ 1136 EPS_FltIndcn "EPS fault display EPS Fault indication .";
CM_ SG_ 1136 EPS_SteerWhlBackStsFb "Return state feedback";
CM_ SG_ 1136 EPS_AsscRate "EPS boost ratio";
CM_ SG_ 1136 EPS_AsscMotCrtPwr "EPS power assisted motor current power";
CM_ SG_ 1136 EPS_TqSnsrSigErr "EPS torque sensor main and auxiliary road signal calibration fault_C20CF02_Torque Sensor Signal Error.";
CM_ SG_ 1136 EPS_SteerAgSnsrFlt "EPS rotation angle sensor signal malfunction_C20CD01_Steering Angle Sensor-electrical Error.";
CM_ SG_ 1136 EPS_TSnsrFlt "EPS temperature detection signal invalid fault_C20D704_Temperature Sensor Error.";
CM_ SG_ 1136 EPS_ComLostFlt_ESP "EPS and ESP communication failure_U12FC87_Lost Communication with ESP Error.";
CM_ SG_ 1136 EPS_SpdDataErr "EPS inspection ESP speed data error_U12FC86_Implausible Signal Received from ESP Error.";
CM_ SG_ 1136 EPS_HwFlt "EPS controller malfunction_C20DB04_ECU Hardware Error.";
CM_ SG_ 1136 EPS_RlyFlt "EPS relay fault_C20DA01_ECU Fail-Safe Relay Error.";
CM_ SG_ 1136 EPS_MotPosnSnsrFlt "EPS motor rotor position signal fault_C20D001_Motor Position Sensor Error.";
CM_ SG_ 1136 EPS_SteerAgSnsrNotCalFlt "EPS rotation angle zero not calibrated faect_C20CE54_Steering Angle Sensor is not Calibrated Error.";
CM_ SG_ 1136 EPS_MotCrtFlt "EPS current abnormal fault_C20D528_C20D362_Motor Current Error.";
CM_ SG_ 1136 EPS_AsscMotCrt "EPS booster motor current";
CM_ BO_ 1136 "IBUS2, cyclic every 100 ms, sent by GW";
CM_ SG_ 1169 EAS_MotCrt "Compressor motor current";
CM_ SG_ 1169 EAS_HVUnderVoltFlt "Compressor high pressure undervoltage fault_P166616_E00";
CM_ SG_ 1169 EAS_HVOverVoltFlt "Compressor high pressure overvoltage fault_P166517_E00";
CM_ SG_ 1169 EAS_CrtSts "EAS current state";
CM_ SG_ 1169 EAS_IninSts "EAS initialization state";
CM_ SG_ 1169 EAS_OverCrtFlt "Compressor overcurrent fault_P166719_E00";
CM_ SG_ 1169 EAS_HVIntlkFlt "High pressure interlock failure of compressor_P166F94_E00";
CM_ SG_ 1169 EAS_IPMTOverFlt "Compressor IPM overtemperature fault_P166098_E00";
CM_ SG_ 1169 EAS_ComLost_ECC "Lost communication between EAS and ECC_U170187_E00";
CM_ SG_ 1169 EAS_CtrlCircFlt "Compressor control circuit faulty_P166909_E00";
CM_ SG_ 1169 EAS_IPMHwFlt "Compressor IPM hardware faulty_P166200_E00";
CM_ SG_ 1169 EAS_IPMT "Compressor IPM temperature";
CM_ SG_ 1169 EAS_CrtPwr "Compressor current power";
CM_ BO_ 1169 "IBUS2, cyclic every 100 ms, sent by GW";
CM_ SG_ 1283 VCU_DrvPwrLimPerc "Drive power limit percentage";
CM_ SG_ 1283 VCU_EgyFbPwrLimPerc "Energy feedback power limit percentage";
CM_ SG_ 1283 VCU_MemChrgRmnMilgThd "Memory charging reminder mileage threshold";
CM_ SG_ 1283 VCU_FltAlrmCtrlSts "Fault alarm sound control state";
CM_ SG_ 1283 VCU_VehMaxAlrmLvl "Vehicle maximum alarm level";
CM_ SG_ 1283 VCU_BrkStrtReq "Please step on the brake to start";
CM_ SG_ 1283 VCU_PerKmFlg "Mark bit per km";
CM_ SG_ 1283 VCU_TrvlModSetRes "Travel mode setting result";
CM_ SG_ 1283 VCU_SlopCalcnVal "VCU slope calculation value";
CM_ SG_ 1283 VCU_InsntEgyCnseHr "Instantaneous energy consumption (hourly energy consumption)";
CM_ BO_ 1283 "IBUS2, cyclic every 100 ms, sent by GW";
CM_ SG_ 1284 VCU_MonrPwrBattThermRunawayAlrm "VCU monitoring power battery thermal runaway warning_P134C00_E03";
CM_ SG_ 1284 VCU_ShiftOperRmn "Gear shifting operation reminder";
CM_ SG_ 1284 VCU_MCUFOverSpdAlrm "Overspeed alarm of front drive motor";
CM_ SG_ 1284 VCU_MCUROverSpdAlrm "Overspeed alarm of rear drive motor";
CM_ SG_ 1284 VCU_MCUFSysOverTDisp "MCUF system overheating display";
CM_ SG_ 1284 VCU_MCURSysOverTDisp "MCUR system overheating display";
CM_ SG_ 1284 VCU_VehSysFltLamp "Vehicle system fault lamp";
CM_ SG_ 1284 VCU_MotSysFltLamp "Motor system fault lamp (landmark)";
CM_ SG_ 1284 VCU_RmnUsrClsECCDispCmd "Remind the user to turn off the A/C display instruction";
CM_ SG_ 1284 VCU_PPrkgFltLvl "Gear P fault level";
CM_ SG_ 1284 VCU_RmnUsrECCFctLmtDispCmd "Remind the user that the air conditioner function is limited to display instructions";
CM_ SG_ 1284 VCU_DrvgRngEPROMVal "Range EEPROM value";
CM_ SG_ 1284 VCU_DrvgMilg "Provide Remaining Driving Range";
CM_ SG_ 1284 VCU_DrvRngVld "Range effective";
CM_ SG_ 1284 VCU_EgyFlowLvl "Energy flow level";
CM_ SG_ 1284 VCU_VirtEgyRecovInten "Virtual energy recovery strength";
CM_ BO_ 1284 "IBUS2, cyclic every 100 ms, sent by GW";
CM_ SG_ 1285 VCU_SubtolEgyCnse "Subtotal energy consumption";
CM_ SG_ 1285 VCU_InsntEgyCnse "Instantaneous energy consumption";
CM_ SG_ 1285 VCU_AccueEgyCnse "Cumulative energy consumption";
CM_ SG_ 1285 VCU_EgyRecovForbnFlg "Energy recovery function prohibition flag position";
CM_ SG_ 1285 VCU_DrvPwrLimIndcrLamp "Driving power limit indicator";
CM_ SG_ 1285 VCU_PPrkgSysFltIndcn "Gear P parking system fault display";
CM_ SG_ 1285 VCU_GearSysFltIndcn "Gear system fault display";
CM_ SG_ 1285 VCU_SocLoRmn "Low battery reminder";
CM_ SG_ 1285 VCU_BattFltIndcn "Battery fault display";
CM_ SG_ 1285 VCU_ChrgIndcrLamp "Charging reminder and charging status indicator";
CM_ SG_ 1285 VCU_VehEgyFlow "Energy flow of vehicle working condition";
CM_ SG_ 1285 VCU_ChrgDchaGunCnctnIndcrLamp "Charge and discharge gun connection indicator";
CM_ SG_ 1285 VCU_InsntEgyCnseUnitSwtFlg "Instantaneous energy consumption unit switching flag bit";
CM_ SG_ 1285 VCU_ChrgGunStrt "Please pull the charging gun to start";
CM_ BO_ 1285 "IBUS2, cyclic every 100 ms, sent by GW";
CM_ SG_ 1292 VCU_DrvMotOutpPwrPerc "Percentage of output power of drive motor";
CM_ SG_ 1292 VCU_APS2Volt "Accelerator pedal 2 voltage value";
CM_ SG_ 1292 VCU_APS1Volt "Accelerator pedal 1 voltage value";
CM_ SG_ 1292 VCU_SlipRate "Slip rate";
CM_ SG_ 1292 VCU_DrvTqLimSts "Driving torque limit state";
CM_ SG_ 1292 VCU_EgyRecovTqLimSts "Energy recovery torque limit state";
CM_ BO_ 1292 "IBUS2, cyclic every 100 ms, sent by GW";
CM_ SG_ 1297 VCU_BMSLVWakeUpSts "BMS low-voltage wake-up state";
CM_ SG_ 1297 VCU_ONWakeUpSig "ON gear wake-up signal";
CM_ SG_ 1297 VCU_FCWakeUpSig "Fast charging wake-up signal";
CM_ SG_ 1297 VCU_SCWakeUpSig "Slow charging wake-up signal";
CM_ SG_ 1297 VCU_RemWakeUpSig "Remote wake-up signal";
CM_ SG_ 1297 VCU_NetWakeUpSig "Network wake-up signal";
CM_ SG_ 1297 VCU_LVWakeUpSts_PDU "Low-voltage wake-up state of PDU";
CM_ SG_ 1297 VCU_VehEOLFctFlg "Vehicle EOL function flag position";
CM_ SG_ 1297 VCU_LVWakeUpSts_MCU "MCU low-voltage wake-up state";
CM_ SG_ 1297 VCU_PwrAntithefAllwtRdyFlg "Power anti-theft allowable READY flag position";
CM_ SG_ 1297 VCU_LVWakeUpSts_CCU "CCU low-voltage wake-up state";
CM_ SG_ 1297 VCU_RemECCEndCmd "Remote A/C end instruction";
CM_ SG_ 1297 VCU_EvChrgElectcLockCtrlCmd "EV charge inlet electronic lock command";
CM_ SG_ 1297 VCU_RemPwrBattHeatgEndCmd "Remote traction battery heating end command";
CM_ SG_ 1297 VCU_RemChrgEndCmd "Remote charging end command";
CM_ SG_ 1297 VCU_V2L_TrAvl "V2L Trunk Available from VCU";
CM_ SG_ 1297 VCU_RemBattHeatgFailReason "Failure reason of remote battery heating";
CM_ SG_ 1297 VCU_RemECCEndReason "End reason of remote A/C";
CM_ SG_ 1297 VCU_V2L_ChrgPortAvl "V2L Charge Port Available";
CM_ SG_ 1297 VCU_RemChrgEndReason "End reason of remote charging";
CM_ SG_ 1297 VCU_SchedChrgnStsFb "VCU Feedback the scheduled Charging progress/status to TBOX";
CM_ SG_ 1297 VCU_V2V_Avl "VCU_V2VAvailable";
CM_ SG_ 1297 VCU_V2H_Avl "VCU_V2HAvailable";
CM_ SG_ 1297 VCU_V2G_Avl "VCU_V2GAvailable";
CM_ SG_ 1297 VCU_VehMod "Vehicle mode";
CM_ SG_ 1297 VCU_VehCrtChrgEndSOC "Vehicle current charging cutoff SOC value";
CM_ SG_ 1297 VCU_CalSwVers "VCU calibration software version number";
CM_ SG_ 1297 VCU_RemPwrBattPreheatgEndFlg "The remote traction battery preheating end flag";
CM_ SG_ 1297 VCU_VehOperMod "Vehicle operation condition";
CM_ SG_ 1297 VCU_VehRemRefrshModReq "Vehicle remote flashing mode requirements";
CM_ SG_ 1297 VCU_RemDTCPwrOnReq "Remote diagnosis of power-on demand";
CM_ BO_ 1297 "IBUS2, cyclic every 100 ms, sent by GW";
CM_ SG_ 1312 DCDC_0x520_CheckSum "DCDC_0x520_Message Check (E2E data ID: 0x31 )";
CM_ SG_ 1312 DCDC_0x520_AliveCounter "DCDC_0x520 message counter";
CM_ SG_ 1312 DCDC_OutpCrt "DCDC output current";
CM_ SG_ 1312 DCDC_InpVolt "DCDC input voltage";
CM_ SG_ 1312 DCDC_InpCrt "DCDC input current";
CM_ SG_ 1312 DCDC_OutpVolt "DCDC output voltage";
CM_ BO_ 1312 "IBUS2, cyclic every 100 ms, sent by GW";
CM_ SG_ 1317 TBOX_525_CheckSum "TBOX_525_Message checksum (0xF9)TBOX_525_CheckSum";
CM_ SG_ 1317 TBOX_525_AliveCounter "TBOX_525_Message CounterTBOX_525_AliveCounterr";
CM_ SG_ 1317 TBOX_GPSHei "Altitude Height";
CM_ BO_ 1317 "IBUS2, cyclic every 100 ms, sent by GW";
CM_ SG_ 1318 TBOX_GPSLongi "Longitude (the east longitude is positive and the west longitude is negative.)Longitude";
CM_ SG_ 1318 TBOX_GPSLati "Latitude (north is positive and south is negative.)Latitude";
CM_ BO_ 1318 "IBUS2, cyclic every 100 ms, sent by GW";
CM_ SG_ 1319 ADAS_DrvrAttention_Zone "Signal to the vehicle indicating where the driver's attention is centered";
CM_ SG_ 1319 ADAS_DrvrAlert_State "Whether or not the IR LED is blocked";
CM_ SG_ 1319 ADAS_DMS_Camera_Blockage_Status "Signal to the vehicle indicating whether or not the driver is alert";
CM_ SG_ 1319 ADAS_DrvrEngagement_Level_Status "Engagement level of driver";
CM_ SG_ 1319 ADAS_DMS_IR_Blockage_Status "Whether or not the camera is blocked";
CM_ SG_ 1319 ADAS_DrvrEngagement_Level_Conf "Confidence of engagement level";
CM_ SG_ 1319 ADAS_DrvrImpairment_Level_Stat "Impairment level of driver";
CM_ SG_ 1319 ADAS_DrvrImpairment_Level_Conf "confidence of impairment level";
CM_ SG_ 1319 ADAS_DrvrDrowsiness_Level "Drowsiness level of driver";
CM_ SG_ 1319 ADAS_DCAA_DrvrDrowsinessVld "Driver Drowsiness level of confidence";
CM_ SG_ 1319 ADAS_DCAA_DrvrAttentionLvl "Driver level of Attention (no reference yet)";
CM_ SG_ 1319 ADAS_DCAA_DrvrAttentionVld "Driver level of attention confidence (no reference yet)";
CM_ SG_ 1319 ADAS_DCAA_DrvrDrowsinessLvl "Driver Drowsiness level based on Karolinska Scale";
CM_ SG_ 1319 ADAS_DMSDrvrDetn "DMS drivier detection";
CM_ SG_ 1319 ADAS_DMS_IRSts "DMS IR status";
CM_ SG_ 1319 ADAS_DCAA_FrameIndex "DCAA frame Index";
CM_ BO_ 1319 "IBUS2, cyclic every 100 ms, sent by GW";
CM_ SG_ 1322 ICC_0x52A_CheckSum "ICC_0x52A_CheckSum (E2E Data ID: 0xF5)";
CM_ SG_ 1322 ICC_0x52A_AliveCounter "ICC_0x52A_AliveCounter";
CM_ SG_ 1322 ICC_FACM_DynmcSenstvty "This signal indicates if dynamic sensitivity is enabled by user";
CM_ SG_ 1322 ICC_UsrProfTiGapSet "Automatic Cruise Control (ACC) Time Gap Setting from ICC user profile";
CM_ SG_ 1322 ICC_LKA_Setting "RCTA Alert Type";
CM_ SG_ 1322 ICC_FACM_Setting "FACM setting";
CM_ SG_ 1322 ICC_AEB_Sensitivity "AEB Time Sensitivity Setting";
CM_ SG_ 1322 ICC_BACM_Setting "BACM (Rear AEB and RCTB) On and Off";
CM_ SG_ 1322 ICC_BACM_Sensitivity "BACM (Rear AEB and RCTB) Time Sensitivity Setting";
CM_ SG_ 1322 ICC_AEB_JerkSetReq "Enabling/disabling the AEB jerk by the driver";
CM_ SG_ 1322 ICC_ActvStyGlblSetting "Global setting to turn off all active safety features: AEB (forward and backward), LKA, ELKA, ESA";
CM_ SG_ 1322 ICC_TSR_Setting "To turn On and Off TSR feature settings";
CM_ SG_ 1322 ICC_ESA_Setting "To turn On and Off ESA feature settings";
CM_ SG_ 1322 ICC_ELKASteeringInterventionSet "ELKA Steering intervention on/off";
CM_ SG_ 1322 ICC_LaneTrajectorySetting "Turn the LCA trajectory display on or off";
CM_ SG_ 1322 ICC_ACCAutoSpdSts "ACC Auto Speed setting";
CM_ SG_ 1322 ICC_ACCSpdStepSize "Automatic Cruise Control (ACC) Speed setting step size";
CM_ SG_ 1322 ICC_ACCFuncTyp "Automatic Cruise Control (ACC) function type";
CM_ SG_ 1322 ICC_ACCSpdLimOffs "Automatic Cruise Control (ACC) speed limit offset value (percentage)";
CM_ SG_ 1322 ICC_ACCSpdLimOffsTyp "Automatic Cruise Control (ACC) speed limit offset type";
CM_ SG_ 1322 ICC_ACCTerrainSetting "Automatic Cruise Control (ACC) terrain setting";
CM_ SG_ 1322 ICC_ACCTiGapCfm "Automatic Cruise Control (ACC) Time Gap confirmation by driver";
CM_ SG_ 1322 ICC_ISASetting "ISA settings";
CM_ SG_ 1322 ICC_FCTA_Sensitivity "FCTA Sensitivity";
CM_ SG_ 1322 ICC_TLR_Setting "To turn On and Off TLR feature settings";
CM_ SG_ 1322 ICC_FCTA_Setting "FCTA Setting";
CM_ BO_ 1322 "IBUS2, CE every 200 ms, sent by ICC";
CM_ SG_ 1337 BCM_539_CheckSum "BCM_539_Message checksum (0x8D)BCM_539_CheckSum";
CM_ SG_ 1337 BCM_539_AliveCounter "BCM_539_Message counterBCM_539_AliveCounter";
CM_ SG_ 1337 BCM_LePosnLampFlt "Left position lamp fault";
CM_ SG_ 1337 BCM_RiPosnLampFlt "Right position lamp fault";
CM_ SG_ 1337 BCM_LeLoBeamFlt "Left low beam fault";
CM_ SG_ 1337 BCM_RiLoBeamFlt "Right low beam fault";
CM_ SG_ 1337 BCM_LeHiBeamFlt "Left high beam fault";
CM_ SG_ 1337 BCM_RiHiBeamFlt "Right high beam fault";
CM_ SG_ 1337 BCM_LeDRLFlt "Left daytime running lamp fault";
CM_ SG_ 1337 BCM_RiDRLFlt "Right daytime running lamp fault";
CM_ SG_ 1337 BCM_LeFrntFogLampFlt "Left front fog lamp fault";
CM_ SG_ 1337 BCM_RiFrntFogLampFlt "Right front fog lamp fault";
CM_ SG_ 1337 BCM_ReFogLampFlt "Rear fog lamp fault";
CM_ SG_ 1337 BCM_LoBrkLampFlt "Low stop lamp fault";
CM_ SG_ 1337 BCM_HiBrkLampFlt "High mounted stop lamp fault";
CM_ SG_ 1337 BCM_RvsLampFlt "Reversing lamp fault";
CM_ SG_ 1337 BCM_LeTurnLampFlt "Left turn signal lamp fault";
CM_ SG_ 1337 BCM_RiTurnLampFlt "Right turn signal lamp fault";
CM_ SG_ 1337 BCM_LicPlateLampFlt "License plate lamp fault";
CM_ SG_ 1337 BCM_ElWiperMotorFlt "electric wiper motor fault";
CM_ BO_ 1337 "IBUS2, cyclic every 100 ms, sent by GW";
CM_ SG_ 1408 VCU_ActChrgTotAh "Total Ah of actual charging on this power-on";
CM_ SG_ 1408 VCU_ActDchgTotAh "Total Ah of actual discharge on this power-on";
CM_ SG_ 1408 VCU_DCChrgRmngTi "DC charging remaining charging time";
CM_ SG_ 1408 VCU_PwrBattAvlEgy "Power battery available energy";
CM_ BO_ 1408 "IBUS2, cyclic every 250 ms, sent by GW";
CM_ SG_ 1410 ECC_InsdT "Inside temperature";
CM_ SG_ 1410 ECC_RemPwrCnsEstim "Remote power consumption estimation";
CM_ SG_ 1410 ECC_RemTSetSts "Remote temperature setting state";
CM_ SG_ 1410 ECC_RemDefrstSts "Remote defrosting working state";
CM_ SG_ 1410 ECC_BattFldLvlSnsrLamp "battery fluid level sensor warning lamp";
CM_ SG_ 1410 ECC_ResvOperTi "Reservation of A/C working time";
CM_ SG_ 1410 ECC_ParticleConc "Particulate concentration";
CM_ BO_ 1410 "IBUS2, cyclic every 100 ms, sent by GW";
CM_ SG_ 1419 VCU_HVEgyCnsMovg "Actual energy consumption Wh per km while moving, FB311";
CM_ SG_ 1419 VCU_HVEgyCnsStandstill "Actual energy consumption Wh while in standstill, FB311";
CM_ SG_ 1419 VCU_HVEgyCnsAverage "Average energy consumption history of HV battery of the last 100km, FB311.";
CM_ SG_ 1419 VCU_HVCustSOC "Provide HV customer SOC, FB314";
CM_ BO_ 1419 "IBUS2, cyclic every 1000 ms, sent by GW";
CM_ SG_ 1422 VCU_EgyCnsHist01 "The energy consumption history-01 of HV battery";
CM_ SG_ 1422 VCU_EgyCnsHist02 "The energy consumption history-02 of HV battery";
CM_ SG_ 1422 VCU_EgyCnsHist03 "The energy consumption history-03 of HV battery";
CM_ SG_ 1422 VCU_EgyCnsHist04 "The energy consumption history-04 of HV battery";
CM_ BO_ 1422 "IBUS2, cyclic every 1000 ms, sent by GW";
CM_ SG_ 1425 VCU_EgyCnsHist05 "The energy consumption history-05 of HV battery";
CM_ SG_ 1425 VCU_EgyCnsHist06 "The energy consumption history-06 of HV battery";
CM_ SG_ 1425 VCU_EgyCnsHist07 "The energy consumption history-07 of HV battery";
CM_ SG_ 1425 VCU_EgyCnsHist08 "The energy consumption history-08 of HV battery";
CM_ BO_ 1425 "IBUS2, cyclic every 1000 ms, sent by GW";
CM_ SG_ 1432 VCU_EgyCnsHist09 "The energy consumption history-09 of HV battery";
CM_ SG_ 1432 VCU_EgyCnsHist10 "The energy consumption history-10 of HV battery";
CM_ BO_ 1432 "IBUS2, cyclic every 1000 ms, sent by GW";
CM_ SG_ 1436 VCU_LowMilg_Warn "Provide Warning Low range information, FB321";
CM_ SG_ 1436 VCU_LowMilgRemAlrm "Provide acoustic signal (Single acoustic signal in case of low driving range remaining), FB323";
CM_ SG_ 1436 VCU_MilgChrg_add "added driving range through charging, FB319";
CM_ SG_ 1436 VCU_MilgChrgRate_add "Charging milage rate of actual charging process, FB319";
CM_ BO_ 1436 "IBUS2, cyclic every 500 ms, sent by GW";
CM_ SG_ 1444 VCU_HVEM_PwrCoorrPrio "Provide priority of power coordinator, FB381";
CM_ SG_ 1444 VCU_ChrgPwrLim "Provide Charge power limit (due to component temperatures), FB381";
CM_ SG_ 1444 VCU_P_ECC_unfiltered "Provide Max power reserved for ECC(unfiltered), FB380";
CM_ SG_ 1444 VCU_P_Prop_filt "Provide Max power reserved for Propulsion(filtered), FB382";
CM_ BO_ 1444 "IBUS2, cyclic every 100 ms, sent by GW";
CM_ SG_ 1554 ICC_NavGuidanceInfo "Navigation guidance information";
CM_ SG_ 1554 ICC_NavDstInfo "Navigation distance information";
CM_ BO_ 1554 "IBUS2, cyclic every 1000 ms, sent by ICC";
CM_ SG_ 1555 ICC_ResvTrvlStrtSet "Central control reservation opening setting";
CM_ BO_ 1555 "IBUS2, cyclic every 1000 ms, sent by ICC";
CM_ SG_ 1556 ICC_ResvACChrgStrtTi_Hr "Central control reserved AC charging on time (hour)";
CM_ SG_ 1556 ICC_ResvACChrgStrtTi_Mins "Central control reserved AC charging on time (minute)";
CM_ SG_ 1556 ICC_ResvACChrgStrtSet "Central control setting for AC charging setting";
CM_ SG_ 1556 ICC_MonResvACChrgRepStrtSet "Reserved on Monday AC charging repeat on setting";
CM_ SG_ 1556 ICC_TueResvACChrgRepStrtSet "Fixed AC charging on Tuesday";
CM_ SG_ 1556 ICC_WedResvACChrgRepStrtSet "Wednesday reservation AC charging repeat on setting";
CM_ SG_ 1556 ICC_ThuResvACChrgRepStrtSet "Reserve AC charging on Thursday";
CM_ SG_ 1556 ICC_FriResvACChrgRepStrtSet "Reserved AC charging on Friday";
CM_ SG_ 1556 ICC_SatResvACChrgRepStrtSet "Reserved AC charging on Saturday";
CM_ SG_ 1556 ICC_SunResvACChrgRepStrtSet "Sunday reservation AC charging repeat on setting";
CM_ SG_ 1556 ICC_ResvACChrgEndTi_Hr "Central control reserved AC charging end time (time)";
CM_ SG_ 1556 ICC_ResvACChrgEndTi_Mins "Central control reserved AC charging end time (minute)";
CM_ SG_ 1556 ICC_ResvACChrgEndSet "Central control setting for setting AC charging end";
CM_ SG_ 1556 ICC_MonResvACChrgRepEndSet "Reserved on Monday AC charging repetition end setting";
CM_ SG_ 1556 ICC_TueResvACChrgRepEndSet "Reserved on Tuesday AC charging repetition end setting";
CM_ SG_ 1556 ICC_WedResvACChrgRepEndSet "Reserved on Wednesday AC charging repetition end setting";
CM_ SG_ 1556 ICC_ThuResvACChrgRepEndSet "Reserved on Thursday AC charging repeat end setting";
CM_ SG_ 1556 ICC_FriResvACChrgRepEndSet "Reserved on Friday AC charging repeat end setting";
CM_ SG_ 1556 ICC_SatResvACChrgRepEndSet "Reserved AC charging repetition end setting on Saturday";
CM_ SG_ 1556 ICC_SunResvACChrgRepEndSet "Sunday reservation AC charging repetition end setting";
CM_ BO_ 1556 "IBUS2, cyclic every 1000 ms, sent by ICC";
CM_ SG_ 1581 TBOX_ResvTrvlStrtSts "TBOX reservation opening state";
CM_ BO_ 1581 "IBUS2, cyclic every 1000 ms, sent by GW";
CM_ SG_ 1582 TBOX_ResvACChrgStrtTi_Hr "TBOX reservation AC charging ON time (hour)";
CM_ SG_ 1582 TBOX_ResvACChrgStrtTi_Mins "TBOX reservation AC charging ON time (minute)";
CM_ SG_ 1582 TBOX_MonResvACChrgRepStrtSet "Reserved AC charging on Monday";
CM_ SG_ 1582 TBOX_TueResvACChrgRepStrtSet "Reserved on Tuesday AC charging repeat on state";
CM_ SG_ 1582 TBOX_WedResvACChrgRepStrtSet "Wednesday reservation AC charging repeat on state";
CM_ SG_ 1582 TBOX_ThuResvACChrgRepStrtSet "Reservation on AC charging on Thursday";
CM_ SG_ 1582 TBOX_FriResvACChrgRepStrtSet "Reserved AC charging on Friday";
CM_ SG_ 1582 TBOX_SatResvACChrgRepStrtSet "Reserved AC charging on Saturday";
CM_ SG_ 1582 TBOX_SunResvACChrgRepStrtSet "Sun reservation AC charging repeat on state";
CM_ SG_ 1582 TBOX_ResvACChrgEndTi_Hr "TBOX Reserved AC charging end time (hour)";
CM_ SG_ 1582 TBOX_ResvACChrgEndTi_Mins "TBOX Reserved AC charging end time (minute)";
CM_ SG_ 1582 TBOX_ResvACChrgEndSet "TBOX Reserved AC charging end state";
CM_ SG_ 1582 TBOX_MonResvACChrgRepEndSet "Reserved AC charging repeat ending state on Monday";
CM_ SG_ 1582 TBOX_TueResvACChrgRepEndSet "Reserved on Tuesday AC charging repeat ending state";
CM_ SG_ 1582 TBOX_WedResvACChrgRepEndSet "Wednesday reservation AC charging repeat ending state";
CM_ SG_ 1582 TBOX_ThuResvACChrgRepEndSet "Reserved on Thursday AC charging repeat ending state";
CM_ SG_ 1582 TBOX_FriResvACChrgRepEndSet "Reserved AC charging repeat ending state on Friday";
CM_ SG_ 1582 TBOX_SatResvACChrgRepEndSet "Reserved AC charging repetition ending state on Saturday";
CM_ SG_ 1582 TBOX_SunResvACChrgRepEndSet "Sun reservation AC charging repeat ending state";
CM_ BO_ 1582 "IBUS2, cyclic every 1000 ms, sent by GW";
CM_ SG_ 1584 VCU_CellTotVolt "Total voltage of monomer accumulation";
CM_ SG_ 1584 VCU_CellMinVolt "Minimum voltage of single cell";
CM_ SG_ 1584 VCU_CellMaxVolt "Maximum voltage of single cell";
CM_ SG_ 1584 VCU_ACRmngChrgTi "AC charging remaining charging time";
CM_ BO_ 1584 "IBUS2, cyclic every 1000 ms, sent by GW";
CM_ SG_ 1588 VCU_ACChrgShttrSts "AC charge and discharge port door state";
CM_ SG_ 1588 VCU_DCChrgShttrSts "State of DC charging port door panel";
CM_ SG_ 1588 VCU_SCPwrSplyEquipFactry "Slow charging power supply equipment manufacturer";
CM_ SG_ 1588 VCU_ACChrgCrtUpprLmt "AC charging current upper limit";
CM_ BO_ 1588 "IBUS2, cyclic every 1000 ms, sent by GW";
CM_ SG_ 1601 BCM_MilgDataVld_ODO "Mileage effective signal_BCM";
CM_ SG_ 1601 BCM_MilgRstCntr_ODO "Mileage Zero_BCM";
CM_ SG_ 1601 BCM_TotMilg_ODO "BCM total mileage";
CM_ SG_ 1601 BCM_MilgOffs_ODO "Mileage offset_BCM";
CM_ BO_ 1601 "IBUS2, cyclic every 1000 ms, sent by GW";
CM_ SG_ 1604 ECC_644_CheckSum "ECC_644_Message checksum (E2E data ID: 0x14)";
CM_ SG_ 1604 ECC_644_AliveCounter "ECC_644_Message Counter";
CM_ SG_ 1604 ECC_ReMotOutlT "Rear motor outlet water temperature";
CM_ SG_ 1604 ECC_CoolgDfct "ECC HVB Thermal status:cooling defect";
CM_ SG_ 1604 ECC_CooltHomSts "?Coolant homogenisation status";
CM_ SG_ 1604 ECC_PDUInlT "Water temperature at PDU inlet";
CM_ SG_ 1604 ECC_FrntMotOutlT "Water temperature at front motor outlet";
CM_ SG_ 1604 ECC_MCURInlT "MCU_R inlet temperature";
CM_ BO_ 1604 "IBUS2, cyclic every 1000 ms, sent by GW";
CM_ SG_ 1605 ECC_DefrstAirOutlTSnsrFlt "Defrosting air outlet temperature sensor faulty_P16A01C_E00";
CM_ SG_ 1605 ECC_ComLost_EAS "Loss of communication between ECC and EAS faila_U016487_E00";
CM_ SG_ 1605 ECC_OutdTSnsrFlt "External ambient temperature sensor faulty_P16821C_E00";
CM_ SG_ 1605 ECC_InsdTSnsrFlt "ECC interior temperature sensor fault_P16831C_E00";
CM_ SG_ 1605 ECC_EvaprTSnsrFlt "Evaporation temperature sensor faulty_P16841C_E00";
CM_ SG_ 1605 ECC_IntExtCircMotFlt "Internal and external circulation motor fault";
CM_ SG_ 1605 ECC_LeModThrMotFlt "Left mode damper motor fault";
CM_ SG_ 1605 ECC_RiModThrMotFlt "Right mode damper motor fault";
CM_ SG_ 1605 ECC_CtrlrFlt "ECC controller fault";
CM_ SG_ 1605 ECC_PDUInlTSnsrFlt "PDU inlet temperature sensor fault";
CM_ SG_ 1605 ECC_FrntMotOutlTSnsrFlt "Water temperature sensor at front motor outlet";
CM_ SG_ 1605 ECC_ReMotOutlTSnsrFlt "Rear motor outlet water temperature sensor fault";
CM_ SG_ 1605 ECC_ComLost_CDS "Loss of communication between ECC and CDS";
CM_ SG_ 1605 ECC_ComLost_WTC_H "Lost communication between ECC and WTC_H";
CM_ SG_ 1605 ECC_ComLost_WTC_B "Loss of ECC and WTC_B communication";
CM_ SG_ 1605 ECC_HPTSnsrFlt "High pressure temperature sensor fault";
CM_ SG_ 1605 ECC_LPTSnsrFlt "Low pressure temperature sensor fault";
CM_ SG_ 1605 ECC_BlowFaceLeAirOutlTSnsrFlt "Face-blowing left air outlet temperature sensor failure";
CM_ SG_ 1605 ECC_BlowFaceRiAirOutlTSnsrFlt "Face-blowing right air outlet temperature sensor failure";
CM_ SG_ 1605 ECC_ReBlowFaceFootMotFlt "Rear face blowing foot blowing motor failure";
CM_ SG_ 1605 ECC_HPSnsrFlt "High pressure sensor fault";
CM_ SG_ 1605 ECC_LPSnsrFlt "Low pressure sensor fault";
CM_ SG_ 1605 ECC_HeatPmpHeatgEXVFlt "Failure of electronic expansion valve for heat pump heating";
CM_ SG_ 1605 ECC_BattCoolgEXVFlt "Battery cooling electronic expansion valve fault";
CM_ SG_ 1605 ECC_BlowFootLeAirOutlTSnsrFlt "Foot blowing air outlet temperature sensor LH failure";
CM_ SG_ 1605 ECC_BlowFootRiAirOutlTSnsrFlt "Foot blowing right air outlet temperature sensor failure";
CM_ SG_ 1605 ECC_LeHybThrMotFlt "Left blend damper motor fault";
CM_ SG_ 1605 ECC_RiHybThrMotFlt "Right blend damper motor fault";
CM_ SG_ 1605 ECC_MCURInlTSnsrFlt "MCU_R inlet temperature sensor fault";
CM_ SG_ 1605 ECC_ComLost_EWP_FD "Lost communication between ECC and EWP_FD";
CM_ SG_ 1605 ECC_ComLost_EWP_RD "Lost communication between ECC and EWP_RD";
CM_ SG_ 1605 ECC_ComLost_EWP_H "Lost communication between ECC and EPP-H";
CM_ SG_ 1605 ECC_ComLost_EWP_B "Lost communication between ECC and EWP_B";
CM_ SG_ 1605 ECC_ComLost_EXV_B "Lost ECC and EXV_B communication";
CM_ SG_ 1605 ECC_ComLost_EXV_H "Lost ECC and EXV_H communication";
CM_ SG_ 1605 ECC_ComLost_CFM "ECC and CFM communication loss";
CM_ SG_ 1605 ECC_ComLost_AGS "Lost communication between ECC and AGS";
CM_ SG_ 1605 ECC_ComLost_CVM "ECC and CVM communication loss";
CM_ SG_ 1605 ECC_ComLost_MDV "Lost communication between ECC and MDV";
CM_ BO_ 1605 "IBUS2, cyclic every 1000 ms, sent by GW";
CM_ SG_ 1650 ICC_SwVersS "ICC software version number";
CM_ SG_ 1650 ICC_PartVers "ICC part number";
CM_ SG_ 1650 ICC_HwVers "ICC hardware version number";
CM_ SG_ 1650 ICC_SwVersM "ICC main software version number";
CM_ BO_ 1650 "IBUS2, cyclic every 1000 ms, sent by ICC";
CM_ SG_ 1698 VCU_SCChrgCnt "Statistics of slow charging times";
CM_ SG_ 1698 VCU_VehHVPwrOffTi "Static time of the vehicle when the high voltage is off (30 frames continuously after entering state 12/82/142)";
CM_ SG_ 1698 VCU_FCChrgCnt "Statistics of fast charging times";
CM_ BO_ 1698 "IBUS2, cyclic every 2000 ms, sent by GW";
CM_ SG_ 1765 VCU_VINCod1 "VIN number 1 (indicating 1 to 8 ASC values in the number)VCUVINCode_1(Bit1~8ofASCII)";
CM_ BO_ 1765 "IBUS2, cyclic every 5000 ms, sent by GW";
CM_ SG_ 1766 VCU_VINCod2 "VIN number 2 (indicating 9 to 16 ASC values in the number)VCUVINCode_2(Bit9~16ofASCII)";
CM_ BO_ 1766 "IBUS2, cyclic every 5000 ms, sent by GW";
CM_ SG_ 1767 VCU_VINCod3 "VIN number 3 (indicating 17 to 24 ASC values in number)VCUVINCode_3(Bit17~24ofASCII)";
CM_ BO_ 1767 "IBUS2, cyclic every 5000 ms, sent by GW";

BA_DEF_ BO_ "GenMsgCycleTime" INT 0 65535;
BA_DEF_DEF_ "GenMsgCycleTime" 0;
BA_ "GenMsgCycleTime" BO_ 791 50;
BA_ "GenMsgCycleTime" BO_ 794 50;
BA_ "GenMsgCycleTime" BO_ 795 50;
BA_ "GenMsgCycleTime" BO_ 796 50;
BA_ "GenMsgCycleTime" BO_ 800 50;
BA_ "GenMsgCycleTime" BO_ 801 50;
BA_ "GenMsgCycleTime" BO_ 811 40;
BA_ "GenMsgCycleTime" BO_ 813 40;
BA_ "GenMsgCycleTime" BO_ 815 40;
BA_ "GenMsgCycleTime" BO_ 818 50;
BA_ "GenMsgCycleTime" BO_ 820 50;
BA_ "GenMsgCycleTime" BO_ 825 50;
BA_ "GenMsgCycleTime" BO_ 827 40;
BA_ "GenMsgCycleTime" BO_ 829 40;
BA_ "GenMsgCycleTime" BO_ 831 40;
BA_ "GenMsgCycleTime" BO_ 832 50;
BA_ "GenMsgCycleTime" BO_ 834 50;
BA_ "GenMsgCycleTime" BO_ 836 50;
BA_ "GenMsgCycleTime" BO_ 837 50;
BA_ "GenMsgCycleTime" BO_ 841 50;
BA_ "GenMsgCycleTime" BO_ 843 40;
BA_ "GenMsgCycleTime" BO_ 845 40;
BA_ "GenMsgCycleTime" BO_ 847 40;
BA_ "GenMsgCycleTime" BO_ 848 100;
BA_ "GenMsgCycleTime" BO_ 849 100;
BA_ "GenMsgCycleTime" BO_ 850 100;
BA_ "GenMsgCycleTime" BO_ 851 100;
BA_ "GenMsgCycleTime" BO_ 854 100;
BA_ "GenMsgCycleTime" BO_ 855 100;
BA_ "GenMsgCycleTime" BO_ 857 100;
BA_ "GenMsgCycleTime" BO_ 859 200;
BA_ "GenMsgCycleTime" BO_ 865 100;
BA_ "GenMsgCycleTime" BO_ 866 100;
BA_ "GenMsgCycleTime" BO_ 867 100;
BA_ "GenMsgCycleTime" BO_ 873 100;
BA_ "GenMsgCycleTime" BO_ 875 100;
BA_ "GenMsgCycleTime" BO_ 885 100;
BA_ "GenMsgCycleTime" BO_ 886 100;
BA_ "GenMsgCycleTime" BO_ 887 100;
BA_ "GenMsgCycleTime" BO_ 889 100;
BA_ "GenMsgCycleTime" BO_ 896 100;
BA_ "GenMsgCycleTime" BO_ 901 100;
BA_ "GenMsgCycleTime" BO_ 923 100;
BA_ "GenMsgCycleTime" BO_ 1136 100;
BA_ "GenMsgCycleTime" BO_ 1169 100;
BA_ "GenMsgCycleTime" BO_ 1283 100;
BA_ "GenMsgCycleTime" BO_ 1284 100;
BA_ "GenMsgCycleTime" BO_ 1285 100;
BA_ "GenMsgCycleTime" BO_ 1292 100;
BA_ "GenMsgCycleTime" BO_ 1297 100;
BA_ "GenMsgCycleTime" BO_ 1312 100;
BA_ "GenMsgCycleTime" BO_ 1317 100;
BA_ "GenMsgCycleTime" BO_ 1318 100;
BA_ "GenMsgCycleTime" BO_ 1319 100;
BA_ "GenMsgCycleTime" BO_ 1322 200;
BA_ "GenMsgCycleTime" BO_ 1337 100;
BA_ "GenMsgCycleTime" BO_ 1408 250;
BA_ "GenMsgCycleTime" BO_ 1410 100;
BA_ "GenMsgCycleTime" BO_ 1419 1000;
BA_ "GenMsgCycleTime" BO_ 1422 1000;
BA_ "GenMsgCycleTime" BO_ 1425 1000;
BA_ "GenMsgCycleTime" BO_ 1432 1000;
BA_ "GenMsgCycleTime" BO_ 1436 500;
BA_ "GenMsgCycleTime" BO_ 1444 100;
BA_ "GenMsgCycleTime" BO_ 1554 1000;
BA_ "GenMsgCycleTime" BO_ 1555 1000;
BA_ "GenMsgCycleTime" BO_ 1556 1000;
BA_ "GenMsgCycleTime" BO_ 1581 1000;
BA_ "GenMsgCycleTime" BO_ 1582 1000;
BA_ "GenMsgCycleTime" BO_ 1584 1000;
BA_ "GenMsgCycleTime" BO_ 1588 1000;
BA_ "GenMsgCycleTime" BO_ 1601 1000;
BA_ "GenMsgCycleTime" BO_ 1604 1000;
BA_ "GenMsgCycleTime" BO_ 1605 1000;
BA_ "GenMsgCycleTime" BO_ 1650 1000;
BA_ "GenMsgCycleTime" BO_ 1698 2000;
BA_ "GenMsgCycleTime" BO_ 1765 5000;
BA_ "GenMsgCycleTime" BO_ 1766 5000;
BA_ "GenMsgCycleTime" BO_ 1767 5000;
VAL_ 791 ADAS_LeMirrWarnSrc 0 "Not_Active" 1 "BSD" 2 "DOW" 3 "ELKA" ;
VAL_ 791 ADAS_LeMirrWarnReq 0 "Not_Active" 1 "Active_warning_1" 2 "Active_warning_2" 3 "Reserved" ;
VAL_ 791 ADAS_ChimeReq 0 "No_chime" 1 "Engagement" 2 "Disengagement" 3 "Fault_chime" 4 "Warning_light_amber" 5 "Warning_light_yellow" 6 "Warning_light_red" 7 "Overspeed" 8 "Cant_do_that" 9 "Parking_complete" 10 "Zone2" 11 "Zone3" 12 "Zone1" ;
VAL_ 791 ADAS_IDS_WarnTxtReq 0 "No_request" 1 "Minor_fault_detected" 2 "Front_camera_fault" 3 "Radar_fault" 4 "Ultrasonic_sensor_fault" 5 "AEB_fault" 6 "Lane_keeping_system_fault" 7 "ACC_fault" 8 "Surround_view_system_fault" 9 "Driver_monitor_system_fault" 10 "TJA/ICA_fault" 11 "Other_critical_fault" 12 "Evasive_steering_assist_fault" 13 "BSM_ELKA_System_fault" 14 "Lane_Change_Assist_Fault" 21 "AEB_off_/_degraded" 22 "Lane_keeping_system_off_/_degraded" 23 "DCAA_warning_stage_1" 24 "DCAA_warning_stage_2" 25 "DCAA_warning_stage_3" 26 "Hands_on_reminder_/_urgent" 27 "Pay_attention_to_drive_/_gentle" 28 "Pay_attention_to_drive_/_firm" 29 "Pay_attention_to_drive_/_urgent" 30 "Door_opening_traffic_warning" 31 "Door_opening_collision_warning" 32 "AEB_pre-warning" 33 "AEB_acute_warning" 34 "AEB_intervene_(including_brake_jerk)" ;
VAL_ 791 ADAS_RiMirrWarnReq 0 "Not_Active" 1 "Active_warning_1" 2 "Active_warning_2" 3 "Reserved" ;
VAL_ 791 ADAS_IDS_LeWarnReq 0 "Not_Active" 1 "Active_warning_1_Yellow" 2 "Active_warning_2_Yellow_Blinking" 3 "Active_warning_3_Red" 4 "Active_warning_4_Red_Blinking" ;
VAL_ 791 ADAS_IDS_RiWarnReq 0 "Not_Active" 1 "Active_warning_1_Yellow" 2 "Active_warning_2_Yellow_Blinking" 3 "Active_warning_3_Red" 4 "Active_warning_4_Red_Blinking" ;
VAL_ 791 ADAS_IDS_LeWarnSrc 0 "Not_Active" 1 "BSD" 2 "DOW" 3 "ELKA" ;
VAL_ 791 ADAS_IDS_RiWarnSrc 0 "Not_Active" 1 "BSD" 2 "DOW" 3 "ELKA" ;
VAL_ 791 ADAS_SysFltWarnReq 0 "ADAS_Normal" 1 "ADAS_Flt" 2 "ADAS_FltCrtcl" 3 "Reserved" ;
VAL_ 791 ADAS_SysFltTyp 0 "No_fault" 1 "Minor_fault_detected" 2 "Front_camera_fault" 3 "Radar_fault" 4 "Ultrasonic_sensor_fault" 5 "AEB_fault" 6 "Lane_keeping_system_fault" 7 "ACC_fault" 8 "Surround_view_system_fault" 9 "Driver_monitoring_system_fault" 10 "TJA_ICA_fault" 11 "Other_critical_fault" 12 "Blind_spot_monitor_fault" 13 "Evasive_steering_assist_fault" ;
VAL_ 791 ADAS_RiMirrWarnSrc 0 "Not_Active" 1 "BSD" 2 "DOW" 3 "ELKA" ;
VAL_ 791 ADAS_DrvrTakeOvrReq 0 "No_Request" 1 "Request_stage_1" 2 "Request_stage_2" 3 "Request_stage_3" 4 "Stopping" 5 "Vehicle_stopped_and_secured" ;
VAL_ 794 ADAS_RAEBAvl 0 "Available" 1 "Not_Available" ;
VAL_ 794 ADAS_FACM_TelltaleReq 0 "FACM_Normal" 1 "FACM_Off" 2 "FACM_Fault_Degraded" 3 "FACM_Intervention" ;
VAL_ 794 ADAS_BACM_WarnSide 0 "None" 1 "WarnLeft" 2 "WarnRight" 3 "Bothsides" 4 "Center" ;
VAL_ 794 ADAS_BrakeIntrvntnSt 0 "Inactive" 1 "Lvl1" 2 "Lvl2" 3 "Brake_Assist" ;
VAL_ 794 ADAS_AEB_Typ 0 "Not_Active" 1 "AEB_standard" 2 "AEB_VRU" 3 "LTAP_AEB" 4 "SCP_AEB" 5 "Rear_AEB" 6 "RCTB" 7 "Reserved" ;
VAL_ 794 ADAS_FACM_SenstvtyPrmpt 0 "No_prompt" 1 "Prompt" ;
VAL_ 794 ADAS_AEBWarnSts 0 "No_warning" 1 "Headway_warning" 2 "Pre-Warning" 3 "Acute_warning_stage_1" 4 "Acute_warning_stage_2" ;
VAL_ 794 ADAS_AEB_RAEB_WarnReq 0 "No_warning" 1 "Warning" ;
VAL_ 794 ADAS_ESA_TelltaleReq 0 "ESA_Normal" 1 "ESA_Off" 2 "ESA_Fault_Degraded" 3 "ESA_Intervention" ;
VAL_ 794 ADAS_ELKA_TelltaleReq 0 "ELKA_LKA_Normal" 1 "ELKA_LKA_Off" 2 "ELKA_LKA_Fault_Degraded" 3 "ELKA_LKA_intervention" ;
VAL_ 795 ADAS_LaneCenteringHandsOnRew 0 "No_Request" 1 "First_HandsOn_Request" 2 "Second_HandsOn_Request" ;
VAL_ 796 ADAS_AccTrgSpdDisp 255 "no_display" ;
VAL_ 796 ADAS_DispSpdUnit_ACC 0 "KMH" 1 "MPH" ;
VAL_ 796 ADAS_AccTrgSpdOvrLmt 0 "Target_speed_equal_or_less_than_limit" 1 "Target_speed_over_speed_limit" ;
VAL_ 796 ADAS_TiGapSet_ACC 0 "Invalid" 1 "Time_gap_1" 2 "Time_gap_2" 3 "Time_gap_3" 4 "Time_gap_4" ;
VAL_ 796 ADAS_TiGapRecommendation_ACC 0 "No_recommendation" 1 "Timegap_1_shortest" 2 "Timegap_2" 3 "Timegap_3" 4 "Timegap_4_longest" ;
VAL_ 796 ADAS_ACCIconDisp 0 "No_Display" 1 "White" 2 "Green" 3 "Fault" ;
VAL_ 796 ADAS_ACCDegrdReq 0 "No_request" 1 "Request_driver_to_acknowledge" ;
VAL_ 796 ADAS_ACCFuncTyp 0 "Default_no_function" 1 "Basic_CC" 2 "Advanced_ACC" 3 "ISA" 4 "Fault" ;
VAL_ 800 ICC_VehFlameoutTiVld 0 "Initializing" 1 "Valid" 2 "Invalid" 3 "Reserved" ;
VAL_ 801 BCM_ValueLightFrnt_RLS 255 "Invalid" ;
VAL_ 801 BCM_LightReqReason_RLS 0 "Day" 1 "Twilight_Drowning" 2 "Night/Night" 4 "Rainlight-light_switch" 5 "Twilight_and_rainlight" 6 "Night_and_rainlight_Night_and_rain" 8 "Tunnel/Tunnel" 9 "Tunnel_and_Twilight/Tunnel_and_Dawing" 12 "Tunnel_and_rainlight" 13 "Tunnel_and_rainlight_and_Twilight_Tunnel_and_Rainy_and_Dusk" 16 "Underground_car_park_Out_of_Underground_Garage" 20 "Underground_car_park_garage_and_rain_light_Pull_out_of_underground_garage_and_rain" ;
VAL_ 811 ADAS_SelfGlaring 0 "0~10%" 1 "10~20%" 2 "20~30%" 3 "30~40%" 4 "40~50%" 5 "50~60%" 7 "60~70%" 8 "70~80%" 9 "80~90%" 10 "90~100%" 14 "Initating" 15 "Not_Available" ;
VAL_ 811 ADAS_Obj_TrfcStyle 0 "Unknow" 1 "Right_Hand_Traffic" 2 "Left_Hand_Traffic" 14 "Initating" 15 "Not_Available" ;
VAL_ 811 ADAS_CamSts 0 "On_Passive" 1 "On_Active" 2 "On_Reduced_Sight" 3 "On_Faliure" 4 "Off" 14 "Initating" 15 "Not_Available" ;
VAL_ 811 ADAS_ObjNr 0 "No_Object_Detected" 1 "1_Object_Detected" 2 "2_Object_Detected" 3 "3_Object_Detected" 4 "4_Object_Detected" 5 "5_Object_Detected" 6 "6_Object_Detected" 7 "7_Object_Detected" 8 "8_Object_Detected" 11 ">8_Object_Detected" 14 "Initating" 15 "Not_Available" ;
VAL_ 811 ADAS_AmbLi 0 "No_Object_Detected" 1 "Day" 2 "Night" 14 "Initating" 15 "Not_Available" ;
VAL_ 811 ADAS_RoadIllmn 0 "No_Detected" 1 "Detected" 14 "Initating" 15 "Not_Available" ;
VAL_ 813 ADAS_Obj3_ID 0 "No_Object_Detected" ;
VAL_ 813 ADAS_Obj3_Conf 0 "Low" 1 "High" ;
VAL_ 813 ADAS_Obj3_Height 0 "Toward_Ego_Vehicle" 1 "Awat_from_Ego_Vehicle" ;
VAL_ 813 ADAS_Obj3_LongDistSign 0 "Positive_Right" 1 "Negative_Left" ;
VAL_ 813 ADAS_Obj3_LatDistSign 0 "Positive_Right" 1 "Negative_Left" ;
VAL_ 813 ADAS_Obj3_Classification 0 "Car" 1 "Truck" 2 "Motorcycle" 3 "Bicycle" 4 "Pedestrian" 5 "Animal_(Not_implemented)" 6 "General_Object_Unknown_size" 7 "General_Object_Small" 8 "General_Object_Large" ;
VAL_ 813 ADAS_VVP_ICC_Obj3BrkLght 0 "Off" 1 "On" ;
VAL_ 813 ADAS_Obj3_ClassConf 0 "25_percent" 1 "50_percent" 2 "75_percent" 3 "100_percent" ;
VAL_ 815 ADAS_Obj6_ID 0 "No_Object_Detected" ;
VAL_ 815 ADAS_Obj6_Conf 0 "Low" 1 "High" ;
VAL_ 815 ADAS_Obj6_Height 0 "Toward_Ego_Vehicle" 1 "Awat_from_Ego_Vehicle" ;
VAL_ 815 ADAS_Obj6_LongDistSign 0 "Positive_Right" 1 "Negative_Left" ;
VAL_ 815 ADAS_Obj6_LatDistSign 0 "Positive_Right" 1 "Negative_Left" ;
VAL_ 815 ADAS_Obj6_Classification 0 "Car" 1 "Truck" 2 "Motorcycle" 3 "Bicycle" 4 "Pedestrian" 5 "Animal_(Not_implemented)" 6 "General_Object_Unknown_size" 7 "General_Object_Small" 8 "General_Object_Large" ;
VAL_ 815 ADAS_VVP_ICC_Obj6BrkLght 0 "Off" 1 "On" ;
VAL_ 815 ADAS_Obj6_ClassConf 0 "25_percent" 1 "50_percent" 2 "75_percent" 3 "100_percent" ;
VAL_ 818 ESP_EmgyBrkLi 0 "Not_Active" 1 "Active" ;
VAL_ 818 ESP_BrkLiReq 0 "Not_Illuminate" 1 "Illuminate" ;
VAL_ 818 ESP_OTAInhbRdy 0 "Initial" 1 "Inhibit" 2 "Not_Inhibit" 3 "Invalid" ;
VAL_ 818 ESP_ActvIndcn_HHC 0 "Not_Active" 1 "Active" ;
VAL_ 818 ESP_FltIndcn_HHC 0 "Available" 1 "Not_Available" ;
VAL_ 818 ESP_ActvIndcn_AVH 0 "Not_Active" 1 "Active" ;
VAL_ 818 ESP_SwtIndcn_AVH 0 "Not_Standby" 1 "Standby" ;
VAL_ 818 ESP_FltIndcn_AVH 0 "Available" 1 "Not_Available" ;
VAL_ 818 ESP_ActvIndcn_CDP 0 "Not_Active" 1 "Active" ;
VAL_ 818 ESP_FltIndcn_CDP 0 "Available" 1 "Not_Available" ;
VAL_ 818 ESP_ActvIndcn_HBB 0 "Not_Active" 1 "Active" ;
VAL_ 818 ESP_Sts_HBB 0 "HBB_Normal_Mode" 1 "HBB_FailedBoost" 2 "HBB_FailedBoostBackup" 3 "HBB_Disabled" ;
VAL_ 818 ESP_BrkPadWearWarn 0 "init_not_active" 1 "FA_active" 2 "RA_active" 3 "FA_RA_active" 4 "fault" 7 "Invalid" ;
VAL_ 820 ADAS_FobdSign 0 "Default" 1 "Forbidden_to_turn_left" 2 "Forbidden_to_turn_right" 3 "Do_not_U-turn" 4 "No_entry" 5 "Prohibited" 6 "No_motor_vehicles_allowed" ;
VAL_ 820 ADAS_FrntCamBli 0 "No_Blind" 1 "Blind" ;
VAL_ 820 ADAS_AHBA_FltTxt 0 "Default" 1 "Intelligent_high_beam_function_failure" ;
VAL_ 820 ADAS_FrntCamFlt 0 "No_Failure" 1 "Reversible_Failure" 2 "Irrversible_Failure" 3 "Reserved" ;
VAL_ 820 ADAS_AHBA_LiSigReq 0 "Low_Beam_Request" 1 "High_Beam_Request" ;
VAL_ 825 ADAS_LeLine1Crvt 63 "Straight_Lane" 127 "No_Display" ;
VAL_ 825 ADAS_LeLine1LnColor 0 "White" 1 "Yellow" 2 "Blue" 3 "Invalid" ;
VAL_ 825 ADAS_LeLine1LnTyp 0 "Unknown" 1 "SingleLine_Solid" 2 "SingleLine_dashed" 3 "SingleLine_BottsDots" 4 "DoubleLine_Solid_Dashed" 5 "DoubleLine_Dash_Dash" 6 "DoubleLine_Dash_Solid" 7 "DoubleLine_Solid_Solid" 8 "Road_Edge" ;
VAL_ 825 ADAS_LeLine1Conf 0 "12_5_percent" 1 "25_percent" 2 "37_5_percent" 3 "50_percent" 4 "62_5_percent" 5 "75_percent" 6 "87_5_percent" 7 "100_percent" ;
VAL_ 827 ADAS_Obj1_ID 0 "No_Object_Detected" ;
VAL_ 827 ADAS_Obj1_Conf 0 "Low" 1 "High" ;
VAL_ 827 ADAS_Obj1_Height 0 "Toward_Ego_Vehicle" 1 "Awat_from_Ego_Vehicle" ;
VAL_ 827 ADAS_Obj1_LongDistSign 0 "Positive_Right" 1 "Negative_Left" ;
VAL_ 827 ADAS_Obj1_LatDistSign 0 "Positive_Right" 1 "Negative_Left" ;
VAL_ 827 ADAS_Obj1_Classification 0 "Car" 1 "Truck" 2 "Motorcycle" 3 "Bicycle" 4 "Pedestrian" 5 "Animal_(Not_implemented)" 6 "General_Object_Unknown_size" 7 "General_Object_Small" 8 "General_Object_Large" ;
VAL_ 827 ADAS_VVP_ICC_Obj1BrkLght 0 "Off" 1 "On" ;
VAL_ 827 ADAS_Obj1_ClassConf 0 "25_percent" 1 "50_percent" 2 "75_percent" 3 "100_percent" ;
VAL_ 829 ADAS_Obj4_ID 0 "No_Object_Detected" ;
VAL_ 829 ADAS_Obj4_Conf 0 "Low" 1 "High" ;
VAL_ 829 ADAS_Obj4_Height 0 "Toward_Ego_Vehicle" 1 "Awat_from_Ego_Vehicle" ;
VAL_ 829 ADAS_Obj4_LongDistSign 0 "Positive_Right" 1 "Negative_Left" ;
VAL_ 829 ADAS_Obj4_LatDistSign 0 "Positive_Right" 1 "Negative_Left" ;
VAL_ 829 ADAS_Obj4_Classification 0 "Car" 1 "Truck" 2 "Motorcycle" 3 "Bicycle" 4 "Pedestrian" 5 "Animal_(Not_implemented)" 6 "General_Object_Unknown_size" 7 "General_Object_Small" 8 "General_Object_Large" ;
VAL_ 829 ADAS_VVP_ICC_Obj4BrkLght 0 "Off" 1 "On" ;
VAL_ 829 ADAS_Obj4_ClassConf 0 "25_percent" 1 "50_percent" 2 "75_percent" 3 "100_percent" ;
VAL_ 831 ADAS_Obj7_ID 0 "No_Object_Detected" ;
VAL_ 831 ADAS_Obj7_Conf 0 "Low" 1 "High" ;
VAL_ 831 ADAS_Obj7_Height 0 "Toward_Ego_Vehicle" 1 "Awat_from_Ego_Vehicle" ;
VAL_ 831 ADAS_Obj7_LongDistSign 0 "Positive_Right" 1 "Negative_Left" ;
VAL_ 831 ADAS_Obj7_LatDistSign 0 "Positive_Right" 1 "Negative_Left" ;
VAL_ 831 ADAS_Obj7_Classification 0 "Car" 1 "Truck" 2 "Motorcycle" 3 "Bicycle" 4 "Pedestrian" 5 "Animal_(Not_implemented)" 6 "General_Object_Unknown_size" 7 "General_Object_Small" 8 "General_Object_Large" ;
VAL_ 831 ADAS_VVP_ICC_Obj7BrkLght 0 "Off" 1 "On" ;
VAL_ 831 ADAS_Obj7_ClassConf 0 "25_percent" 1 "50_percent" 2 "75_percent" 3 "100_percent" ;
VAL_ 832 ADAS_LeLineColor 0 "Gray" 1 "White" 2 "Blue(Alc)" 3 "Red" ;
VAL_ 832 ADAS_RiLineColor 0 "Gray" 1 "White" 2 "Blue(Alc)" 3 "Red" ;
VAL_ 832 ADAS_LeLineFlash 0 "No_Flash" 1 "Flash" ;
VAL_ 832 ADAS_RiLineFlash 0 "No_Flash" 1 "Flash" ;
VAL_ 832 ADAS_LeLineTyp 0 "Default" 1 "Solid_Lane" 2 "Dashed_Lane(Alc)" 3 "Reserved" ;
VAL_ 832 ADAS_RiLineTyp 0 "Default" 1 "Solid_Lane" 2 "Dashed_Lane(Alc)" 3 "Reserved" ;
VAL_ 832 ADAS_LaneCrvt 63 "Straight_Lane" 127 "No_Display" ;
VAL_ 832 ADAS_FltIndcr 0 "Default" 1 "No_Fault" 2 "Fault" 3 "Dynamic_Calibration_Running" ;
VAL_ 834 ADAS_LatCtrl_LeTurnLampReq 0 "No_request" 1 "Request_On" 2 "Request_Off" 3 "Reserved" ;
VAL_ 834 ADAS_LatCtrl_RiTurnLampReq 0 "No_request" 1 "Request_On" 2 "Request_Off" 3 "Reserved" ;
VAL_ 834 ADAS_LatCtrl_HapticReq 0 "No_request" 1 "Haptic_warning" ;
VAL_ 834 ADAS_LatCtrl_HzrdLampReq 0 "No_hazard_warning" 1 "Hazard_warning_Request" 2 "Reserved" ;
VAL_ 834 ADAS_VehMovDir 0 "Not_moving" 1 "Moving_forwards" 2 "Moving_backwards" ;
VAL_ 834 ADAS_HOD_HandsOnWarnReq 0 "No_Req" 1 "Request_driver_hands-on_/_gentle" 2 "Request_driver_hands-on_/_firm" 3 "Request_driver_hands-on_/_urgent" ;
VAL_ 834 ADAS_DoorLockReq 0 "Inactive" 1 "No_request" 2 "Lock_Doors" 3 "Invalid" ;
VAL_ 834 ADAS_AVASReq 0 "Inactive" 1 "Tqurn_On_Sound" 2 "Turn_Off_Sound" 3 "Invalid" ;
VAL_ 834 ADAS_RAPAvl 0 "RAP_not_available" 1 "RAP_available" ;
VAL_ 834 ADAS_TPReplayAvl 0 "TP_Replay_not_available" 1 "TP_Replay_available" ;
VAL_ 834 ADAS_TPReplaySuc 0 "TP_Replay_failed" 1 "TP_Replay_completed" ;
VAL_ 834 ADAS_Sts_RAP 0 "off" 1 "init" 2 "standby" 3 "active" 4 "fault" ;
VAL_ 834 ADAS_Sts_TP 0 "Off" 1 "Init" 2 "Standby" 3 "Train" 4 "Replay" 5 "Fault" ;
VAL_ 834 ADAS_ExtLightReq 0 "No_request" 1 "activate_exterior_light" ;
VAL_ 834 ADAS_HODSts 0 "Invalid" 1 "Hands_On" 2 "Hands_Off" 3 "Energy_Saver" 4 "Not_Available" 5 "Reserved" 6 "Resrved" 7 "Reserved" ;
VAL_ 837 BCM_OutpValResl_HUD 0 "HUD_Measuring_Range_1(4cd/m2)" 1 "HUD_Measuring_Range_1(40cd/m2)" ;
VAL_ 837 BCM_SunshadeRunngSts 0 "Stopped" 1 "Opening_Slide" 2 "Closing_Slide" 3 "Reversing_(AP/Stall)" 4 "Moving_Uninitialized" ;
VAL_ 843 ADAS_Obj2_ID 0 "No_Object_Detected" ;
VAL_ 843 ADAS_Obj2_Conf 0 "Low" 1 "High" ;
VAL_ 843 ADAS_Obj2_Height 0 "Toward_Ego_Vehicle" 1 "Awat_from_Ego_Vehicle" ;
VAL_ 843 ADAS_Obj2_LongDistSign 0 "Positive_Right" 1 "Negative_Left" ;
VAL_ 843 ADAS_Obj2_LatDistSign 0 "Positive_Right" 1 "Negative_Left" ;
VAL_ 843 ADAS_Obj2_Classification 0 "Car" 1 "Truck" 2 "Motorcycle" 3 "Bicycle" 4 "Pedestrian" 5 "Animal_(Not_implemented)" 6 "General_Object_Unknown_size" 7 "General_Object_Small" 8 "General_Object_Large" ;
VAL_ 843 ADAS_VVP_ICC_Obj2BrkLght 0 "Off" 1 "On" ;
VAL_ 843 ADAS_Obj2_ClassConf 0 "25_percent" 1 "50_percent" 2 "75_percent" 3 "100_percent" ;
VAL_ 845 ADAS_Obj5_ID 0 "No_Object_Detected" ;
VAL_ 845 ADAS_Obj5_Conf 0 "Low" 1 "High" ;
VAL_ 845 ADAS_Obj5_Height 0 "Toward_Ego_Vehicle" 1 "Awat_from_Ego_Vehicle" ;
VAL_ 845 ADAS_Obj5_LongDistSign 0 "Positive_Right" 1 "Negative_Left" ;
VAL_ 845 ADAS_Obj5_LatDistSign 0 "Positive_Right" 1 "Negative_Left" ;
VAL_ 845 ADAS_Obj5_Classification 0 "Car" 1 "Truck" 2 "Motorcycle" 3 "Bicycle" 4 "Pedestrian" 5 "Animal_(Not_implemented)" 6 "General_Object_Unknown_size" 7 "General_Object_Small" 8 "General_Object_Large" ;
VAL_ 845 ADAS_VVP_ICC_Obj5BrkLght 0 "Off" 1 "On" ;
VAL_ 845 ADAS_Obj5_ClassConf 0 "25_percent" 1 "50_percent" 2 "75_percent" 3 "100_percent" ;
VAL_ 847 ADAS_Obj8_ID 0 "No_Object_Detected" ;
VAL_ 847 ADAS_Obj8_Conf 0 "Low" 1 "High" ;
VAL_ 847 ADAS_Obj8_Height 0 "Toward_Ego_Vehicle" 1 "Awat_from_Ego_Vehicle" ;
VAL_ 847 ADAS_Obj8_LongDistSign 0 "Positive_Right" 1 "Negative_Left" ;
VAL_ 847 ADAS_Obj8_LatDistSign 0 "Positive_Right" 1 "Negative_Left" ;
VAL_ 847 ADAS_Obj8_Classification 0 "Car" 1 "Truck" 2 "Motorcycle" 3 "Bicycle" 4 "Pedestrian" 5 "Animal_(Not_implemented)" 6 "General_Object_Unknown_size" 7 "General_Object_Small" 8 "General_Object_Large" ;
VAL_ 847 ADAS_VVP_ICC_Obj8BrkLght 0 "Off" 1 "On" ;
VAL_ 847 ADAS_Obj8_ClassConf 0 "25_percent" 1 "50_percent" 2 "75_percent" 3 "100_percent" ;
VAL_ 848 ADAS_LeftLaneType 0 "Lane" 1 "Raod_Edge" 2 "Barrier" 3 "Exit" ;
VAL_ 848 ADAS_RightLaneType 0 "Lane" 1 "Raod_Edge" 2 "Barrier" 3 "Exit" ;
VAL_ 848 ADAS_LandmarkType 0 "Bridge" 1 "Tunnel" 2 "Tollbooth" 3 "Gate" 4 "Traffic_Light" ;
VAL_ 848 ADAS_LaneMarkingType 0 "Intersection_Stop_Line" 1 "Intersection_Crosswalk" 2 "Crosswalk" 3 "Bicycle_Lane" 4 "Carpool_Lane" ;
VAL_ 848 ADAS_ConstructionObjectType 0 "Barrel" 1 "Cone" 2 "Fishbone_Left" 3 "Fishbone_Right" 4 "Obstruction_Left" 5 "Obstruction_Right" ;
VAL_ 848 ADAS_LeLn1TrffcDir 0 "Oncoming_Traffic" 1 "Not_Oncoming" ;
VAL_ 848 ADAS_LeLn2TrffcDir 0 "Oncoming_Traffic" 1 "Not_Oncoming" ;
VAL_ 848 ADAS_RiLn1TrffcDir 0 "Oncoming_Traffic" 1 "Not_Oncoming" ;
VAL_ 848 ADAS_RiLn2TrffcDir 0 "Oncoming_Traffic" 1 "Not_Oncoming" ;
VAL_ 849 ADAS_LdngVhclTurnSig 0 "none" 1 "Right_Turn" 2 "Left_Turn" 3 "Hazard" ;
VAL_ 849 ADAS_LdngVhclBrkLi 0 "FALSE" 1 "TRUE" ;
VAL_ 849 ADAS_HzdDetected 0 "TRUE" 1 "FALSE" ;
VAL_ 850 ADAS_USS_B0 0 "Off" 1 "Zone_1" 2 "Zone_2" 3 "Zone_3" 4 "Zone_4" 5 "Zone_5" 6 "Zone_6" 7 "Zone_7" 8 "Zone_8" 9 "No_Obstacle_Detected" 15 "FAULT" ;
VAL_ 850 ADAS_USS_F0 0 "Off" 1 "Zone_1" 2 "Zone_2" 3 "Zone_3" 4 "Zone_4" 9 "No_Obstacle_Detected" 15 "FAULT" ;
VAL_ 850 ADAS_USS_B1 0 "Off" 1 "Zone_1" 2 "Zone_2" 3 "Zone_3" 4 "Zone_4" 5 "Zone_5" 6 "Zone_6" 7 "Zone_7" 8 "Zone_8" 9 "No_Obstacle_Detected" 15 "FAULT" ;
VAL_ 850 ADAS_USS_F1 0 "Off" 1 "Zone_1" 2 "Zone_2" 3 "Zone_3" 4 "Zone_4" 9 "No_Obstacle_Detected" 15 "FAULT" ;
VAL_ 850 ADAS_USS_B2 0 "Off" 1 "Zone_1" 2 "Zone_2" 3 "Zone_3" 4 "Zone_4" 5 "Zone_5" 6 "Zone_6" 7 "Zone_7" 8 "Zone_8" 9 "No_Obstacle_Detected" 15 "FAULT" ;
VAL_ 850 ADAS_USS_F2 0 "Off" 1 "Zone_1" 2 "Zone_2" 3 "Zone_3" 4 "Zone_4" 9 "No_Obstacle_Detected" 15 "FAULT" ;
VAL_ 850 ADAS_USS_B3 0 "Off" 1 "Zone_1" 2 "Zone_2" 3 "Zone_3" 4 "Zone_4" 5 "Zone_5" 6 "Zone_6" 7 "Zone_7" 8 "Zone_8" 9 "No_Obstacle_Detected" 15 "FAULT" ;
VAL_ 850 ADAS_USS_F3 0 "Off" 1 "Zone_1" 2 "Zone_2" 3 "Zone_3" 4 "Zone_4" 9 "No_Obstacle_Detected" 15 "FAULT" ;
VAL_ 850 ADAS_USS_L0 0 "Off" 1 "Zone_1" 2 "Zone_2" 3 "Zone_3" 4 "Zone_4" 9 "No_Obstacle_Detected" 15 "FAULT" ;
VAL_ 850 ADAS_USS_L1 0 "Off" 1 "Zone_1" 2 "Zone_2" 3 "Zone_3" 4 "Zone_4" 9 "No_Obstacle_Detected" 15 "FAULT" ;
VAL_ 850 ADAS_USS_L2 0 "Off" 1 "Zone_1" 2 "Zone_2" 3 "Zone_3" 4 "Zone_4" 9 "No_Obstacle_Detected" 15 "FAULT" ;
VAL_ 850 ADAS_USS_L3 0 "Off" 1 "Zone_1" 2 "Zone_2" 3 "Zone_3" 4 "Zone_4" 9 "No_Obstacle_Detected" 15 "FAULT" ;
VAL_ 850 ADAS_USS_R0 0 "Off" 1 "Zone_1" 2 "Zone_2" 3 "Zone_3" 4 "Zone_4" 9 "No_Obstacle_Detected" 15 "FAULT" ;
VAL_ 850 ADAS_USS_R1 0 "Off" 1 "Zone_1" 2 "Zone_2" 3 "Zone_3" 4 "Zone_4" 9 "No_Obstacle_Detected" 15 "FAULT" ;
VAL_ 850 ADAS_USS_R2 0 "Off" 1 "Zone_1" 2 "Zone_2" 3 "Zone_3" 4 "Zone_4" 9 "No_Obstacle_Detected" 15 "FAULT" ;
VAL_ 850 ADAS_USS_R3 0 "Off" 1 "Zone_1" 2 "Zone_2" 3 "Zone_3" 4 "Zone_4" 9 "No_Obstacle_Detected" 15 "FAULT" ;
VAL_ 851 ADAS_VwPrtCamAngl 0 "Default" 1 "Normal_driving_angle_1" 2 "Normal_driving_angle_2" 3 "Normal_driving_angle_3" 4 "Turning_angle_1" 5 "Turning_angle_2" 6 "Turning_angle_3" 7 "Parking_angle_1" 8 "Parking_angle_2" 9 "Parking_angle_3" 10 "0xF:_Reserved" ;
VAL_ 854 ADAS_ObjDst_FLS 255 "No_Object" ;
VAL_ 854 ADAS_ObjDst_FLC 255 "No_Object" ;
VAL_ 854 ADAS_ObjDst_FLM 255 "No_Object" ;
VAL_ 854 ADAS_ObjDst_FRS 255 "No_Object" ;
VAL_ 854 ADAS_ObjDst_FRC 255 "No_Object" ;
VAL_ 854 ADAS_ObjDst_FRM 255 "No_Object" ;
VAL_ 855 VCU_ChrgSts_GB 0 "Initial_value" 1 "Parking_charging" 2 "Driving_charging" 3 "Not_charged" 4 "Charging_complete" ;
VAL_ 855 VCU_MCUFltSum_GB 254 "abnormal" 255 "Invalid" ;
VAL_ 855 VCU_BrkPedlSts_GB 0 "brake_OFF" 101 "braking_active_state" ;
VAL_ 855 VCU_SOCLoWakeUpEnaCmd 0 "Do_not_wake_up" 1 "allowed_to_wake_up" ;
VAL_ 855 VCU_DrvModDiRmn 0 "Initial_value" 1 "The_E-Pedal_is_activated" 2 "All_Terrain_activated" ;
VAL_ 855 VCU_SpclTerrainModUsrRmn 0 "Initial_value" 1 "ESP_function_activated_to_disable_all_terrain" 2 "ESP_function_fault_disabled_all_terrain" 3 "Intelligent_driving_activated_disable_all_terrain" 4 "Vehicle_speed_too_high_Disable_all_terrain" ;
VAL_ 855 VCU_BattIntegtChrgEndFlg 0 "Not_ended" 1 "ended" ;
VAL_ 855 VCU_BattIntegtChrgModPwrOnReq 0 "Initialization" 1 "No_demand" 2 "On_demand" 3 "Reserved" ;
VAL_ 855 VCU_BattIntegtChrgWakeUpSts 0 "Not_waken_up" 1 "waken_up" ;
VAL_ 855 VCU_RemUgrdFltFbSig 0 "Initial_value" 1 "Low_battery" 2 "Low_traction_battery" 3 "The_vehicle_is_not_stationary" 4 "gear_is_not_at_P,_N_gear" 5 "The_vehicle_is_at_Ready" 6 "vehicle_not_allowed_for_silent_upgrade" 7 "high_voltage_power-off_fault" 8 "R_&_D_upgrade_download_program,_the_battery_power_does_not_meet_the_demand" ;
VAL_ 855 VCU_OTAInhbRdy 0 "Initial" 1 "Inhibit" 2 "Not_Inhibit" 3 "Invalid" ;
VAL_ 857 ADAS_ObjDst_RLS 255 "No_Object" ;
VAL_ 857 ADAS_ObjDst_RLC 255 "No_Object" ;
VAL_ 857 ADAS_ObjDst_RLM 255 "No_Object" ;
VAL_ 857 ADAS_ObjDst_RRS 255 "No_Object" ;
VAL_ 857 ADAS_ObjDst_RRC 255 "No_Object" ;
VAL_ 857 ADAS_ObjDst_RRM 255 "No_Object" ;
VAL_ 859 ICC_ViewReq 0 "None" 1 "Front_Normal_View" 2 "Left_Flank_3D_view" 3 "Right_Flank_3D_View" 4 "Rear_Normal_View" 5 "Curb_View_or_split_view" 6 "360_View_or_3D_Freefloating_view" 7 "Front_Cross_Path_View" 8 "Rear_Cross_Path_View" ;
VAL_ 859 ICC_ShowSts 0 "Not_Show" 1 "Show" ;
VAL_ 859 ICC_SVS_AutoVwBttnReq 0 "Auto_camera_view_not_requested" 1 "Auto_camera_view_requested" ;
VAL_ 859 ICC_SVS_CamVwCnclReq 0 "Camera__view_port_exit_button_not_pressed" 1 "Camera__view_port_exit_button_pressed" ;
VAL_ 859 ICC_AutomaticViewReq 0 "Off" 1 "On" ;
VAL_ 859 ICC_360FreeFloatingReq 0 "Off" 1 "On" ;
VAL_ 859 ICC_GraphicOverlayReq 0 "Off" 1 "On" ;
VAL_ 859 ICC_OperationType 0 "No_Request" 1 "PINCH_ZOOM" 2 "QUICK_ZOOM_(double_tap)" 3 "PAN_(swipe)" ;
VAL_ 859 ICC_ZOOM_Start 0 "NO" 1 "Yes" ;
VAL_ 859 ICC_ZOOM_End 0 "NO" 1 "Yes" ;
VAL_ 859 ICC_EnbLnChgAsst 0 "Auto_steer_not_enabled" 1 "Auto_steer_enabled" ;
VAL_ 859 ICC_BSDSetting 0 "OFF" 1 "ON_with_Visual" 2 "ON_with_visual_and_audio" 3 "ON_with_visual_and_audio_and_Steering_Wheel_Vibration" ;
VAL_ 859 ICC_DOW_Setting 0 "OFF" 1 "ON_with_Visual" 2 "ON_with_visual_and_audio" 3 "Reserved" ;
VAL_ 859 ICC_DCAASetting 0 "OFF" 1 "ON" ;
VAL_ 859 ICC_APA_Setting 0 "Coded_off_(not_equipped)" 1 "Off_(by_user)" 2 "Enabled" 3 "Reserved" ;
VAL_ 859 ICC_APAParkSelect 0 "Slot_not_selected" 1 "Slot_1" 2 "Slot_2" 3 "Slot_3" 4 "Slot_4" 5 "Slot_5" 6 "Slot_6" ;
VAL_ 859 ICC_APAActivation 0 "Cancel" 1 "On" ;
VAL_ 859 ICC_APAParkInDirSetting 0 "Nose-in" 1 "Back-in" ;
VAL_ 859 ICC_APAParkOutDirSetting 0 "Right" 1 "Left" ;
VAL_ 859 ICC_ParkAsstChmAlrt 0 "Off" 1 "On" ;
VAL_ 859 ICC_WSPPA_Setting 0 "No_curb_protection" 1 "Warning_only" 2 "Braking_intervention" 3 "Reserved" ;
VAL_ 859 ICC_AHBA_Setting 0 "Off" 1 "On" ;
VAL_ 859 ICC_APAParkOutAct 0 "No_request" 1 "Request" ;
VAL_ 859 ICC_SteerWhlVibrSet 0 "Off" 1 "On" ;
VAL_ 859 ICC_WarnTypeSetting 0 "OFF" 1 "ON_with_Visual" 2 "ON_with_visual_and_audio" 3 "ON_with_visual_and_audio_and_Steering_Wheel_Vibration" ;
VAL_ 859 ICC_LKA_SettingWrnTyp 0 "Audio_Visual_and_Haptic" 1 "Visual_and_Audio" ;
VAL_ 859 ICC_RAP_Setting 0 "Remote_Automated_Parking_Disabled" 1 "Remote_Automated_Parking_Enabled" ;
VAL_ 859 ICC_TP_Setting 0 "Trained_Parking_Disabled" 1 "Trained_Parking_Enabled" ;
VAL_ 859 ICC_BSD_Sensitivity 0 "Normal" 1 "Early" 2 "Late_or_reduced" 3 "Reserved" ;
VAL_ 865 ICC_PosnMsgTye 0 "System_Specific" 1 "Position" 2 "Segment" 3 "Stub" 4 "Profile_Short" 5 "Profile_Long" 6 "Meta-data" 7 "Reserved" ;
VAL_ 865 ICC_PosnOffset 8191 "Invalid" ;
VAL_ 865 ICC_PosnPosProbb 0 "unknown" 31 "Invalid" ;
VAL_ 865 ICC_PosnAge 510 ">2545ms" 511 "Invalid" ;
VAL_ 865 ICC_PosnCurLane 0 "Unknown" 1 "Emergency_lane" 2 "Single-lane_road" 3 "Left-most_lane" 4 "Right-most_lane" 5 "One_of_middle_lanes_on_road_with_three_or_more_lanes" 6 "Reserved" 7 "Invalid" ;
VAL_ 865 ICC_PosnPosConfdc 7 "Invalid" ;
VAL_ 865 ICC_PosnSpd 0 "≤_-12.8_m/s_?" 64 "Standing_still" 510 "≥_+89.2_m/s_?" 511 "Invalid" ;
VAL_ 865 ICC_PosnRehead 0 "In_Path_Direction" 1 "1.417_Degrees_Right" 126 "178.583_Degrees_Right" 127 "Opposite_Direction" 128 "178.583_Degrees_Left_(181.417_Degrees_Right)+R[6]C" 253 "1.417_Degrees_left_(358.583_Degrees_Right)" 254 "Unknown" 255 "Invalid" ;
VAL_ 866 ICC_MetaMapProvider 0 "Unknown" 1 "Nokia_HERE_(NAVTEQ)" 2 "TomTom_(Tele_Atlas)" 3 "Zenrin" 4 "IPC" 5 "NavInfo" 6 "Other" 7 "N/A" ;
VAL_ 866 ICC_MetaMsgType 0 "System_Specific" 1 "Position" 2 "Segment" 3 "Stub" 4 "Profile_Short" 5 "Profile_Long" 6 "Meta-data" 7 "Reserved" ;
VAL_ 866 ICC_MetaHwVer 0 "Unknown" ;
VAL_ 866 ICC_MetaDrvSide 0 "Driving_Side_Left" 1 "Driving_Side_Right_Default_is_0x1" ;
VAL_ 866 ICC_MetaSpdUnits 0 "Kilometers_Per_Hour_(km/h)" 1 "Miles_Per_Hour_(mph)_Default_is_0" ;
VAL_ 867 VCU_ACDchaStrtFailReason 0 "Initial_value" 1 "Discharging_gun_not_connected_well,_please_replug_it" 2 "No_vehicle_is_detected_for_charging" 3 "Veh_discharg_system_failed,_pull_the_gun_out,_restart_and_repeat_the_steps_agency" 4 "Dicharging_gun_not_locked" 5 "To_discharge,_please_click_the_discharge_button" ;
VAL_ 867 VCU_AllwRemHeatgSts 0 "Initial_value" 1 "BMS_remote_heating_allowed" 2 "SOC_too_low,_remote_heating_not_allowed" 3 "Temperature_too_low,_remote_heating_not_allowed" 4 "In_charging,_remote_heating_not_allowed" 5 "BMS_fault" 6 "Temperature_acceptable,_no_remote_heating_required" 7 "Reserved" ;
VAL_ 867 VCU_FbRemHeatgOperSts 0 "initializing" 1 "Remote_heating" ;
VAL_ 867 VCU_ChrgEndSOCCrtCtrlFlg 0 "No_demand" 1 "Charge_at_min._current" 2 "Request_0A_(standby)" 3 "Reserved" ;
VAL_ 867 VCU_Lvl2ProtStrtFlg 0 "Not_active" 1 "Active" ;
VAL_ 867 VCU_TotOverVoltLvl2ProtFlg 0 "No_fault" 1 "Fault" ;
VAL_ 867 VCU_UnderVoltFltLvl2ProtFlg 0 "No_fault" 1 "Fault" ;
VAL_ 867 VCU_OverTFltLvl2ProtFlg 0 "No_fault" 1 "Fault" ;
VAL_ 867 VCU_OverVoltFltLvl2ProtFlg 0 "No_fault" 1 "Fault" ;
VAL_ 867 VCU_CellIntShoFltLvl2ProtFlg 0 "No_fault" 1 "Fault" ;
VAL_ 867 VCU_InsulFltLvl2ProtFlg 0 "No_fault" 1 "Fault" ;
VAL_ 867 VCU_VehCfgExchgFlg 0 "No" 1 "Yes" ;
VAL_ 867 VCU_ReadEEFailFlg 0 "No" 1 "Yes" ;
VAL_ 867 VCU_WrEEFailFlg 0 "No" 1 "Yes" ;
VAL_ 867 VCU_FirstUseEEFlg 0 "No" 1 "Yes" ;
VAL_ 867 VCU_SwUpdataFlg 0 "No" 1 "Yes" ;
VAL_ 867 VCU_NewOldEESwtFlg 0 "No" 1 "Yes" ;
VAL_ 867 VCU_FSCFillEndFlg 0 "Not_fully_charged" 1 "Fully_charged_and_completed" ;
VAL_ 867 VCU_MaxAlrmLvl 0 "No_fault" 1 "Class_1_fault" 2 "Class_2_fault" 3 "Class_3_fault" ;
VAL_ 867 VCU_UsrStopChrgReqSts 0 "No_request" 1 "Request_for_stopping_charging/discharing_through_the_key" 2 "Request_for_stopping_charging/discharing_through_the_button" 3 "Reserved" ;
VAL_ 867 VCU_DchaIndcrLampCtrlCmd 0 "off" 1 "on" ;
VAL_ 867 VCU_VehExtDchaSts 0 "Initial_value" 1 "Prepare_for_discharging" 2 "Discharging" 3 "Discharging_completed" 4 "No_discharging_allowed" 5 "Internal_Discharge_Error" 6 "Overcurrent_Error" 7 "Invalid" ;
VAL_ 867 VCU_S1SwtCmd 0 "Initial_value" 1 "Electric_level_command" 2 "PWM_command" 3 "Invalid" ;
VAL_ 867 VCU_DchaFltStsIndcn 0 "Normal" 1 "Fault" ;
VAL_ 867 VCU_DchaUsrSetThd 0 "Not_arrived" 1 "Arrived" ;
VAL_ 867 VCU_RemHeatgDmd 0 "Initial_value" 1 "Remote_heating_in_demand" 2 "No_remote_heating_demand" 3 "Reserved" ;
VAL_ 867 VCU_PwrBattHeatgTyp 0 "Initial_value" 1 "Power_battery_charging" 2 "Charging_pile_charging" 3 "No_demand" ;
VAL_ 867 VCU_ChrgInsulFctOpenSts 0 "Thermal_insulation_off" 1 "Thermal_insulation_on" ;
VAL_ 867 VCU_ChrgEquipPwrNotEngh 0 "Initial_value" 1 "Charging_power_insufficient" 2 "Charging_power_sufficient" 3 "Reserved" ;
VAL_ 867 VCU_ACChrgStrtFailReason 0 "Initial_value" 1 "Charging_gun_not_connected_well,_please_replug_it" 2 "Charging_pile_unable_to_be_started,_please_sweep_the_card_or_change_the_pile" 3 "Veh_charg_sys_failed,_pull_gun_out,_restart_vehicle,_repeat_the_steps,_cont_agency" 4 "Charging_gun_not_locked" ;
VAL_ 873 BCM_AP_TL_LeReWinSts 0 "Closed" 1 "Open" ;
VAL_ 873 BCM_AP_TL_RiReWinSts 0 "Closed" 1 "Open" ;
VAL_ 873 BCM_AP_RW_WinSts 0 "Closed" 1 "Open" ;
VAL_ 873 BCM_BackgndBriLvl_Cfm 0 "Level_1" 1 "Level_2" 2 "Level_3" 3 "Level_4" 4 "Level_5" 5 "Level_6" 6 "Level_7" 7 "Level_8" 8 "Level_9" 9 "Level_10" ;
VAL_ 873 BCM_LeMirrrXDircAdjSwtSts 0 "Off" 1 "Left" 2 "Right" 3 "Defect" ;
VAL_ 873 BCM_LeMirrrYDircAdjSwtSts 0 "Off" 1 "Down" 2 "Up" 3 "Defect" ;
VAL_ 873 BCM_RiMirrrXDircAdjSwtSts 0 "Off" 1 "Left" 2 "Right" 3 "Defect" ;
VAL_ 873 BCM_RiMirrrYDircAdjSwtSts 0 "Off" 1 "Down" 2 "Up" 3 "Defect" ;
VAL_ 873 BCM_MirrSelectSwtSts 0 "Off" 1 "Left_mirror" 2 "Right_mirror" 3 "No_mirrors" ;
VAL_ 875 PKC_ConnStatus 0 "no_connection" 1 "unknown_device_connected" 2 "known_device_connected" 3 "default_(no_connection)" ;
VAL_ 875 PKC_PhoneConnStatus 0 "no_connection_" 1 "unknown_device_connected" 2 "known_device_connected" 3 "default_(no_connection)" ;
VAL_ 875 PKC_PhonePairingMode 0 "inactive" 1 "Pairing_Mode_Active" 2 "Sucessful" 3 "Unsucessful" 4 "default_(inactive)" ;
VAL_ 875 PKC_AutolLockUnlock_FB 0 "Auto_Unlock/Lock_Disabled" 1 "Auto_Unlock_Enabled" 2 "Auto_Lock_Enabled" 3 "Auto_Unlock/Lock_Enabled" ;
VAL_ 875 PKC_KeyPairingMode 0 "inactive" 1 "Pairing_Mode_Active" 2 "Sucessful" 3 "Unsucessful" 4 "default_(inactive)" ;
VAL_ 875 PKC_UserProfileID 0 "inactive" 1 "User_Profile_ID_number1(guest/default)" 2 "User_Profile_ID_number2" 3 "User_Profile_ID_number3" 4 "User_Profile_ID_number4" 5 "User_Profile_ID_number5" 6 "User_Profile_ID_number6" 7 "User_Profile_ID_number7" 8 "User_Profile_ID_number8" 9 "User_Profile_ID_number9" 10 "User_Profile_ID_number10" ;
VAL_ 877 PKC_NFCTagStatus 0 "no_tag_present" 1 "passive_tag_present" 2 "active_tag_present" 3 "default(not_tag)" ;
VAL_ 877 PKC_NFCTagAuthStatus 0 "no_active_session" 1 "authenticated" 2 "authentication_failed" 3 "default_(no_active_session)" ;
VAL_ 877 PKC_NFCReaderExtStatus 0 "no_fault" 1 "Under_Voltage" 2 "Over_Voltage" 3 "Memory_Integrity_Failure" 4 "RF_Failure" 5 "RF_Interference" 6 "Reserved" 7 "default_(no_fault)" ;
VAL_ 877 PKC_NFCReaderIntStatus 0 "no_fault" 1 "Under_Voltage" 2 "Over_Voltage" 3 "Memory_Integrity_Failure" 4 "RF_Failure" 5 "RF_Interference" 6 "Reserved" 7 "default_(no_fault)" ;
VAL_ 885 MCU_F_FltProcLvl 0 "Reserved_value" 3 "Zero_torque" 4 "Reserved" 5 "Power/torque_Limitation_environment_conditions" 6 "normal_operation" 14 "Init_Values" 15 "Invalid" ;
VAL_ 885 MCU_F_MaxAlrmLvl 0 "No_fault" 1 "Alarm_level_1" 2 "Secondary_alarm" 3 "Level_3_alarm" ;
VAL_ 885 MCU_F_SysFltDisp 0 "Normal" 1 "Abnormal" ;
VAL_ 885 MCU_F_SysFltAlrmCtrlSts 0 "No_fault_alarm" 1 "Level_1_fault_alarm_sound" 2 "Secondary_fault_alarm_tone" 3 "Level_3_fault_alarm_tone" ;
VAL_ 885 MCU_F_DrvrMotCrtSts_GB 0 "Reserved_value" 1 "Power_consumption" 2 "Power_generation" 3 "Off_state" 4 "Startup_HV_state" 14 "Init_Values(DBC_Init_Level)" 15 "Signal_not_Valid_(SNV)" ;
VAL_ 886 WTC_B_InlT 255 "Invalid" ;
VAL_ 886 WTC_B_OutlT 255 "Invalid" ;
VAL_ 886 WTC_B_CrtT 255 "Invalid" ;
VAL_ 886 WTC_B_IninSts 0 "initializing" 1 "initialized" ;
VAL_ 886 WTC_B_HVPwrSplySts 0 "No_power_supply" 1 "Power_supply" ;
VAL_ 886 WTC_B_ActGear 0 "Gear_0" 1 "Gear_1" 2 "Gear_2" 3 "Gear_3" 4 "Gear_4" 5 "Gear_5" 6 "Gear_6" ;
VAL_ 886 WTC_B_Mod 0 "Gear_working_mode" 1 "Power_working_mode" ;
VAL_ 887 MCU_R_FltProcLvl 0 "Reserved_value" 3 "Zero_torque" 4 "Reserved" 5 "Power/torque_Limitation_environment_conditions" 6 "normal_operation" 14 "Init_Values" 15 "Invalid" ;
VAL_ 887 MCU_R_MaxAlrmLvl 0 "No_fault" 1 "Alarm_level_1" 2 "Secondary_alarm" 3 "Level_3_alarm" ;
VAL_ 887 MCU_R_SysFltDisp 0 "Normal" 1 "Abnormal" ;
VAL_ 887 MCU_R_SysFltAlrmCtrlSts 0 "No_fault_alarm" 1 "Level_1_fault_alarm_sound" 2 "Secondary_fault_alarm_tone" 3 "Level_3_fault_alarm_tone" ;
VAL_ 887 MCU_R_DrvrMotCrtSts_GB 0 "Reserved_value" 1 "Power_consumption" 2 "Power_generation" 3 "Off_state" 4 "Startup_HV_state" 14 "Init_Values(DBC_Init_Level)" 15 "Signal_not_Valid_(SNV)" ;
VAL_ 889 WTC_H_InpT 255 "Invalid" ;
VAL_ 889 WTC_H_OutpT 255 "Invalid" ;
VAL_ 889 WTC_H_CrtT 255 "Invalid" ;
VAL_ 889 WTC_H_IninSts 0 "initializing" 1 "initialized" ;
VAL_ 889 WTC_H_HVPwrSplySts 0 "No_power_supply" 1 "Power_supply" ;
VAL_ 889 WTC_H_ActGear 0 "Gear_0" 1 "Gear_1" 2 "Gear_2" 3 "Gear_3" 4 "Gear_4" 5 "Gear_5" 6 "Gear_6" ;
VAL_ 889 WTC_H_Mod 0 "Gear_working_mode" 1 "Power_working_mode" ;
VAL_ 896 PKC_CrtUsr 0 "Inactive" 1 "UID_1" 2 "UID_2" 3 "Owner_mobile_phone_account" 4 "Authorized_account_of_owner's_mobile_phone_1" 5 "Authorized_account_of_owner's_mobile_phone_2" 6 "Authorized_account_of_owner's_mobile_phone_3" 7 "Authorized_account_of_owner's_mobile_phone_4" 8 "Authorized_account_of_owner's_mobile_phone_5" 9 "Authorized_account_of_owner's_mobile_phone_6" 10 "Authorized_account_of_owner's_mobile_phone_7" ;
VAL_ 896 PKC_AddNewUserFb 0 "Reserved" 1 "Successful" 2 "Failed" 3 "Invalid" ;
VAL_ 896 PKC_RemovedUserIDFb 0 "Reserved" 1 "Successful" 2 "Failed" 3 "Invalid" ;
VAL_ 896 PKC_UnassignKeyFb 0 "Reserved" 1 "Successful" 2 "Failed" 3 "Invalid" ;
VAL_ 896 PKC_RemoveKeyFb 0 "Reserved" 1 "Successful" 2 "Failed" 3 "Invalid" ;
VAL_ 896 PKC_AuthentFb_PKC 0 "Invalid" 1 "Inactive" 2 "Active" 3 "Reserved" ;
VAL_ 896 PKC_AuthentFb_TBOX 0 "Invalid" 1 "Inactive" 2 "Active" 3 "Reserved" ;
VAL_ 896 PKC_AuthFailPromt 0 "Inactive" 1 "VCU_Authentication_Failure" 2 "Reserved" 3 "Invalid" ;
VAL_ 901 TBOX_PreHeatDepartTi1_Hr 31 "INVALID" ;
VAL_ 901 TBOX_PreHeatDepartTi1_Mins 63 "INVALID" ;
VAL_ 901 TBOX_PreHeatDepartSet 0 "init" 1 "Deactivated" 2 "Start_now" 3 "Start_with_timer" ;
VAL_ 901 TBOX_MonPreHeatDepartSet 0 "Not_repeated" 1 "Repeat" ;
VAL_ 901 TBOX_TuePreHeatDepartSet 0 "Not_repeated" 1 "Repeat" ;
VAL_ 901 TBOX_WedPreHeatDepartSet 0 "Not_repeated" 1 "Repeat" ;
VAL_ 901 TBOX_ThuPreHeatDepartSet 0 "Not_repeated" 1 "Repeat" ;
VAL_ 901 TBOX_FriPreHeatDepartSet 0 "Not_repeated" 1 "Repeat" ;
VAL_ 901 TBOX_SatPreHeatDepartSet 0 "Not_repeated" 1 "Repeat" ;
VAL_ 901 TBOX_SunPreHeatDepartSet 0 "Not_repeated" 1 "Repeat" ;
VAL_ 901 TBOX_PreCdnTarT 255 "Invalid" ;
VAL_ 901 TBOX_PreHeatDepartSetFb 0 "Invalid" 1 "Successful" 2 "Failed" 3 "Reserved" ;
VAL_ 901 TBOX_PreHeatDepartTi2_Hr 31 "INVALID" ;
VAL_ 901 TBOX_PreHeatDepartTi2_Mins 63 "INVALID" ;
VAL_ 923 PKC_SysAlrmVld 0 "System_Warning_Invalid" 1 "System_Warning_Valid" ;
VAL_ 923 PKC_RemCtrlCmdFb 0 "Invalid" 1 "Successful" 2 "Failed" 3 "Processing" ;
VAL_ 923 PKC_RemLockCmd_Key 0 "Inactive" 1 "Lock" 2 "Reserved" 3 "Unlock" 4 "Tailgate_Release(Reserved)" 5 "Panic_(vehicle_finder)" 6 "Tailgate_active" 7 "Tailgate__hallt" 8 "Tailgate_window_UP" 9 "Tailgate_window_DOWN" 10 "California_Mode" 11 "Auto_Unlock" 12 "Auto_Lock" ;
VAL_ 923 PKC_KeyStsMod 0 "Passvive" 1 "Active" ;
VAL_ 923 PKC_KeyID 0 "Initial" 1 "UID1" 2 "UID2" ;
VAL_ 923 PKC_KeyInCarRmn 0 "No_Information" 1 "Key_In_Reminder" ;
VAL_ 923 PKC_RemLockCmd 0 "Inactive" 1 "Lock" 2 "Reserved" 3 "Unlock" 4 "Tailgate_Release(Reserved)" 5 "Panic_(vehicle_finder)" 6 "Tailgate_active" 7 "Tailgate_hallt" 8 "Tailgate_window_UP" 9 "Tailgate_window_DOWN" 10 "California_Mode" 11 "Auto_Unlock" 12 "Auto_Lock" ;
VAL_ 923 PKC_BatterySts 0 "No_Information" 1 "UID_Low_Battery" 2 "Reserved" 3 "Invalid" ;
VAL_ 923 PKC_KeyOutdCarPromt 0 "No_Information" 1 "Key_Out_Reminder" ;
VAL_ 923 PKC_DoorOpenRmd 0 "Reserved" 1 "Active" 2 "Inactive" 3 "Invalid" ;
VAL_ 923 PKC_StrtFailTyp 0 "No_error" 1 "Reserved" 2 "VCU_Authentication_Failure" 3 "Time_Out_(Crank_Off_Time)" 4 "Auth_Pass" ;
VAL_ 923 PKC_LockKeyInCarInd 0 "Reserved" 1 "Active" 2 "Inactive" 3 "Invalid" ;
VAL_ 923 PKC_KeySts 0 "Default_Value" 1 "UID_1_Is_Found" 2 "UID_2_Is_Found" 3 "UID_1,2_Is_Found" ;
VAL_ 1136 EPS_IninSts 0 "Incomplete_initialization" 1 "initialization_completed" ;
VAL_ 1136 EPS_CrtSts 0 "Normal_operating_state" 1 "Fault_state" ;
VAL_ 1136 EPS_FltIndcn 0 "Normal" 1 "Fault_state" ;
VAL_ 1136 EPS_SteerWhlBackStsFb 0 "Standby" 1 "Not_completed" 2 "Completed" 3 "Reserved" ;
VAL_ 1136 EPS_TqSnsrSigErr 0 "Normal" 1 "Abnormal" ;
VAL_ 1136 EPS_SteerAgSnsrFlt 0 "Normal" 1 "Abnormal" ;
VAL_ 1136 EPS_TSnsrFlt 0 "Normal" 1 "Abnormal" ;
VAL_ 1136 EPS_ComLostFlt_ESP 0 "Normal" 1 "Abnormal" ;
VAL_ 1136 EPS_SpdDataErr 0 "Normal" 1 "Abnormal" ;
VAL_ 1136 EPS_HwFlt 0 "Normal" 1 "Abnormal" ;
VAL_ 1136 EPS_RlyFlt 0 "Normal" 1 "Abnormal" ;
VAL_ 1136 EPS_MotPosnSnsrFlt 0 "Normal" 1 "Abnormal" ;
VAL_ 1136 EPS_SteerAgSnsrNotCalFlt 0 "Normal" 1 "Abnormal" ;
VAL_ 1136 EPS_MotCrtFlt 0 "Normal" 1 "Abnormal" ;
VAL_ 1169 EAS_HVUnderVoltFlt 0 "Normal" 1 "Abnormal" ;
VAL_ 1169 EAS_HVOverVoltFlt 0 "Normal" 1 "Abnormal" ;
VAL_ 1169 EAS_CrtSts 0 "Standby" 1 "Working" 2 "Fault" 3 "Reserved" ;
VAL_ 1169 EAS_IninSts 0 "initializing" 1 "initialized" ;
VAL_ 1169 EAS_OverCrtFlt 0 "Normal" 1 "Abnormal" ;
VAL_ 1169 EAS_HVIntlkFlt 0 "Normal" 1 "Abnormal" ;
VAL_ 1169 EAS_IPMTOverFlt 0 "Normal" 1 "Abnormal" ;
VAL_ 1169 EAS_ComLost_ECC 0 "Normal" 1 "Abnormal" ;
VAL_ 1169 EAS_CtrlCircFlt 0 "Normal" 1 "Abnormal" ;
VAL_ 1169 EAS_IPMHwFlt 0 "Normal" 1 "Abnormal" ;
VAL_ 1283 VCU_FltAlrmCtrlSts 0 "No_fault" 1 "Level_1_fault" 2 "Secondary_fault" 3 "Level_III_fault" ;
VAL_ 1283 VCU_VehMaxAlrmLvl 0 "No_fault" 1 "Level_1_fault" 2 "Secondary_fault" 3 "Level_III_fault" ;
VAL_ 1283 VCU_BrkStrtReq 0 "not_displayed" 1 "text_display" ;
VAL_ 1283 VCU_PerKmFlg 0 "Not_Reached_per_km" 1 "flag_bit_per_kilometer" ;
VAL_ 1283 VCU_TrvlModSetRes 0 "Initial_value" 1 "Daily_commuter_mode" 2 "Long-distance_travel_mode" 3 "Reserved" ;
VAL_ 1284 VCU_MonrPwrBattThermRunawayAlrm 0 "Normal" 1 "Alarm" ;
VAL_ 1284 VCU_ShiftOperRmn 0 "Initial_value" 1 "please_slow_down_before_shifting" 2 "Confirm_vehicle_READY_before_shifting" 3 "please_shift_with_brake_pedal" 4 "gear_shifting_conditions_not_met" 5 "cannot_be_shifted_during_charging" 10 "please_switch_gear_to_gear_P" 11 "please_shift_gear_to_N_gear" ;
VAL_ 1284 VCU_MCUFOverSpdAlrm 0 "Invalid" 1 "Valid" ;
VAL_ 1284 VCU_MCUROverSpdAlrm 0 "Invalid" 1 "Valid" ;
VAL_ 1284 VCU_MCUFSysOverTDisp 0 "Normal" 1 "Abnormal" ;
VAL_ 1284 VCU_MCURSysOverTDisp 0 "Normal" 1 "Abnormal" ;
VAL_ 1284 VCU_VehSysFltLamp 0 "Normal_lamp_off" 1 "Abnormal_illumination" ;
VAL_ 1284 VCU_MotSysFltLamp 0 "Light_out" 1 "light_on" ;
VAL_ 1284 VCU_RmnUsrClsECCDispCmd 0 "Not_displayed" 1 "Display" ;
VAL_ 1284 VCU_PPrkgFltLvl 0 "No_fault" 1 "Level_1_fault" 2 "Secondary_fault" 3 "Level_III_fault" 4 "Level_4_fault" ;
VAL_ 1284 VCU_RmnUsrECCFctLmtDispCmd 0 "No_display" 1 "Display" ;
VAL_ 1284 VCU_DrvRngVld 0 "Initializing" 1 "Valid" 2 "Invalid" 3 "Reserved" ;
VAL_ 1284 VCU_VirtEgyRecovInten 0 "Not_set" 1 "1st_gear_energy_recovery" 2 "2nd_gear_energy_recovery" 3 "3rd_gear_energy_recovery" ;
VAL_ 1285 VCU_EgyRecovForbnFlg 0 "Energy_recovery_allowed" 1 "No_energy_recovery" ;
VAL_ 1285 VCU_DrvPwrLimIndcrLamp 0 "Light_out" 1 "light_on" ;
VAL_ 1285 VCU_PPrkgSysFltIndcn 0 "Normal" 1 "Abnormal" ;
VAL_ 1285 VCU_GearSysFltIndcn 0 "Normal" 1 "Abnormal" ;
VAL_ 1285 VCU_SocLoRmn 0 "Disable" 1 "Enable" ;
VAL_ 1285 VCU_BattFltIndcn 0 "Normal" 1 "Abnormal" ;
VAL_ 1285 VCU_ChrgIndcrLamp 0 "Light_out" 1 "light_on" ;
VAL_ 1285 VCU_VehEgyFlow 0 "Shutdown" 1 "Ready" 2 "Drive" 3 "Energy_recovery" 4 "Fast_charge" 5 "Slow_charge" ;
VAL_ 1285 VCU_ChrgDchaGunCnctnIndcrLamp 0 "Light_out" 1 "light_on" ;
VAL_ 1285 VCU_InsntEgyCnseUnitSwtFlg 0 "Kwh/100_km_displayed" 1 "Kwh/h_is_displayed" ;
VAL_ 1285 VCU_ChrgGunStrt 0 "not_displayed" 1 "text_display" ;
VAL_ 1292 VCU_DrvTqLimSts 1 "External_characteristic_limits" 2 "Power_limit" 3 "Reserved" 4 "10KW_power_limit" 8 "Over-temperature_limit_torque" 16 "Zero_torque_limit_torque" 32 "vacuum_pump_speed_limit" 64 "Maximum_speed_limit_torque" 128 "Base_speed_limit" 256 "Battery_voltage_low_speed_limit" 511 "All_limit_effect" ;
VAL_ 1292 VCU_EgyRecovTqLimSts 1 "BMS_recovery_power_limit" 2 "External_characteristic_limit_of_motor" 4 "Maximum_recovery_torque_limit_of_motor" 8 "IGBTs_and_motor_temperature_limits" 16 "slip_limit" 32 "bus_voltage_limit" 64 "ABS_activation_limit" 128 "ABS_communication_loss_limit_and_fault_limit" 256 "BMS_cell_overvoltage_limit" 512 "Total_Overvoltage" 1023 "All_limit_effect" ;
VAL_ 1297 VCU_BMSLVWakeUpSts 0 "Not_waken_up" 1 "waken_up" ;
VAL_ 1297 VCU_ONWakeUpSig 0 "Not_waken_up" 1 "waken_up" ;
VAL_ 1297 VCU_FCWakeUpSig 0 "Not_waken_up" 1 "waken_up" ;
VAL_ 1297 VCU_SCWakeUpSig 0 "Not_waken_up" 1 "waken_up" ;
VAL_ 1297 VCU_RemWakeUpSig 0 "Not_waken_up" 1 "waken_up" ;
VAL_ 1297 VCU_NetWakeUpSig 0 "Not_waken_up" 1 "waken_up" ;
VAL_ 1297 VCU_LVWakeUpSts_PDU 0 "Not_waken_up" 1 "waken_up" ;
VAL_ 1297 VCU_VehEOLFctFlg 0 "Normal_mode" 1 "EOL_mode" ;
VAL_ 1297 VCU_LVWakeUpSts_MCU 0 "Not_waken_up" 1 "waken_up" ;
VAL_ 1297 VCU_PwrAntithefAllwtRdyFlg 0 "READY_allowed" 1 "READY_not_allowed" ;
VAL_ 1297 VCU_LVWakeUpSts_CCU 0 "Not_waken_up" 1 "waken_up" ;
VAL_ 1297 VCU_RemECCEndCmd 0 "Not_ended" 1 "End" ;
VAL_ 1297 VCU_EvChrgElectcLockCtrlCmd 0 "Initial_value" 1 "locking_command_state" 2 "Unlocking_command_state" 3 "Invalid" ;
VAL_ 1297 VCU_RemPwrBattHeatgEndCmd 0 "Not_ended" 1 "End" ;
VAL_ 1297 VCU_RemChrgEndCmd 0 "Not_ended" 1 "End" ;
VAL_ 1297 VCU_V2L_TrAvl 0 "No" 1 "Yes" ;
VAL_ 1297 VCU_RemBattHeatgFailReason 0 "Initial_value" 1 "Current_ambient_battery_disabled_discharge" 2 "Low_SOC" 3 "vehicle_at_ON_gear" 4 "Vehicle_fault" 5 "The_temp_meets_requ,_there_is_no_need_to_remotely_heat_in_the_discharg_state" ;
VAL_ 1297 VCU_RemECCEndReason 0 "Initial_value" 1 "When_the_SOC_of_the_vehicle_is_lower_than_5%,_the_remote_A/C_is_prohibited." 2 "The_vehicle_is_powered_on,_and_the_remote_A/C_is_prohibited." 3 "The_A/C_system_of_the_vehicle_is_abnormal,_and_the_remote_A/C_is_prohibited." 4 "Please_turn_on_after_AC_charging_or_preheating_or_insulation" ;
VAL_ 1297 VCU_V2L_ChrgPortAvl 0 "No" 1 "Yes" ;
VAL_ 1297 VCU_RemChrgEndReason 0 "Initial_value" 1 "abnormal_charging_system,_charging_disabled" 2 "Charging_gun_is_not_connected,_charging_is_not_turned_on" 3 "Supply_equipment_is_not_supported,_and_charging_is_forbidden." ;
VAL_ 1297 VCU_SchedChrgnStsFb 0 "Idle" 1 "Successful" 2 "Failed" 3 "Processing" ;
VAL_ 1297 VCU_V2V_Avl 0 "No" 1 "Yes" ;
VAL_ 1297 VCU_V2H_Avl 0 "No" 1 "Yes" ;
VAL_ 1297 VCU_V2G_Avl 0 "No" 1 "Yes" ;
VAL_ 1297 VCU_VehMod 0 "None" 1 "THM_Preconditioning" 2 "LV_Energy_Management_during_Parking" 3 "HV_Energy_management_during_Parking" 4 "Remote_HVAD_request" 5 "V2L_Dongle" 6 "V2L_Trunc" 7 "V2V" 8 "OTA" 9 "Workshop_Mode" 10 "LV_Energy_Management_during_Wakeup" 13 "Error" 14 "Initialization" 15 "Invalid" ;
VAL_ 1297 VCU_CalSwVers 0 "Reserved" 1 "G6-1" 2 "G6-2" 3 "G6-3" 4 "G6-4" 5 "G6-5" 6 "G6-6" 7 "G6-7" 8 "G6-8" 9 "G6-9" 10 "Reserved" 11 "G4-1" 12 "G4-2" 13 "G4-3" 14 "G4-4" 15 "G4-5" 16 "G4-6" 17 "G4-7" 18 "G4-8" 19 "G4-9" 20 "Reserved" 21 "G3-1" 22 "G3-2" 23 "G3-3" 24 "G3-4" 25 "G3-5" 26 "G3-6" 27 "G3-7" 28 "G3-8" 29 "G3-9" ;
VAL_ 1297 VCU_RemPwrBattPreheatgEndFlg 0 "Not_ended" 1 "End" ;
VAL_ 1297 VCU_VehOperMod 0 "Reserved" 1 "gear_P" 2 "gear_N" 3 "gear_D" 4 "gear_R" 5 "E_position" 6 "zero_torque_transition" 7 "Idle_at_gear_D" 8 "gear_R_idle" 9 "gear_D_coastdown_feedback" 10 "gear_D_braking_feedback" 11 "gear_E_coastdown_feedback" 12 "gear_E_braking_feedback" 13 "D_gear_limp_condition" 14 "R_gear_limp_condition" 15 "immediately_off_high-voltage_condition" 16 "High_voltage_off_delay" 17 "Cruise" 18 "gear_N_limp" 19 "Zero_torque" 20 "gear_S" 21 "Remote_driving_condition" ;
VAL_ 1297 VCU_VehRemRefrshModReq 0 "Initial_value" 1 "Remote_high_voltage_flash" 2 "Remote_low_voltage_flash-writing" 3 "Void" ;
VAL_ 1297 VCU_RemDTCPwrOnReq 0 "No_demand" 1 "In_demand" ;
VAL_ 1312 DCDC_OutpCrt 65535 "Invalid" ;
VAL_ 1312 DCDC_InpVolt 65535 "Invalid" ;
VAL_ 1312 DCDC_InpCrt 255 "Invalid" ;
VAL_ 1312 DCDC_OutpVolt 255 "Invalid" ;
VAL_ 1317 TBOX_GPSHei 1401 "Invalid" ;
VAL_ 1318 TBOX_GPSLongi 4294967295 "Invalid" ;
VAL_ 1318 TBOX_GPSLati 4294967295 "Invalid" ;
VAL_ 1319 ADAS_DrvrAttention_Zone 0 "UNKNOWN" 1 "ON_ROAD_CENTER" 2 "ON_ROAD_RIGHT" 3 "INSTRUMENT_CLUSTER" 4 "CENTER_CONSOLE" 5 "REAR_MIRROR" 6 "DRIVER_MIRROR" 7 "PASSENGER_MIRROR" 8 "DRIVER_LAP" 9 "PASSENGER_FOOTWELL" 10 "CUSTOM" 11 "OTHER" 12 "Not_Used_1" 13 "Not_Used_2" 14 "Not_Used_3" 15 "FAULTY" ;
VAL_ 1319 ADAS_DrvrAlert_State 0 "UNKNOWN" 1 "EYES_OPEN_ON_ROAD" 2 "EYES_OPEN_OFF_ROAD" 3 "EYES_CLOSED_OFF_ROAD" 4 "FAULTY" ;
VAL_ 1319 ADAS_DMS_Camera_Blockage_Status 0 "UNKNOWN" 1 "OK" 2 "BLOCKED" 3 "FAULTY" ;
VAL_ 1319 ADAS_DrvrEngagement_Level_Status 0 "UNKNOWN" 1 "ATTENTIVE" 2 "INATTENTIVE" 3 "DISTRACTED" 4 "DISENGAGED" 5 "NotUsed_1" 6 "NotUsed_2" 7 "FAULTY" ;
VAL_ 1319 ADAS_DMS_IR_Blockage_Status 0 "UNKNOWN" 1 "OK" 2 "BLOCKED" 3 "FAULTY" ;
VAL_ 1319 ADAS_DrvrEngagement_Level_Conf 0 "UNKNOWN" 1 "LOW" 2 "LOW_MEDIUM" 3 "MEDIUM" 4 "MEDIUM_HIGH" 5 "HIGH" 6 "NotUsed" 7 "FAULTY" ;
VAL_ 1319 ADAS_DrvrImpairment_Level_Stat 0 "UNKNOWN" 1 "ALERT" 2 "DROWSY" 3 "MICROSLEEP" 4 "ASLEEP" 5 "NotUsed_1" 6 "NotUsed_2" 7 "FAULTY" ;
VAL_ 1319 ADAS_DrvrImpairment_Level_Conf 0 "UNKNOWN" 1 "LOW" 2 "LOW_MEDIUM" 3 "MEDIUM" 4 "MEDIUM_HIGH" 5 "HIGH" 6 "NotUsed" 7 "FAULTY" ;
VAL_ 1319 ADAS_DrvrDrowsiness_Level 0 "UNKNOWN" 1 "NOT_DROWSY" 2 "DROWSY_1" 3 "DROWSY_2" 4 "DROWSY_3" 5 "DROWSY_4" 6 "DROWSY_5" 7 "DROWSY_6" 8 "DROWSY_7" 9 "DROWSY_8" 10 "DROWSY_9" 11 "DROWSY_10" 12 "NotUsed_1" 13 "NotUsed_2" 14 "NotUsed_3" 15 "FAULTY" ;
VAL_ 1319 ADAS_DCAA_DrvrDrowsinessVld 0 "No_confidence" 1 "Low_confidence" 2 "Medium_confidence" 3 "High_confidence" ;
VAL_ 1319 ADAS_DCAA_DrvrAttentionLvl 0 "No_level_detected" 1 "Attention_ok" 2 "A_ttention_not_OK" 3 "Reserved" ;
VAL_ 1319 ADAS_DCAA_DrvrAttentionVld 0 "No_confidence" 1 "Low_confidence" 2 "Medium_confidence" 3 "High_confidence" ;
VAL_ 1319 ADAS_DCAA_DrvrDrowsinessLvl 0 "No_level_deteced" 1 "Extremely_Alert" 2 "Very_Alert" 3 "Alert" 4 "Rather_alert" 5 "Neither_alert_nor_sleepy" 6 "Some_signs_of_sleepiness" 7 "Sleepy_no_effort_to_keep_awake" 8 "Sleepy_some_effort_to_keep_awake" 9 "Very_sleepy_great_effort_to_keep_awake_fighting_sleep" ;
VAL_ 1319 ADAS_DMSDrvrDetn 0 "Inactive" 1 "Unknown" 2 "No_Driver" 3 "Fake_Driver" 4 "Real_Driver" 5 "Real_Driver_Fake_Eyes" 6 "Possible_Driver" 7 "Faulty" ;
VAL_ 1319 ADAS_DMS_IRSts 0 "Inactive" 1 "Active" ;
VAL_ 1322 ICC_FACM_DynmcSenstvty 0 "On" 1 "Off" ;
VAL_ 1322 ICC_UsrProfTiGapSet 0 "Invalid" 1 "TimeGap_1_shortest" 2 "TimeGap_2" 3 "TimeGap_3" 4 "TimeGap_4_longest" ;
VAL_ 1322 ICC_LKA_Setting 0 "Off" 1 "Warning_only" 2 "Warning_and_Steering" 3 "Reserved" ;
VAL_ 1322 ICC_FACM_Setting 0 "Off" 1 "Warning_only" 2 "Warning_and_Brake" 3 "Reserved" ;
VAL_ 1322 ICC_AEB_Sensitivity 0 "Normal" 1 "Early" 2 "Late_or_reduced" 3 "Reserved" ;
VAL_ 1322 ICC_BACM_Setting 0 "Off" 1 "Warning_only" 2 "Warning_and_Brake" 3 "Reserved" ;
VAL_ 1322 ICC_BACM_Sensitivity 0 "Normal" 1 "Early" 2 "Late_or_reduced" 3 "Reserved" ;
VAL_ 1322 ICC_AEB_JerkSetReq 0 "Off" 1 "On(Default)" ;
VAL_ 1322 ICC_ActvStyGlblSetting 0 "On" 1 "Off" ;
VAL_ 1322 ICC_TSR_Setting 0 "Off" 1 "On" ;
VAL_ 1322 ICC_ESA_Setting 0 "Off" 1 "On" ;
VAL_ 1322 ICC_ELKASteeringInterventionSet 0 "Off" 1 "On" ;
VAL_ 1322 ICC_LaneTrajectorySetting 0 "Off" 1 "On" ;
VAL_ 1322 ICC_ACCSwt 0 "Invalid" 1 "On" 2 "Off" 3 "reserved" ;
VAL_ 1322 ICC_ACCAutoSpdSts 0 "Off" 1 "On" ;
VAL_ 1322 ICC_ACCSpdStepSize 0 "Step_1_unit" 1 "Step_5_unit" ;
VAL_ 1322 ICC_ACCFuncTyp 0 "Default" 1 "Basic" 2 "Advanced" 3 "ISA" 4 "Fault" ;
VAL_ 1322 ICC_ACCSpdLimOffsTyp 0 "Exceeding_limit_not_allowed" 1 "Percentage" 2 "Speed_value" 3 "Reserved" ;
VAL_ 1322 ICC_ACCTerrainSetting 0 "Not_enabled" 1 "Enabled" ;
VAL_ 1322 ICC_ACCTiGapCfm 0 "Default/No_Selection" 1 "Driver_Accepted" 2 "Driver_Rejected" 3 "Reserved" ;
VAL_ 1322 ICC_ISASetting 0 "Off" 1 "Display_Warning_Only" 2 "Display_and_chime_warning" 3 "Display_and_Control" 4 "Display_and_chime_Warning_+_Control" ;
VAL_ 1322 ICC_FCTA_Sensitivity 0 "Normal" 1 "Early" 2 "Late_or_reduced" 3 "Reserved" ;
VAL_ 1322 ICC_ISAWarnStopReq 0 "No_Driver_ISA_warning_stop_request_(User_not_acknowledged)" 1 "Driver_ISA_warning_stop_request_(User_acknowledged)" ;
VAL_ 1322 ICC_TLR_Setting 0 "Off" 1 "On" 2 "chime_warning" 3 "chime_red_light" 4 "chime_green_light" ;
VAL_ 1322 ICC_FCTA_Setting 0 "Off" 1 "Warning_only" 2 "Warning_and_Brake" 3 "Reserved" ;
VAL_ 1337 BCM_LePosnLampFlt 0 "Not_Failed" 1 "Failed" ;
VAL_ 1337 BCM_RiPosnLampFlt 0 "Not_Failed" 1 "Failed" ;
VAL_ 1337 BCM_LeLoBeamFlt 0 "Not_Failed" 1 "Failed" ;
VAL_ 1337 BCM_RiLoBeamFlt 0 "Not_Failed" 1 "Failed" ;
VAL_ 1337 BCM_LeHiBeamFlt 0 "Not_Failed" 1 "Failed" ;
VAL_ 1337 BCM_RiHiBeamFlt 0 "Not_Failed" 1 "Failed" ;
VAL_ 1337 BCM_LeDRLFlt 0 "Not_Failed" 1 "Failed" ;
VAL_ 1337 BCM_RiDRLFlt 0 "Not_Failed" 1 "Failed" ;
VAL_ 1337 BCM_LeFrntFogLampFlt 0 "Not_Failed" 1 "Failed" ;
VAL_ 1337 BCM_RiFrntFogLampFlt 0 "Not_Failed" 1 "Failed" ;
VAL_ 1337 BCM_ReFogLampFlt 0 "Not_Failed" 1 "Failed" ;
VAL_ 1337 BCM_LoBrkLampFlt 0 "Not_Failed" 1 "Failed" ;
VAL_ 1337 BCM_HiBrkLampFlt 0 "Not_Failed" 1 "Failed" ;
VAL_ 1337 BCM_RvsLampFlt 0 "Not_Failed" 1 "Failed" ;
VAL_ 1337 BCM_LeTurnLampFlt 0 "Not_Failed" 1 "Failed" ;
VAL_ 1337 BCM_RiTurnLampFlt 0 "Not_Failed" 1 "Failed" ;
VAL_ 1337 BCM_LicPlateLampFlt 0 "Not_Failed" 1 "Failed" ;
VAL_ 1337 BCM_ElWiperMotorFlt 0 "Not_Failed" 1 "Failed" ;
VAL_ 1337 BCM_No_key_found_warning 0 "validkey_found" 1 "No_validkey_found" ;
VAL_ 1408 VCU_ActChrgTotAh 65535 "Invalid" ;
VAL_ 1408 VCU_ActDchgTotAh 65535 "Invalid" ;
VAL_ 1408 VCU_PwrBattAvlEgy 65535 "Invalid" ;
VAL_ 1410 ECC_InsdT 255 "Invalid" ;
VAL_ 1410 ECC_RemPwrCnsEstim 255 "Invalid" ;
VAL_ 1410 ECC_RemTSetSts 0 "Inactive" 36 "18??C" 37 "18.5??C" 38 "19??C" 39 "19.5??C" 40 "20??C" 41 "20.5??C" 42 "21??C" 43 "21.5??C" 44 "22??C" 45 "22.5??C" 46 "23??C" 47 "23.5??C" 48 "24??C" 49 "24.5??C" 50 "25??C" 51 "25.5??C" 52 "26??C" 53 "26.5??C" 54 "27??C" 55 "27.5??C" 56 "28??C" 57 "28.5??C" 58 "29??C" 59 "29.5??C" 60 "30??C" 61 "30.5??C" 62 "31??C" 63 "31.5??C" 64 "32??C" 255 "Invalid" ;
VAL_ 1410 ECC_RemDefrstSts 0 "Off" 1 "On" ;
VAL_ 1410 ECC_BattFldLvlSnsrLamp 0 "Lamp_off" 1 "Lamp_on" 2 "Reserved" 3 "Invalid" ;
VAL_ 1436 VCU_LowMilg_Warn 0 "above_50_miles-no_warning" 1 "21-50_miles_warning_(acoustic_and_amber_alert)" 2 "2-20_miles_warning_(acoustic_and_red_alert)" ;
VAL_ 1436 VCU_LowMilgRemAlrm 0 "Init" 1 "Soft_warning" 2 "Strict_alarm" 3 "Invalid" ;
VAL_ 1444 VCU_HVEM_PwrCoorrPrio 0 "Init" 1 "PDF1" 2 "PDF2" 3 "PDF3" ;
VAL_ 1554 ICC_NavGuidanceInfo 0 "no_message" ;
VAL_ 1555 ICC_ResvTrvlStrtSet 0 "Initial_value" 1 "On" 2 "Cancel" 3 "Reserved" ;
VAL_ 1556 ICC_ResvACChrgStrtSet 0 "Initial_value" 1 "On" 2 "Cancel" 3 "Reserved" ;
VAL_ 1556 ICC_MonResvACChrgRepStrtSet 0 "Not_repeated" 1 "Repeat" ;
VAL_ 1556 ICC_TueResvACChrgRepStrtSet 0 "Not_repeated" 1 "Repeat" ;
VAL_ 1556 ICC_WedResvACChrgRepStrtSet 0 "Not_repeated" 1 "Repeat" ;
VAL_ 1556 ICC_ThuResvACChrgRepStrtSet 0 "Not_repeated" 1 "Repeat" ;
VAL_ 1556 ICC_FriResvACChrgRepStrtSet 0 "Not_repeated" 1 "Repeat" ;
VAL_ 1556 ICC_SatResvACChrgRepStrtSet 0 "Not_repeated" 1 "Repeat" ;
VAL_ 1556 ICC_SunResvACChrgRepStrtSet 0 "Not_repeated" 1 "Repeat" ;
VAL_ 1556 ICC_ResvACChrgEndSet 0 "Initial_value" 1 "On" 2 "Cancel" 3 "Reserved" ;
VAL_ 1556 ICC_MonResvACChrgRepEndSet 0 "Not_repeated" 1 "Repeat" ;
VAL_ 1556 ICC_TueResvACChrgRepEndSet 0 "Not_repeated" 1 "Repeat" ;
VAL_ 1556 ICC_WedResvACChrgRepEndSet 0 "Not_repeated" 1 "Repeat" ;
VAL_ 1556 ICC_ThuResvACChrgRepEndSet 0 "Not_repeated" 1 "Repeat" ;
VAL_ 1556 ICC_FriResvACChrgRepEndSet 0 "Not_repeated" 1 "Repeat" ;
VAL_ 1556 ICC_SatResvACChrgRepEndSet 0 "Not_repeated" 1 "Repeat" ;
VAL_ 1556 ICC_SunResvACChrgRepEndSet 0 "Not_repeated" 1 "Repeat" ;
VAL_ 1581 TBOX_ResvTrvlStrtSts 0 "Initial_value" 1 "On" 2 "Cancel" 3 "Reserved" ;
VAL_ 1582 TBOX_MonResvACChrgRepStrtSet 0 "Not_repeated" 1 "Repeat" ;
VAL_ 1582 TBOX_TueResvACChrgRepStrtSet 0 "Not_repeated" 1 "Repeat" ;
VAL_ 1582 TBOX_WedResvACChrgRepStrtSet 0 "Not_repeated" 1 "Repeat" ;
VAL_ 1582 TBOX_ThuResvACChrgRepStrtSet 0 "Not_repeated" 1 "Repeat" ;
VAL_ 1582 TBOX_FriResvACChrgRepStrtSet 0 "Not_repeated" 1 "Repeat" ;
VAL_ 1582 TBOX_SatResvACChrgRepStrtSet 0 "Not_repeated" 1 "Repeat" ;
VAL_ 1582 TBOX_SunResvACChrgRepStrtSet 0 "Not_repeated" 1 "Repeat" ;
VAL_ 1582 TBOX_ResvACChrgEndSet 0 "Initial_value" 1 "On" 2 "Off" 3 "Reserved" ;
VAL_ 1582 TBOX_MonResvACChrgRepEndSet 0 "Not_repeated" 1 "Repeat" ;
VAL_ 1582 TBOX_TueResvACChrgRepEndSet 0 "Not_repeated" 1 "Repeat" ;
VAL_ 1582 TBOX_WedResvACChrgRepEndSet 0 "Not_repeated" 1 "Repeat" ;
VAL_ 1582 TBOX_ThuResvACChrgRepEndSet 0 "Not_repeated" 1 "Repeat" ;
VAL_ 1582 TBOX_FriResvACChrgRepEndSet 0 "Not_repeated" 1 "Repeat" ;
VAL_ 1582 TBOX_SatResvACChrgRepEndSet 0 "Not_repeated" 1 "Repeat" ;
VAL_ 1582 TBOX_SunResvACChrgRepEndSet 0 "Not_repeated" 1 "Repeat" ;
VAL_ 1584 VCU_CellTotVolt 65535 "Invalid" ;
VAL_ 1584 VCU_ACRmngChrgTi 65535 "Invalid" ;
VAL_ 1588 VCU_ACChrgShttrSts 0 "Off" 1 "On" ;
VAL_ 1588 VCU_DCChrgShttrSts 0 "Off" 1 "On" ;
VAL_ 1588 VCU_SCPwrSplyEquipFactry 0 "Initial_value" 1 "Non-BJEV_power_supply" 2 "BJEV_portable_charger_as_per_the_original_national_standards" 3 "BJEV_charging_equipment_as_per_the_new_national_standards" ;
VAL_ 1601 BCM_MilgDataVld_ODO 0 "Value_OK" 1 "Value_Unreliable" ;
VAL_ 1601 BCM_MilgRstCntr_ODO 0 "Not_cleared" 1 "1_clearing" 2 "Clean_2_times" 3 "Clean_3_times" ;
VAL_ 1604 ECC_ReMotOutlT 255 "Invalid" ;
VAL_ 1604 ECC_CoolgDfct 0 "Active" 1 "Inactive" ;
VAL_ 1604 ECC_CooltHomSts 0 "not_homogenized" 1 "homogenized" ;
VAL_ 1604 ECC_PDUInlT 255 "Invalid" ;
VAL_ 1604 ECC_FrntMotOutlT 255 "Invalid" ;
VAL_ 1604 ECC_MCURInlT 255 "Invalid" ;
VAL_ 1605 ECC_DefrstAirOutlTSnsrFlt 0 "Normal" 1 "Abnormal" ;
VAL_ 1605 ECC_ComLost_EAS 0 "Normal" 1 "Abnormal" ;
VAL_ 1605 ECC_OutdTSnsrFlt 0 "Normal" 1 "Abnormal" ;
VAL_ 1605 ECC_InsdTSnsrFlt 0 "Normal" 1 "Abnormal" ;
VAL_ 1605 ECC_EvaprTSnsrFlt 0 "Normal" 1 "Abnormal" ;
VAL_ 1605 ECC_IntExtCircMotFlt 0 "Normal" 1 "Abnormal" ;
VAL_ 1605 ECC_LeModThrMotFlt 0 "Normal" 1 "Abnormal" ;
VAL_ 1605 ECC_RiModThrMotFlt 0 "Normal" 1 "Abnormal" ;
VAL_ 1605 ECC_CtrlrFlt 0 "Normal" 1 "Abnormal" ;
VAL_ 1605 ECC_PDUInlTSnsrFlt 0 "Normal" 1 "Abnormal" ;
VAL_ 1605 ECC_FrntMotOutlTSnsrFlt 0 "Normal" 1 "Abnormal" ;
VAL_ 1605 ECC_ReMotOutlTSnsrFlt 0 "Normal" 1 "Abnormal" ;
VAL_ 1605 ECC_ComLost_CDS 0 "Normal" 1 "Abnormal" ;
VAL_ 1605 ECC_ComLost_WTC_H 0 "Normal" 1 "Abnormal" ;
VAL_ 1605 ECC_ComLost_WTC_B 0 "Normal" 1 "Abnormal" ;
VAL_ 1605 ECC_HPTSnsrFlt 0 "Normal" 1 "Abnormal" ;
VAL_ 1605 ECC_LPTSnsrFlt 0 "Normal" 1 "Abnormal" ;
VAL_ 1605 ECC_BlowFaceLeAirOutlTSnsrFlt 0 "Normal" 1 "Abnormal" ;
VAL_ 1605 ECC_BlowFaceRiAirOutlTSnsrFlt 0 "Normal" 1 "Abnormal" ;
VAL_ 1605 ECC_ReBlowFaceFootMotFlt 0 "Normal" 1 "Abnormal" ;
VAL_ 1605 ECC_HPSnsrFlt 0 "Normal" 1 "Abnormal" ;
VAL_ 1605 ECC_LPSnsrFlt 0 "Normal" 1 "Abnormal" ;
VAL_ 1605 ECC_HeatPmpHeatgEXVFlt 0 "Normal" 1 "Abnormal" ;
VAL_ 1605 ECC_BattCoolgEXVFlt 0 "Normal" 1 "Abnormal" ;
VAL_ 1605 ECC_BlowFootLeAirOutlTSnsrFlt 0 "Normal" 1 "Abnormal" ;
VAL_ 1605 ECC_BlowFootRiAirOutlTSnsrFlt 0 "Normal" 1 "Abnormal" ;
VAL_ 1605 ECC_LeHybThrMotFlt 0 "Normal" 1 "Abnormal" ;
VAL_ 1605 ECC_RiHybThrMotFlt 0 "Normal" 1 "Abnormal" ;
VAL_ 1605 ECC_MCURInlTSnsrFlt 0 "Normal" 1 "Abnormal" ;
VAL_ 1605 ECC_ComLost_EWP_FD 0 "Normal" 1 "Abnormal" ;
VAL_ 1605 ECC_ComLost_EWP_RD 0 "Normal" 1 "Abnormal" ;
VAL_ 1605 ECC_ComLost_EWP_H 0 "Communication_normal" 1 "Communication_abnormal" ;
VAL_ 1605 ECC_ComLost_EWP_B 0 "Communication_normal" 1 "Communication_abnormal" ;
VAL_ 1605 ECC_ComLost_EXV_B 0 "Communication_normal" 1 "Communication_abnormal" ;
VAL_ 1605 ECC_ComLost_EXV_H 0 "Communication_normal" 1 "Communication_abnormal" ;
VAL_ 1605 ECC_ComLost_CFM 0 "Communication_normal" 1 "Communication_abnormal" ;
VAL_ 1605 ECC_ComLost_AGS 0 "Communication_normal" 1 "Communication_abnormal" ;
VAL_ 1605 ECC_ComLost_CVM 0 "Communication_normal" 1 "Communication_abnormal" ;
VAL_ 1605 ECC_ComLost_MDV 0 "Communication_normal" 1 "Communication_abnormal" ;
